VERSION ""

NS_ :

BS_:

BU_: BSM BSM2 CADM CVADAS ECM EPS EVCU2 ORC
BO_ 205 BRAKE_FD_6: 64 BSM
 SG_ Cmnd_TotBrkFrict_AxleTorq : 126|15@0+ (2,0) [0|65532] "Nm" EVCU2
 SG_ CRC_BRAKE_FD_6 : 447|8@0+ (1,0) [0|255] "-" ECM,EVCU2
 SG_ DriverReq_AxleTrq_Enabled_BSM : 175|4@0+ (1,0) [0|15] "" CVADAS,ECM,EVCU2
 SG_ DriverRequested_AxleTrq_BSM : 159|16@0+ (2,-65534) [-65534|65536] "Nm" ECM,EVCU2
 SG_ DrvrIntd_TotalBrk_AxleTorq : 142|15@0+ (2,0) [0|65532] "Nm" EVCU2
 SG_ FrontAxle_Max_Rq_BSM : 55|1@0+ (1,0) [0|1] "" EVCU2
 SG_ FrontAxle_Min_Rq_BSM : 54|1@0+ (1,0) [0|1] "" EVCU2
 SG_ FrontAxle_Rq_BSM : 63|16@0+ (2,-65534) [-65534|65536] "Nm" EVCU2
 SG_ MessageCounter_BRAKE_FD_6 : 435|4@0+ (1,0) [0|15] "-" ECM,EVCU2
 SG_ RearAxle_Max_Rq_BSM : 53|1@0+ (1,0) [0|1] "" EVCU2
 SG_ RearAxle_Min_Rq_BSM : 52|1@0+ (1,0) [0|1] "" EVCU2
 SG_ RearAxle_Rq_BSM : 79|16@0+ (2,-65534) [-65534|65536] "Nm" EVCU2
 SG_ TotalAxle_Max_Rq_BSM : 51|1@0+ (1,0) [0|1] "" ECM,EVCU2
 SG_ TotalAxle_Min_Rq_BSM : 50|1@0+ (1,0) [0|1] "" ECM,EVCU2
 SG_ TotalAxle_Rq_BSM : 95|16@0+ (2,-65534) [-65534|65536] "Nm" ECM,EVCU2

BO_ 514 BRAKE_FD_7: 32 BSM
 SG_ AEB_Type_Brk : 67|4@0+ (1,0) [0|14] "-" BSM2,CADM,ORC
 SG_ Brake_OpStat_Prim : 82|3@0+ (1,0) [0|5] "" CADM,ORC
 SG_ BrakePdlPosn : 63|8@0+ (0.4,0) [0|100] "%" BSM2,CADM,ECM,EVCU2
 SG_ BrkPdl_Flt : 86|1@0+ (1,0) [0|1] "-" CADM,ECM,EVCU2
 SG_ BrkPdl_Stat : 85|2@0+ (1,0) [0|2] "-" BSM2,CADM,CVADAS,ECM,EVCU2
 SG_ BSM_HEALTH_CHECK : 7|8@0+ (1,0) [0|255] "" BSM2
 SG_ BSM_OpStat : 74|3@0+ (1,0) [0|5] "" BSM2,CADM
 SG_ CRC_BRAKE7 : 191|8@0+ (1,0) [0|255] "-" BSM2,CADM,EVCU2
 SG_ MessageCounter_BRAKE7 : 179|4@0+ (1,0) [0|15] "-" BSM2,CADM,EVCU2
 SG_ PAM_Brk_Rq_RspSts : 28|2@0+ (1,0) [0|3] "-" CVADAS

BO_ 257 BRAKE2_FD_1: 64 BSM2
 SG_ ABSActive_B2 : 37|1@0+ (1,0) [0|1] "" CADM
 SG_ Brk_Stat_B2 : 71|2@0+ (1,0) [0|2] "" CADM
 SG_ CRC_BRAKE2_1 : 447|8@0+ (1,0) [0|255] "-" CADM,CVADAS,EPS,ORC
 SG_ Ft_RrAxleCoupling_TrqRq_B2 : 143|8@0+ (12,0) [0|3060] "Nm" Vector__XXX
 SG_ Ft_RrTrqCoupling_ModeRq_B2 : 158|2@0+ (1,0) [0|3] "-" Vector__XXX
 SG_ Inlet_Pressure_Pos : 98|2@0+ (1,0) [0|2] "" CADM
 SG_ LHF_FastPulseCounter_B2 : 87|8@0+ (1,0) [0|255] "pulse" CADM
 SG_ LHF_Spin_B2 : 39|2@0+ (1,0) [0|3] "" CADM
 SG_ LHF_WheelSensorFailSts_B2 : 53|1@0+ (1,0) [0|1] "" CADM
 SG_ LHFWheelSpeed_B2 : 52|13@0+ (0.0625,0) [0|511.875] "Km/h" CADM
 SG_ MessageCounter_BRAKE2_1 : 435|4@0+ (1,0) [0|15] "-" CADM,CVADAS,EPS,ORC
 SG_ R_DIFF_TRQ_RQ_B2 : 151|9@0+ (10,0) [0|5100] "Nm" Vector__XXX
 SG_ Rear_Diff_BSM_RQ_B2 : 156|2@0+ (1,0) [0|2] "-" Vector__XXX
 SG_ RHF_FastPulseCounter_B2 : 95|8@0+ (1,0) [0|255] "pulse" CADM
 SG_ RHF_Spin_B2 : 55|2@0+ (1,0) [0|3] "" CADM
 SG_ RHF_WheelSensorFailSts_B2 : 69|1@0+ (1,0) [0|1] "" CADM
 SG_ RHFWheelSpeed_B2 : 68|13@0+ (0.0625,0) [0|511.875] "Km/h" CADM
 SG_ VehicleSpeedVSOSig_B2 : 36|13@0+ (0.0625,0) [0|511.875] "Km/h" CADM,CVADAS,EPS

BO_ 524 BRAKE2_FD_2: 32 BSM2
 SG_ AEB_Type_Brk_B2 : 43|4@0+ (1,0) [0|15] "" CADM
 SG_ Brake_OpStat_Sec : 53|3@0+ (1,0) [0|5] "" CADM
 SG_ BrkTrq_B2 : 6|15@0+ (3,0) [0|98301] "Nm" CADM
 SG_ BSM2_HEALTH_CHECK : 63|8@0+ (1,0) [0|255] "" BSM
 SG_ BSM2_OpStat : 50|3@0+ (1,0) [0|5] "" BSM,CADM
 SG_ CRC_BRAKE2_2 : 191|8@0+ (1,0) [0|255] "-" BSM,CADM,ORC
 SG_ MessageCounter_BRAKE2_2 : 179|4@0+ (1,0) [0|15] "-" BSM,CADM,ORC
 SG_ VehicleStandStillSts_B2 : 47|2@0+ (1,0) [0|2] "" BSM,CADM

BO_ 1156 BRAKE2_FD_3: 32 BSM2
 SG_ ABSFailSts_B2 : 7|1@0+ (1,0) [0|1] "" CADM
 SG_ CRC_BRAKE2_3 : 191|8@0+ (1,0) [0|255] "-" CADM,ORC
 SG_ MessageCounter_BRAKE2_3 : 179|4@0+ (1,0) [0|15] "-" CADM,ORC
 SG_ RollsModeAct_B2 : 6|1@0+ (1,0) [0|1] "" CADM

BO_ 275 CVPAM_FD_Control: 32 CVADAS
 SG_ CRC_CVPAM_FD_Control : 191|8@0+ (1,0) [0|255] "-" BSM,EPS
 SG_ ManoeuvrePhase : 149|1@0+ (1,0) [0|1] "-" EPS
 SG_ MessageCounter_CVPAM_FD_Control : 179|4@0+ (1,0) [0|15] "-" BSM,EPS
 SG_ ParkingGearShiftReq : 164|3@0+ (1,0) [0|6] "-" BSM
 SG_ PPPA_AccelMax : 116|5@0+ (0.1,0) [0|3.1] "m/s2" BSM
 SG_ PPPA_AccelMin : 108|5@0+ (0.1,0) [0|3.1] "m/s2" BSM
 SG_ PPPA_DecelMax : 100|5@0+ (0.1,0) [0|3.1] "m/s2" BSM
 SG_ PPPA_DecelMin : 92|5@0+ (0.1,0) [0|3.1] "m/s2" BSM
 SG_ PPPA_Interface_BSM : 182|2@0+ (1,0) [0|2] "-" BSM
 SG_ PPPA_JerkAccelMax : 85|6@0+ (0.05,0) [0|3.15] "m/s3" BSM
 SG_ PPPA_JerkAccelMin : 77|6@0+ (0.05,0) [0|3.15] "m/s3" BSM
 SG_ PPPA_JerkDecelMax : 69|6@0+ (0.05,0) [0|3.15] "m/s3" BSM
 SG_ PPPA_JerkDecelMin : 61|6@0+ (0.05,0) [0|3.15] "m/s3" BSM
 SG_ PPPA_MaxSpeed : 127|8@0+ (0.0625,0) [0|15.875] "kph" BSM
 SG_ PPPA_StandstillRqst : 180|1@0+ (1,0) [0|1] "-" BSM
 SG_ PPPA_TargetDistance : 129|10@0+ (1,0) [0|1022] "cm" BSM
 SG_ RR_PAM_Brk_RqSts : 150|1@0+ (1,0) [0|1] "-" BSM
 SG_ RR_PAM_Dist : 161|10@0+ (1,0) [0|1022] "cm" BSM
 SG_ SPM_Lat_Ctrl_RequestSts : 148|2@0+ (1,0) [0|2] "-" EPS,ORC
 SG_ TorqueOverlaySteeringReq_SPM : 146|11@0+ (0.0078125,-8) [-8|7.9921875] "Nm" EPS,ORC

BO_ 726 CVPAM_FD_Data: 64 CVADAS
 SG_ CRC_CVPAM_FD_Data : 447|8@0+ (1,0) [0|255] "-" CADM
 SG_ MessageCounter_CVPAM_FD_Data : 435|4@0+ (1,0) [0|15] "-" CADM

BO_ 727 CVPAM_FD_Data2: 64 CVADAS
 SG_ CRC_CVPAM_FD_Data2 : 447|8@0+ (1,0) [0|255] "-" CADM
 SG_ MessageCounter_CVPAM_FD_Data2 : 435|4@0+ (1,0) [0|15] "-" CADM

BO_ 950 CVPAM_FD_Info: 32 CVADAS
 SG_ ParkingManeuverActive : 66|3@0+ (1,0) [0|6] "-" BSM

BO_ 1054 ENGINE_FD_1: 32 ECM
 SG_ CRC_ENGINE1 : 191|8@0+ (1,0) [0|255] "-" CADM
 SG_ MessageCounter_ENGINE1 : 179|4@0+ (1,0) [0|15] "-" CADM
 SG_ ThermalManagementActive_W : 1|1@0+ (1,0) [0|1] "-" CADM

BO_ 262 ENGINE_FD_2: 64 ECM
 SG_ CRC_ENGINE2 : 447|8@0+ (1,0) [0|255] "-" BSM,CADM,CVADAS,EPS
 SG_ ECM_LHOM_W : 188|1@0+ (1,0) [0|1] "-" CADM
 SG_ EngineSpeed_W : 21|14@0+ (1,0) [0|16382] "1/min" BSM,CADM,EPS
 SG_ EngineSts_W : 87|2@0+ (1,0) [0|3] "-" BSM,CADM,CVADAS
 SG_ ESS_ENG_ST_W : 175|4@0+ (1,0) [0|15] "-" BSM,CADM,CVADAS,EPS
 SG_ GasPedalPosition_W : 143|8@0+ (0.392,0) [0|99.568] "%" BSM
 SG_ GasPedalPositionFailSts_W : 169|1@0+ (1,0) [0|1] "-" BSM,CADM
 SG_ LV12PwrFreeRq_W : 176|1@0+ (1,0) [0|1] "-" Vector__XXX
 SG_ MessageCounter_ENGINE2 : 435|4@0+ (1,0) [0|15] "-" BSM,CADM,CVADAS,EPS
 SG_ PowertrainPrplsnActv : 181|1@0+ (1,0) [0|1] "" BSM,CADM

BO_ 1036 ENGINE_FD_3: 32 ECM
 SG_ CRC_ENGINE3 : 191|8@0+ (1,0) [0|255] "-" BSM
 SG_ MessageCounter_ENGINE3 : 179|4@0+ (1,0) [0|15] "-" BSM

BO_ 518 ENGINE_FD_5: 32 ECM
 SG_ CRC_ENGINE5 : 191|8@0+ (1,0) [0|255] "-" BSM,BSM2,CADM
 SG_ MessageCounter_ENGINE5 : 179|4@0+ (1,0) [0|15] "-" BSM,BSM2,CADM
 SG_ PdlPosActual : 87|8@0+ (0.4,0) [0|100] "%" BSM,BSM2,CADM,CVADAS
 SG_ RPMOverRev_W : 115|1@0+ (1,0) [0|1] "-" CADM

BO_ 1448 ENGINE_FD_7: 32 ECM
 SG_ ECM_THA_Resp : 73|2@0+ (1,0) [0|2] "-" CVADAS
 SG_ ECM_TRSC_Resp : 7|2@0+ (1,0) [0|2] "-" CVADAS

BO_ 264 EPS_FD_1: 32 EPS
 SG_ CRC_EPS1 : 191|8@0+ (1,0) [0|255] "-" BSM,CADM,CVADAS,ORC
 SG_ ElectricSteeringFailSts : 37|1@0+ (1,0) [0|1] "-" Vector__XXX
 SG_ EngineFanRequestActivation : 38|1@0+ (1,0) [0|1] "-" Vector__XXX
 SG_ EPS_ADAS_IMC_Fault : 69|1@0+ (1,0) [0|1] "" CADM
 SG_ EPS_AsstStat : 55|3@0+ (1,0) [0|6] "-" CADM
 SG_ EPS_Curr : 87|8@0+ (1,-50) [-50|204] "Amp" Vector__XXX
 SG_ EPS_Hands_On_Sts : 67|1@0+ (1,0) [0|1] "-" CADM,ORC
 SG_ EPS_HandsOnRecognition : 22|1@0+ (1,0) [0|1] "-" CVADAS,ORC
 SG_ EPSMotorTorque : 66|11@0+ (0.004882815,-5) [-5|4.99023949] "Nm" CADM,ORC
 SG_ ESA_LAT_CTRL_ResponseSts : 135|3@0+ (1,0) [0|6] "-" BSM,CADM
 SG_ HAS_LAT_CTRL_ResponseSts : 101|3@0+ (1,0) [0|7] "-" CADM,ORC
 SG_ LKA_LAT_CTRL_ResponseSts : 71|2@0+ (1,0) [0|3] "-" CADM,ORC
 SG_ LwsAngle : 7|16@0+ (0.1,-720) [-720|720] "°" BSM,CADM,CVADAS,EVCU2
 SG_ LwsAngleType : 52|2@0+ (1,0) [0|2] "-" BSM,CADM,CVADAS
 SG_ LwsCalibration : 36|1@0+ (1,0) [0|1] "-" BSM,CADM
 SG_ LwsSpeed : 19|12@0+ (1,-2000) [-2000|2094] "°/s" CADM,CVADAS,EVCU2
 SG_ MessageCounter_EPS1 : 179|4@0+ (1,0) [0|15] "-" BSM,CADM,CVADAS,ORC
 SG_ SPM_Lat_Ctrl_ResponseSts : 103|2@0+ (1,0) [0|3] "-" CVADAS,ORC
 SG_ Steering_Column_Torque : 50|11@0+ (0.0078125,-8) [-8|7.984375] "NM" CADM,CVADAS
 SG_ Steering_OpStat_Prim : 111|3@0+ (1,0) [0|5] "" CADM,ORC
 SG_ SteeringVibration_Fault : 39|1@0+ (1,0) [0|1] "-" CADM
 SG_ SteeringVibration_Status : 23|1@0+ (1,0) [0|1] "-" CADM,ORC

BO_ 1056 EPS_FD_2: 32 EPS
 SG_ EPS_MODE_STAT : 7|3@0+ (1,0) [0|3] "" Vector__XXX
 SG_ EPS_SteeringTouchStat : 4|1@0+ (1,0) [0|1] "" CVADAS
 SG_ EPS_SteeringTouq_Resp : 3|2@0+ (1,0) [0|1] "" CVADAS
 SG_ EPS_THA_DriverTorqueOverride : 1|2@0+ (1,0) [0|1] "" CVADAS
 SG_ EPS_THA_SteeringTorqueResp : 13|3@0+ (1,0) [0|6] "" CVADAS
 SG_ EPS_Warn_Disp_Rq : 87|3@0+ (1,0) [0|3] "" Vector__XXX
 SG_ THA_SteeringTouchStat : 15|2@0+ (1,0) [0|1] "" CVADAS

BO_ 276 HYBRID_POWERTRAIN1: 64 EVCU2
 SG_ DriveModeSts_EPT : 427|4@0+ (1,0) [0|14] "-" Vector__XXX

BO_ 1580 HYBRID_POWERTRAIN6: 32 EVCU2
 SG_ Motor1_RPM : 7|16@0+ (1,-32768) [-32768|32767] "RPM" Vector__XXX
 SG_ Motor2_RPM : 23|16@0+ (1,-32768) [-32768|32767] "RPM" Vector__XXX

BO_ 1626 IMPACT_INFO: 32 ORC
 SG_ IMPACT_B : 84|1@0+ (1,0) [0|1] "-" Vector__XXX
 SG_ IMPACT_C : 85|1@0+ (1,0) [0|1] "-" Vector__XXX
 SG_ IMPACT_F : 88|1@0+ (1,0) [0|1] "-" Vector__XXX
 SG_ IMPACT_I : 91|1@0+ (1,0) [0|1] "-" Vector__XXX
 SG_ IMPACT_K : 92|1@0+ (1,0) [0|1] "-" Vector__XXX
 SG_ IMPACT_M : 94|1@0+ (1,0) [0|1] "-" Vector__XXX
 SG_ IMPACTCommand : 80|1@0+ (1,0) [0|1] "-" CADM,EVCU2
 SG_ IMPACTConfirm : 81|1@0+ (1,0) [0|1] "-" CADM,EVCU2
 SG_ IMPACTFailSts : 82|1@0+ (1,0) [0|1] "-" Vector__XXX
 SG_ IMPACTThreshold : 103|1@0+ (1,0) [0|1] "-" Vector__XXX

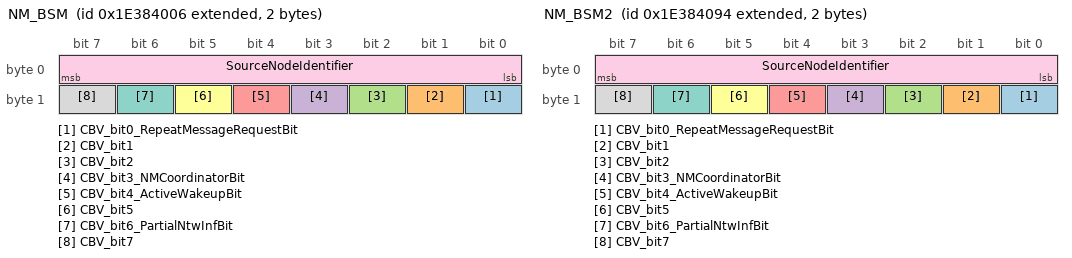
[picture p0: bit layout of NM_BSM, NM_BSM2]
BO_ 2654486534 NM_BSM: 2 BSM
 SG_ CBV_bit0_RepeatMessageRequestBit : 8|1@0+ (1,0) [0|1] "" BSM2,CADM,CVADAS,ECM,EPS,ORC
 SG_ CBV_bit1 : 9|1@0+ (1,0) [0|1] "" BSM2,CADM,CVADAS,ECM,EPS,ORC
 SG_ CBV_bit2 : 10|1@0+ (1,0) [0|1] "" BSM2,CADM,CVADAS,ECM,EPS,ORC
 SG_ CBV_bit3_NMCoordinatorBit : 11|1@0+ (1,0) [0|1] "" BSM2,CADM,CVADAS,ECM,EPS,ORC
 SG_ CBV_bit4_ActiveWakeupBit : 12|1@0+ (1,0) [0|1] "" BSM2,CADM,CVADAS,ECM,EPS,ORC
 SG_ CBV_bit5 : 13|1@0+ (1,0) [0|1] "" BSM2,CADM,CVADAS,ECM,EPS,ORC
 SG_ CBV_bit6_PartialNtwInfBit : 14|1@0+ (1,0) [0|1] "" BSM2,CADM,CVADAS,ECM,EPS,ORC
 SG_ CBV_bit7 : 15|1@0+ (1,0) [0|1] "" BSM2,CADM,CVADAS,ECM,EPS,ORC
 SG_ SourceNodeIdentifier : 7|8@0+ (1,0) [0|255] "-" BSM2,CADM,CVADAS,ECM,EPS,ORC

BO_ 2654486676 NM_BSM2: 2 BSM2
 SG_ CBV_bit0_RepeatMessageRequestBit : 8|1@0+ (1,0) [0|1] "" BSM,CADM,CVADAS,ECM,EPS,ORC
 SG_ CBV_bit1 : 9|1@0+ (1,0) [0|1] "" BSM,CADM,CVADAS,ECM,EPS,ORC
 SG_ CBV_bit2 : 10|1@0+ (1,0) [0|1] "" BSM,CADM,CVADAS,ECM,EPS,ORC
 SG_ CBV_bit3_NMCoordinatorBit : 11|1@0+ (1,0) [0|1] "" BSM,CADM,CVADAS,ECM,EPS,ORC
 SG_ CBV_bit4_ActiveWakeupBit : 12|1@0+ (1,0) [0|1] "" BSM,CADM,CVADAS,ECM,EPS,ORC
 SG_ CBV_bit5 : 13|1@0+ (1,0) [0|1] "" BSM,CADM,CVADAS,ECM,EPS,ORC
 SG_ CBV_bit6_PartialNtwInfBit : 14|1@0+ (1,0) [0|1] "" BSM,CADM,CVADAS,ECM,EPS,ORC
 SG_ CBV_bit7 : 15|1@0+ (1,0) [0|1] "" BSM,CADM,CVADAS,ECM,EPS,ORC
 SG_ SourceNodeIdentifier : 7|8@0+ (1,0) [0|255] "-" BSM,CADM,CVADAS,ECM,EPS,ORC

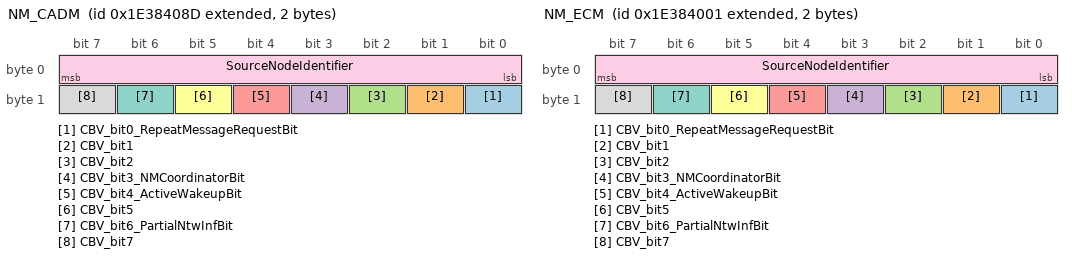
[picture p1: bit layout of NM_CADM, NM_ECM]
BO_ 2654486669 NM_CADM: 2 CADM
 SG_ CBV_bit0_RepeatMessageRequestBit : 8|1@0+ (1,0) [0|1] "" BSM,BSM2,CVADAS,ECM,EPS,ORC
 SG_ CBV_bit1 : 9|1@0+ (1,0) [0|1] "" BSM,BSM2,CVADAS,ECM,EPS,ORC
 SG_ CBV_bit2 : 10|1@0+ (1,0) [0|1] "" BSM,BSM2,CVADAS,ECM,EPS,ORC
 SG_ CBV_bit3_NMCoordinatorBit : 11|1@0+ (1,0) [0|1] "" BSM,BSM2,CVADAS,ECM,EPS,ORC
 SG_ CBV_bit4_ActiveWakeupBit : 12|1@0+ (1,0) [0|1] "" BSM,BSM2,CVADAS,ECM,EPS,ORC
 SG_ CBV_bit5 : 13|1@0+ (1,0) [0|1] "" BSM,BSM2,CVADAS,ECM,EPS,ORC
 SG_ CBV_bit6_PartialNtwInfBit : 14|1@0+ (1,0) [0|1] "" BSM,BSM2,CVADAS,ECM,EPS,ORC
 SG_ CBV_bit7 : 15|1@0+ (1,0) [0|1] "" BSM,BSM2,CVADAS,ECM,EPS,ORC
 SG_ SourceNodeIdentifier : 7|8@0+ (1,0) [0|255] "-" BSM,BSM2,CVADAS,ECM,EPS,ORC

BO_ 2654486529 NM_ECM: 2 ECM
 SG_ CBV_bit0_RepeatMessageRequestBit : 8|1@0+ (1,0) [0|1] "" BSM,BSM2,CADM,CVADAS,EPS,ORC
 SG_ CBV_bit1 : 9|1@0+ (1,0) [0|1] "" BSM,BSM2,CADM,CVADAS,EPS,ORC
 SG_ CBV_bit2 : 10|1@0+ (1,0) [0|1] "" BSM,BSM2,CADM,CVADAS,EPS,ORC
 SG_ CBV_bit3_NMCoordinatorBit : 11|1@0+ (1,0) [0|1] "" BSM,BSM2,CADM,CVADAS,EPS,ORC
 SG_ CBV_bit4_ActiveWakeupBit : 12|1@0+ (1,0) [0|1] "" BSM,BSM2,CADM,CVADAS,EPS,ORC
 SG_ CBV_bit5 : 13|1@0+ (1,0) [0|1] "" BSM,BSM2,CADM,CVADAS,EPS,ORC
 SG_ CBV_bit6_PartialNtwInfBit : 14|1@0+ (1,0) [0|1] "" BSM,BSM2,CADM,CVADAS,EPS,ORC
 SG_ CBV_bit7 : 15|1@0+ (1,0) [0|1] "" BSM,BSM2,CADM,CVADAS,EPS,ORC
 SG_ SourceNodeIdentifier : 7|8@0+ (1,0) [0|255] "-" BSM,BSM2,CADM,CVADAS,EPS,ORC

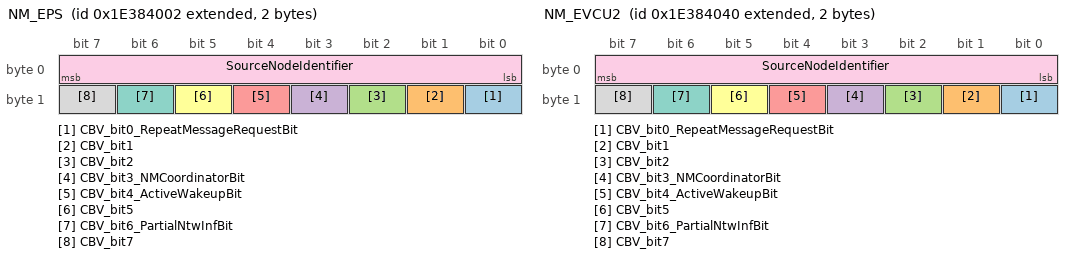
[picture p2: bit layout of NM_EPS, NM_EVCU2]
BO_ 2654486530 NM_EPS: 2 EPS
 SG_ CBV_bit0_RepeatMessageRequestBit : 8|1@0+ (1,0) [0|1] "" BSM,BSM2,CADM,CVADAS,ECM,ORC
 SG_ CBV_bit1 : 9|1@0+ (1,0) [0|1] "" BSM,BSM2,CADM,CVADAS,ECM,ORC
 SG_ CBV_bit2 : 10|1@0+ (1,0) [0|1] "" BSM,BSM2,CADM,CVADAS,ECM,ORC
 SG_ CBV_bit3_NMCoordinatorBit : 11|1@0+ (1,0) [0|1] "" BSM,BSM2,CADM,CVADAS,ECM,ORC
 SG_ CBV_bit4_ActiveWakeupBit : 12|1@0+ (1,0) [0|1] "" BSM,BSM2,CADM,CVADAS,ECM,ORC
 SG_ CBV_bit5 : 13|1@0+ (1,0) [0|1] "" BSM,BSM2,CADM,CVADAS,ECM,ORC
 SG_ CBV_bit6_PartialNtwInfBit : 14|1@0+ (1,0) [0|1] "" BSM,BSM2,CADM,CVADAS,ECM,ORC
 SG_ CBV_bit7 : 15|1@0+ (1,0) [0|1] "" BSM,BSM2,CADM,CVADAS,ECM,ORC
 SG_ SourceNodeIdentifier : 7|8@0+ (1,0) [0|255] "-" BSM,BSM2,CADM,CVADAS,ECM,ORC

BO_ 2654486592 NM_EVCU2: 2 EVCU2
 SG_ CBV_bit0_RepeatMessageRequestBit : 8|1@0+ (1,0) [0|1] "" BSM,BSM2,CADM,CVADAS,ECM,EPS,ORC
 SG_ CBV_bit1 : 9|1@0+ (1,0) [0|1] "" BSM,BSM2,CADM,CVADAS,ECM,EPS,ORC
 SG_ CBV_bit2 : 10|1@0+ (1,0) [0|1] "" BSM,BSM2,CADM,CVADAS,ECM,EPS,ORC
 SG_ CBV_bit3_NMCoordinatorBit : 11|1@0+ (1,0) [0|1] "" BSM,BSM2,CADM,CVADAS,ECM,EPS,ORC
 SG_ CBV_bit4_ActiveWakeupBit : 12|1@0+ (1,0) [0|1] "" BSM,BSM2,CADM,CVADAS,ECM,EPS,ORC
 SG_ CBV_bit5 : 13|1@0+ (1,0) [0|1] "" BSM,BSM2,CADM,CVADAS,ECM,EPS,ORC
 SG_ CBV_bit6_PartialNtwInfBit : 14|1@0+ (1,0) [0|1] "" BSM,BSM2,CADM,CVADAS,ECM,EPS,ORC
 SG_ CBV_bit7 : 15|1@0+ (1,0) [0|1] "" BSM,BSM2,CADM,CVADAS,ECM,EPS,ORC
 SG_ SourceNodeIdentifier : 7|8@0+ (1,0) [0|255] "-" BSM,BSM2,CADM,CVADAS,ECM,EPS,ORC

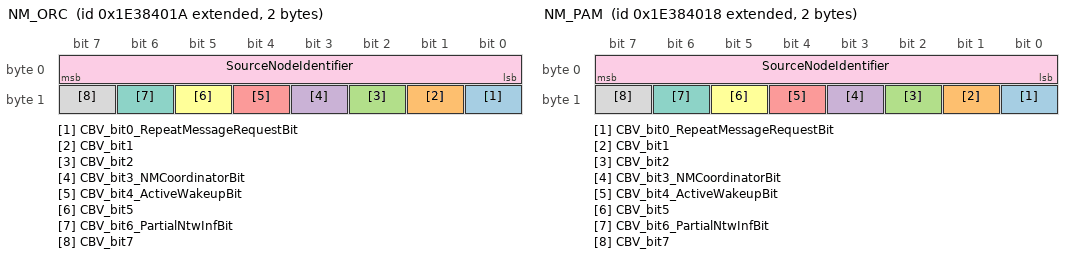
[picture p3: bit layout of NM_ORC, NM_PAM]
BO_ 2654486554 NM_ORC: 2 ORC
 SG_ CBV_bit0_RepeatMessageRequestBit : 8|1@0+ (1,0) [0|1] "" BSM,BSM2,CADM,CVADAS,ECM,EPS
 SG_ CBV_bit1 : 9|1@0+ (1,0) [0|1] "" BSM,BSM2,CADM,CVADAS,ECM,EPS
 SG_ CBV_bit2 : 10|1@0+ (1,0) [0|1] "" BSM,BSM2,CADM,CVADAS,ECM,EPS
 SG_ CBV_bit3_NMCoordinatorBit : 11|1@0+ (1,0) [0|1] "" BSM,BSM2,CADM,CVADAS,ECM,EPS
 SG_ CBV_bit4_ActiveWakeupBit : 12|1@0+ (1,0) [0|1] "" BSM,BSM2,CADM,CVADAS,ECM,EPS
 SG_ CBV_bit5 : 13|1@0+ (1,0) [0|1] "" BSM,BSM2,CADM,CVADAS,ECM,EPS
 SG_ CBV_bit6_PartialNtwInfBit : 14|1@0+ (1,0) [0|1] "" BSM,BSM2,CADM,CVADAS,ECM,EPS
 SG_ CBV_bit7 : 15|1@0+ (1,0) [0|1] "" BSM,BSM2,CADM,CVADAS,ECM,EPS
 SG_ SourceNodeIdentifier : 7|8@0+ (1,0) [0|255] "-" BSM,BSM2,CADM,CVADAS,ECM,EPS

BO_ 2654486552 NM_PAM: 2 CVADAS
 SG_ CBV_bit0_RepeatMessageRequestBit : 8|1@0+ (1,0) [0|1] "" BSM,BSM2,CADM,ECM,EPS,ORC
 SG_ CBV_bit1 : 9|1@0+ (1,0) [0|1] "" BSM,BSM2,CADM,ECM,EPS,ORC
 SG_ CBV_bit2 : 10|1@0+ (1,0) [0|1] "" BSM,BSM2,CADM,ECM,EPS,ORC
 SG_ CBV_bit3_NMCoordinatorBit : 11|1@0+ (1,0) [0|1] "" BSM,BSM2,CADM,ECM,EPS,ORC
 SG_ CBV_bit4_ActiveWakeupBit : 12|1@0+ (1,0) [0|1] "" BSM,BSM2,CADM,ECM,EPS,ORC
 SG_ CBV_bit5 : 13|1@0+ (1,0) [0|1] "" BSM,BSM2,CADM,ECM,EPS,ORC
 SG_ CBV_bit6_PartialNtwInfBit : 14|1@0+ (1,0) [0|1] "" BSM,BSM2,CADM,ECM,EPS,ORC
 SG_ CBV_bit7 : 15|1@0+ (1,0) [0|1] "" BSM,BSM2,CADM,ECM,EPS,ORC
 SG_ SourceNodeIdentifier : 7|8@0+ (1,0) [0|255] "-" BSM,BSM2,CADM,ECM,EPS,ORC

BO_ 611 ORC_FD_1: 32 ORC
 SG_ CRC_ORC1 : 191|8@0+ (1,0) [0|255] "-" BSM,CADM
 SG_ MessageCounter_ORC1 : 179|4@0+ (1,0) [0|15] "-" BSM,CADM
 SG_ SBR1RowDriverSeatSts : 94|2@0+ (1,0) [0|2] "-" BSM,CADM,EVCU2

BO_ 1954 ORC_FD_2: 32 ORC
 SG_ CRC_ORC2 : 191|8@0+ (1,0) [0|255] "-" BSM
 SG_ MessageCounter_ORC2 : 179|4@0+ (1,0) [0|15] "-" BSM
 SG_ ORCIdentification : 87|32@0+ (1,0) [0|4294967295] "-" BSM

BO_ 274 ORC_FD_3: 32 ORC
 SG_ CRC_ORC3 : 191|8@0+ (1,0) [0|255] "-" BSM,CADM
 SG_ InternalError : 165|1@0+ (1,0) [0|1] "-" BSM,CADM
 SG_ LatAcceleration : 147|12@0+ (0.02,-40.96) [-40.96|40.92] "m/s^2" BSM,CADM,EVCU2
 SG_ LatAccelerationFailSts : 182|1@0+ (1,0) [0|1] "-" BSM,CADM,EVCU2
 SG_ LongAcceleration : 131|12@0+ (0.02,-40.96) [-40.96|40.92] "m/s^2" BSM,CADM,EVCU2
 SG_ LongAccelerationFailSts : 183|1@0+ (1,0) [0|1] "-" BSM,CADM,EVCU2
 SG_ MessageCounter_ORC3 : 179|4@0+ (1,0) [0|15] "-" BSM,CADM
 SG_ YawRate : 163|12@0+ (0.08,-163.84) [-163.84|163.68] "deg/s" BSM,CADM,EVCU2
 SG_ YawRate_HR : 10|3@0+ (0.02,0) [0|0.06] "deg/s" CADM
 SG_ YawRate_HR_Sign : 7|1@0+ (1,0) [0|1] "deg/s" CADM
 SG_ YawRateFailSts : 181|1@0+ (1,0) [0|1] "-" BSM,CADM,EVCU2

BO_ 263 PT_SYSTEM_FD_1: 64 ECM
 SG_ CRC_PT_SYSTEM_FD_1 : 447|8@0+ (1,0) [0|255] "-" BSM,CADM,ECM
 SG_ DriveReady_PT : 166|1@0+ (1,0) [0|1] "" Vector__XXX
 SG_ EVCU2_THA_Resp : 220|2@0+ (1,0) [0|3] "" CVADAS
 SG_ GasPedalPosition_PT : 31|8@0+ (0.392,0) [0|99.96] "%" BSM
 SG_ GasPedalPositionFailSts_PT : 145|1@0+ (1,0) [0|1] "" CADM
 SG_ GearEngaged_PT : 132|4@0+ (1,0) [0|15] "" BSM2,EPS
 SG_ GearEngagedForDisplay_PT : 12|5@0+ (1,0) [0|31] "" CVADAS,EPS
 SG_ MessageCounter_PT_SYSTEM_FD_1 : 435|4@0+ (1,0) [0|15] "-" BSM,CADM,ECM
 SG_ PdlPosActual_PT : 39|8@0+ (0.4,0) [0|102] "%" BSM,BSM2,CADM,CVADAS
 SG_ PowertrainPrplsnActv_PT : 146|1@0+ (1,0) [0|1] "" BSM,CADM,CVADAS
 SG_ ShiftLeverPosition_PT : 51|4@0+ (1,0) [0|15] "" Vector__XXX
 SG_ TargetGear_PT : 55|4@0+ (1,0) [0|15] "" Vector__XXX

BO_ 255 PT_TORQUE_FD_1: 48 ECM
 SG_ ACC_NCC_TrqEnblRq_Allowed : 23|1@0+ (1,0) [0|1] "-" CADM
 SG_ Accel_Pedal_Override : 37|1@0+ (1,0) [0|1] "-" BSM,CADM,CVADAS
 SG_ CRC_PT_TORQUE_FD_1 : 319|8@0+ (1,0) [0|255] "-" BSM,CADM
 SG_ ESC_TrqEnblRq_Allowed : 38|1@0+ (1,0) [0|1] "-" Vector__XXX
 SG_ Front_AxleTorque_Static : 167|16@0+ (2,-65534) [-65534|65536] "Nm" Vector__XXX
 SG_ MessageCounter_PT_TORQUE_FD_1 : 307|4@0+ (1,0) [0|15] "-" BSM,CADM
 SG_ PPPA_TrqEnblRq_Allowed : 21|1@0+ (1,0) [0|1] "-" BSM,CVADAS
 SG_ Rear_AxleTorque_Static : 183|16@0+ (2,-65534) [-65534|65536] "Nm" Vector__XXX
 SG_ RRCC_TrqEnblRq_Allowed : 39|1@0+ (1,0) [0|1] "-" CADM
 SG_ SSC_TrqEnblRq_Allowed : 22|1@0+ (1,0) [0|1] "-" Vector__XXX
 SG_ SumTorque_DrvReqMod : 20|13@0+ (0.25,-500) [-500|1547.5] "Nm" Vector__XXX
 SG_ SumTorqueExp : 34|11@0+ (1,-500) [-500|1546] "Nm" Vector__XXX
 SG_ SumTorqueMax : 50|11@0+ (1,-500) [-500|1546] "Nm" Vector__XXX
 SG_ SumTorqueMin : 66|11@0+ (1,-500) [-500|1546] "Nm" Vector__XXX
 SG_ SumTorqueSel_D_TTC : 82|11@0+ (1,-500) [-500|1546] "Nm" Vector__XXX
 SG_ SumTorqueStatic : 98|11@0+ (1,-500) [-500|1546] "Nm" Vector__XXX
 SG_ Total_AxleTorque_Static : 151|16@0+ (2,-65534) [-65534|65536] "Nm" CADM

BO_ 1472 TRSCM_FD_1: 32 CVADAS
 SG_ CRC_TRSCM1 : 191|8@0+ (1,0) [0|255] "-" BSM,ECM,EPS
 SG_ MessageCounter_TRSCM1 : 179|4@0+ (1,0) [0|15] "-" BSM,ECM,EPS
 SG_ THA_EPB_Req : 95|2@0+ (1,0) [0|3] "" BSM
 SG_ THA_Speed_Limit : 85|5@0+ (1,0) [0|31] "" BSM,ECM,EPS,EVCU2
 SG_ THA_SpeedLimit_Req : 52|2@0+ (1,0) [0|3] "" BSM,ECM,EVCU2
 SG_ THA_STAT : 55|3@0+ (1,0) [0|6] "" BSM,ECM,EPS,EVCU2
 SG_ THA_SteeringDamping : 79|8@0+ (0.78125,0) [0|199.21875] "%" EPS
 SG_ THA_SteeringTorqueInfo : 63|11@0+ (0.0078125,-8) [-8|7.9921875] "" EPS
 SG_ THA_SteeringTorqueReq : 87|2@0+ (1,0) [0|3] "" EPS
 SG_ TRSC_SpeedLimit_Req : 15|4@0+ (1,0) [0|14] "" BSM,ECM
 SG_ TRSC_STAT : 7|3@0+ (1,0) [0|6] "" BSM,ECM,EPS
 SG_ TRSC_SteeringDamping : 23|8@0+ (0.78125,0) [0|199.21875] "%" EPS
 SG_ TRSC_SteeringTorqueInfo : 31|11@0+ (0.0078125,-8) [-8|7.9921875] "" EPS
 SG_ TRSC_SteeringTorqueReq : 11|2@0+ (1,0) [0|2] "" EPS
 SG_ TRSC_VehicleStop_Req : 36|2@0+ (1,0) [0|2] "" BSM

BO_TX_BU_ 1448 : ECM,EVCU2;
BO_TX_BU_ 263 : ECM,EVCU2;
BO_TX_BU_ 255 : ECM,EVCU2;
CM_ SG_ 205 Cmnd_TotBrkFrict_AxleTorq "Commanded Total Brake Friction torque in Axle domain";
CM_ SG_ 205 CRC_BRAKE_FD_6 "CRC according to SAE J1850 standard at each frame transmission.";
CM_ SG_ 205 DriverReq_AxleTrq_Enabled_BSM "It indicates the request to enable virtual driver torque interface for BSM driver functions";
CM_ SG_ 205 DriverRequested_AxleTrq_BSM "Virtual driver torque request from BSM";
CM_ SG_ 205 DrvrIntd_TotalBrk_AxleTorq "Total Brake Torque in Axle domain";
CM_ SG_ 205 FrontAxle_Max_Rq_BSM "Front axle traction torque max limit flag. Active = [1]";
CM_ SG_ 205 FrontAxle_Min_Rq_BSM "Front axle traction torque min limit flag. Active = [1]";
CM_ SG_ 205 FrontAxle_Rq_BSM "Front axle traction control torque request";
CM_ SG_ 205 MessageCounter_BRAKE_FD_6 "This signal is a counter used for safety checks strategies. This counter is incremented of 1 (one) unit at each frame transmission.";
CM_ SG_ 205 RearAxle_Max_Rq_BSM "Rear axle traction torque max limit  flag. Active = [1]";
CM_ SG_ 205 RearAxle_Min_Rq_BSM "Rear axle traction torque min limit  flag. Active = [1]";
CM_ SG_ 205 RearAxle_Rq_BSM "Rear axle traction control torque request";
CM_ SG_ 205 TotalAxle_Max_Rq_BSM "Combined axle traction torque max limit flag. Active = [1]";
CM_ SG_ 205 TotalAxle_Min_Rq_BSM "Combined axle traction torque min limit flag. Active = [1]";
CM_ SG_ 205 TotalAxle_Rq_BSM "Combined axle traction torque request";
CM_ SG_ 514 AEB_Type_Brk "AEB type brake signal";
CM_ SG_ 514 Brake_OpStat_Prim "Capability of the Braking system to perform deceleration and/or stability control as reported by primary actuator";
CM_ SG_ 514 BrakePdlPosn "Brake pedal travel sensor 0-100% (0 = upstop)";
CM_ SG_ 514 BrkPdl_Flt "Brake Pedal Fault is active, 1=Faulted";
CM_ SG_ 514 BrkPdl_Stat "Brake pedal state";
CM_ SG_ 514 BSM_HEALTH_CHECK "BSM_HEALTH_CHECK";
CM_ SG_ 514 BSM_OpStat "Capability of the primary brake control module to provide deceleration and/or stability control";
CM_ SG_ 514 CRC_BRAKE7 "CRC according to SAE J1850 standard at each frame transmission.";
CM_ SG_ 514 MessageCounter_BRAKE7 "This signal is a counter used for safety checks strategies. This counter is incremented of 1 (one) unit at each frame transmission.";
CM_ SG_ 514 PAM_Brk_Rq_RspSts "PAM Brake Request Response Status made by the BSM for Park Assist with Stop.";
CM_ SG_ 257 ABSActive_B2 "ABSActive_B2";
CM_ SG_ 257 Brk_Stat_B2 "Signifies a general braking event (both autonomous and driver requested) with the secondary brake control module";
CM_ SG_ 257 CRC_BRAKE2_1 "CRC according to SAE J1850 standard at each frame transmission.";
CM_ SG_ 257 Ft_RrAxleCoupling_TrqRq_B2 "Desired Torque for Center Diff";
CM_ SG_ 257 Ft_RrTrqCoupling_ModeRq_B2 "ESP Requested Center Differential State";
CM_ SG_ 257 Inlet_Pressure_Pos "Inlet Pressure Pos Indicates if the secondary brake control module detects upstream brake pressure";
CM_ SG_ 257 LHF_FastPulseCounter_B2 "LHF_FastPulseCounter_B2";
CM_ SG_ 257 LHF_Spin_B2 "LHF_Spin_B2";
CM_ SG_ 257 LHF_WheelSensorFailSts_B2 "LHF_WheelSensorFailSts_B2";
CM_ SG_ 257 LHFWheelSpeed_B2 "LHFWheelSpeed_B2";
CM_ SG_ 257 MessageCounter_BRAKE2_1 "This signal is a counter used for safety checks strategies. This counter is incremented of 1 (one) unit at each frame transmission.";
CM_ SG_ 257 R_DIFF_TRQ_RQ_B2 "Desired Torque for Rear Diff.";
CM_ SG_ 257 Rear_Diff_BSM_RQ_B2 "ESP Requested Rear Differential State";
CM_ SG_ 257 RHF_FastPulseCounter_B2 "RHF_FastPulseCounter_B2";
CM_ SG_ 257 RHF_Spin_B2 "RHF_Spin_B2";
CM_ SG_ 257 RHF_WheelSensorFailSts_B2 "RHF_WheelSensorFailSts_B2";
CM_ SG_ 257 RHFWheelSpeed_B2 "RHFWheelSpeed_B2";
CM_ SG_ 257 VehicleSpeedVSOSig_B2 "VehicleSpeedVSOSig_B2";
CM_ SG_ 524 AEB_Type_Brk_B2 "AEB_Type_Brk_B2";
CM_ SG_ 524 Brake_OpStat_Sec "Capability of the Braking system to perform deceleration and/or stability control as reported by the secondary actuator.";
CM_ SG_ 524 BrkTrq_B2 "BrkTrq_B2";
CM_ SG_ 524 BSM2_HEALTH_CHECK "BSM2_HEALTH_CHECK";
CM_ SG_ 524 BSM2_OpStat "Capability of the secondary brake control module to provide deceleration and/or stability control";
CM_ SG_ 524 CRC_BRAKE2_2 "CRC according to SAE J1850 standard at each frame transmission.";
CM_ SG_ 524 MessageCounter_BRAKE2_2 "This signal is a counter used for safety checks strategies. This counter is incremented of 1 (one) unit at each frame transmission.";
CM_ SG_ 524 VehicleStandStillSts_B2 "VehicleStandStillSts_B2";
CM_ SG_ 1156 ABSFailSts_B2 "ABSFailSts_B2";
CM_ SG_ 1156 CRC_BRAKE2_3 "CRC according to SAE J1850 standard at each frame transmission.";
CM_ SG_ 1156 MessageCounter_BRAKE2_3 "This signal is a counter used for safety checks strategies. This counter is incremented of 1 (one) unit at each frame transmission.";
CM_ SG_ 1156 RollsModeAct_B2 "RollsModeAct_B2";
CM_ SG_ 275 CRC_CVPAM_FD_Control "CRC according to SAE J1850 standard at each frame transmission.";
CM_ SG_ 275 ManoeuvrePhase "It indicates the vehicle movement estimated by SPM during semiautomatic parking manoeuvre.";
CM_ SG_ 275 MessageCounter_CVPAM_FD_Control "This signal is a counter used for safety checks strategies. This counter is incremented of 1 (one) unit at each frame transmission.";
CM_ SG_ 275 ParkingGearShiftReq "CVPAM Request to autonomously shift gears";
CM_ SG_ 275 PPPA_AccelMax "Maximum acceleration during a fully autonomous parking maneuver";
CM_ SG_ 275 PPPA_AccelMin "Minimum acceleration during a fully autonomous parking maneuver";
CM_ SG_ 275 PPPA_DecelMax "Maximum deceleration (absolute value) during a fully autonomous parking maneuver";
CM_ SG_ 275 PPPA_DecelMin "Minimum deceleration (absolute value) during a fully autonomous parking maneuver";
CM_ SG_ 275 PPPA_Interface_BSM "Fully Autonomous Parking Interface status with CVPAM and BSM";
CM_ SG_ 275 PPPA_JerkAccelMax "Maximum accelerating jerk rate during a fully autonomous parking maneuver";
CM_ SG_ 275 PPPA_JerkAccelMin "Minimum accelerating jerk rate during a fully autonomous parking maneuver";
CM_ SG_ 275 PPPA_JerkDecelMax "Maximum decelerating jerk rate (absolute value) during a fully autonomous parking maneuver";
CM_ SG_ 275 PPPA_JerkDecelMin "Minimum decelerating jerk rate (absolute value) during a fully autonomous parking maneuver";
CM_ SG_ 275 PPPA_StandstillRqst "Request for vehicle standstill";
CM_ SG_ 275 RR_PAM_Brk_RqSts "PAM rear brake request";
CM_ SG_ 275 RR_PAM_Dist "Rear Distance to Nearest Obstacle";
CM_ SG_ 275 SPM_Lat_Ctrl_RequestSts "SPM Lat Ctrl Request Sts";
CM_ SG_ 275 TorqueOverlaySteeringReq_SPM "This signal indicates the value of the torque requested by the SPM torque overlay.";
CM_ SG_ 726 CRC_CVPAM_FD_Data "CRC according to SAE J1850 standard at each frame transmission.";
CM_ SG_ 726 MessageCounter_CVPAM_FD_Data "This signal is a counter used for safety checks strategies. This counter is incremented of 1 (one) unit at each frame transmission.";
CM_ SG_ 727 CRC_CVPAM_FD_Data2 "CRC according to SAE J1850 standard at each frame transmission.";
CM_ SG_ 727 MessageCounter_CVPAM_FD_Data2 "This signal is a counter used for safety checks strategies. This counter is incremented of 1 (one) unit at each frame transmission.";
CM_ SG_ 950 ParkingManeuverActive "Parking information active";
CM_ SG_ 1054 CRC_ENGINE1 "CRC according to SAE J1850 standard at each frame transmission.";
CM_ SG_ 1054 MessageCounter_ENGINE1 "This signal is a counter used for safety checks strategies. This counter is incremented of 1 (one) unit at each frame transmission.";
CM_ SG_ 1054 ThermalManagementActive_W "-";
CM_ SG_ 262 CRC_ENGINE2 "CRC according to SAE J1850 standard at each frame transmission.";
CM_ SG_ 262 ECM_LHOM_W "-";
CM_ SG_ 262 EngineSpeed_W "It gives information on C-CAN network about  engine speed";
CM_ SG_ 262 EngineSts_W "-";
CM_ SG_ 262 ESS_ENG_ST_W "ESS Engine State";
CM_ SG_ 262 GasPedalPosition_W "-";
CM_ SG_ 262 GasPedalPositionFailSts_W "-";
CM_ SG_ 262 LV12PwrFreeRq_W "-";
CM_ SG_ 262 MessageCounter_ENGINE2 "This signal is a counter used for safety checks strategies. This counter is incremented of 1 (one) unit at each frame transmission.";
CM_ SG_ 262 PowertrainPrplsnActv "Powertrain Propulsion Status.";
CM_ SG_ 1036 CRC_ENGINE3 "CRC according to SAE J1850 standard at each frame transmission.";
CM_ SG_ 1036 MessageCounter_ENGINE3 "This signal is a counter used for safety checks strategies. This counter is incremented of 1 (one) unit at each frame transmission.";
CM_ SG_ 518 CRC_ENGINE5 "CRC according to SAE J1850 standard at each frame transmission.";
CM_ SG_ 518 MessageCounter_ENGINE5 "This signal is a counter used for safety checks strategies. This counter is incremented of 1 (one) unit at each frame transmission.";
CM_ SG_ 518 PdlPosActual "Actual pedal position.";
CM_ SG_ 518 RPMOverRev_W "-";
CM_ SG_ 1448 ECM_THA_Resp "ECM speed limiting availability response for trailer hitch assist";
CM_ SG_ 1448 ECM_TRSC_Resp "Engine break activation response";
CM_ SG_ 264 CRC_EPS1 "CRC according to SAE J1850 standard at each frame transmission.";
CM_ SG_ 264 ElectricSteeringFailSts "It indicates if system EPS has an internal fault.";
CM_ SG_ 264 EngineFanRequestActivation "This signal is used to activate the cooling fun by the electric power steering.";
CM_ SG_ 264 EPS_ADAS_IMC_Fault "Status of the EPS Intra-Module Communciation channel as reported by the primary EPS unit";
CM_ SG_ 264 EPS_AsstStat "Electric Power Steering Assistance Status";
CM_ SG_ 264 EPS_Curr "Electric power steering current";
CM_ SG_ 264 EPS_Hands_On_Sts "EPS Hands on steering wheel status; Hands on steering wheel detected = [1]";
CM_ SG_ 264 EPS_HandsOnRecognition "EPS Hands On Recognition";
CM_ SG_ 264 EPSMotorTorque "It represents the torque on the EPS motor output shaft at all times";
CM_ SG_ 264 ESA_LAT_CTRL_ResponseSts "ESA Lateral Response Status";
CM_ SG_ 264 HAS_LAT_CTRL_ResponseSts "HAS LAT CTRL Response Sts";
CM_ SG_ 264 LKA_LAT_CTRL_ResponseSts "LKA LAT CTRL Response Sts";
CM_ SG_ 264 LwsAngle "This signal indicates the steering angle value, counterclockwise positive.";
CM_ SG_ 264 LwsAngleType "This signal indicates whether the angle sensor is absolute (all the possible turns/degrees) or not absolute (relative, torque only, etc.).";
CM_ SG_ 264 LwsCalibration "This signal indicates if the sensor has been calibrated and therefore the steering angle value is exported over Can.";
CM_ SG_ 264 LwsSpeed "This signal indicates the steering speed value, counterclockwise positive.";
CM_ SG_ 264 MessageCounter_EPS1 "This signal is a counter used for safety checks strategies. This counter is incremented of 1 (one) unit at each frame transmission.";
CM_ SG_ 264 SPM_Lat_Ctrl_ResponseSts "SPM Lat Ctrl Response Sts";
CM_ SG_ 264 Steering_Column_Torque "Steering Column Torque";
CM_ SG_ 264 Steering_OpStat_Prim "Capability of the Steering system to steer the vehicle as reported by primary actuator";
CM_ SG_ 264 SteeringVibration_Fault "EPS Steering Wheel vibration fault status";
CM_ SG_ 264 SteeringVibration_Status "EPS Steering Wheel vibration status";
CM_ SG_ 1056 EPS_MODE_STAT "EPS mode personalization status";
CM_ SG_ 1056 EPS_SteeringTouchStat "EPS Driver interference during the TRSC event; True = [1] , False= [0]";
CM_ SG_ 1056 EPS_SteeringTouq_Resp "EPS steering torque overlay activation response";
CM_ SG_ 1056 EPS_THA_DriverTorqueOverride "Determines if EPS driver torque on hand wheel is large enough to  override THA";
CM_ SG_ 1056 EPS_THA_SteeringTorqueResp "EPS steering torque overlay availability response for trailer hitch assist";
CM_ SG_ 1056 EPS_Warn_Disp_Rq "Electric Power Steering Warning Display Request";
CM_ SG_ 1056 THA_SteeringTouchStat "EPS hands on status for trailer hitch assist";
CM_ SG_ 276 DriveModeSts_EPT "Final eDrive mode status";
CM_ SG_ 1580 Motor1_RPM "Motor 1 speed";
CM_ SG_ 1580 Motor2_RPM "Motor 2 speed";
CM_ SG_ 1626 IMPACT_B "EARS Rear Event";
CM_ SG_ 1626 IMPACT_C "EARS Higher Severity Front Event";
CM_ SG_ 1626 IMPACT_F "EARS Lower Severity Front Event";
CM_ SG_ 1626 IMPACT_I "EARS RolloverEvent";
CM_ SG_ 1626 IMPACT_K "EARS Driver/Left Side Event";
CM_ SG_ 1626 IMPACT_M "EARS Passenger/Right Side Event";
CM_ SG_ 1626 IMPACTCommand "This signal is used to indicate that a crash happened";
CM_ SG_ 1626 IMPACTConfirm "This signal is used to confirm that a crash happened";
CM_ SG_ 1626 IMPACTFailSts "This signal is used to inform that an internal fault is present in the ORC";
CM_ SG_ 1626 IMPACTThreshold "Upon a crash, the ORC Calibration Threshold was either \"Met\" or \"Not_Met\".";
CM_ SG_ 2654486534 CBV_bit0_RepeatMessageRequestBit "Repeat Message Request Bit";
CM_ SG_ 2654486534 CBV_bit3_NMCoordinatorBit "NM Coordinator Sleep Bit";
CM_ SG_ 2654486534 CBV_bit4_ActiveWakeupBit "Active Wakeup Bit";
CM_ SG_ 2654486534 CBV_bit6_PartialNtwInfBit "Partial Network Information Bit (PNI)";
CM_ SG_ 2654486534 SourceNodeIdentifier "Source Node Identifier";
CM_ SG_ 2654486676 CBV_bit0_RepeatMessageRequestBit "Repeat Message Request Bit";
CM_ SG_ 2654486676 CBV_bit3_NMCoordinatorBit "NM Coordinator Sleep Bit";
CM_ SG_ 2654486676 CBV_bit4_ActiveWakeupBit "Active Wakeup Bit";
CM_ SG_ 2654486676 CBV_bit6_PartialNtwInfBit "Partial Network Information Bit (PNI)";
CM_ SG_ 2654486676 SourceNodeIdentifier "Source Node Identifier";
CM_ SG_ 2654486669 CBV_bit0_RepeatMessageRequestBit "Repeat Message Request Bit";
CM_ SG_ 2654486669 CBV_bit3_NMCoordinatorBit "NM Coordinator Sleep Bit";
CM_ SG_ 2654486669 CBV_bit4_ActiveWakeupBit "Active Wakeup Bit";
CM_ SG_ 2654486669 CBV_bit6_PartialNtwInfBit "Partial Network Information Bit (PNI)";
CM_ SG_ 2654486669 SourceNodeIdentifier "Source Node Identifier";
CM_ SG_ 2654486529 CBV_bit0_RepeatMessageRequestBit "Repeat Message Request Bit";
CM_ SG_ 2654486529 CBV_bit3_NMCoordinatorBit "NM Coordinator Sleep Bit";
CM_ SG_ 2654486529 CBV_bit4_ActiveWakeupBit "Active Wakeup Bit";
CM_ SG_ 2654486529 CBV_bit6_PartialNtwInfBit "Partial Network Information Bit (PNI)";
CM_ SG_ 2654486529 SourceNodeIdentifier "Source Node Identifier";
CM_ SG_ 2654486530 CBV_bit0_RepeatMessageRequestBit "Repeat Message Request Bit";
CM_ SG_ 2654486530 CBV_bit3_NMCoordinatorBit "NM Coordinator Sleep Bit";
CM_ SG_ 2654486530 CBV_bit4_ActiveWakeupBit "Active Wakeup Bit";
CM_ SG_ 2654486530 CBV_bit6_PartialNtwInfBit "Partial Network Information Bit (PNI)";
CM_ SG_ 2654486530 SourceNodeIdentifier "Source Node Identifier";
CM_ SG_ 2654486554 CBV_bit0_RepeatMessageRequestBit "Repeat Message Request Bit";
CM_ SG_ 2654486554 CBV_bit3_NMCoordinatorBit "NM Coordinator Sleep Bit";
CM_ SG_ 2654486554 CBV_bit4_ActiveWakeupBit "Active Wakeup Bit";
CM_ SG_ 2654486554 CBV_bit6_PartialNtwInfBit "Partial Network Information Bit (PNI)";
CM_ SG_ 2654486554 SourceNodeIdentifier "Source Node Identifier";
CM_ SG_ 2654486552 CBV_bit0_RepeatMessageRequestBit "Repeat Message Request Bit";
CM_ SG_ 2654486552 CBV_bit3_NMCoordinatorBit "NM Coordinator Sleep Bit";
CM_ SG_ 2654486552 CBV_bit4_ActiveWakeupBit "Active Wakeup Bit";
CM_ SG_ 2654486552 CBV_bit6_PartialNtwInfBit "Partial Network Information Bit (PNI)";
CM_ SG_ 2654486552 SourceNodeIdentifier "Source Node Identifier";
CM_ SG_ 611 CRC_ORC1 "CRC according to SAE J1850 standard at each frame transmission.";
CM_ SG_ 611 MessageCounter_ORC1 "This signal is a counter used for safety checks strategies. This counter is incremented of 1 (one) unit at each frame transmission.";
CM_ SG_ 611 SBR1RowDriverSeatSts "First row driver seatbelt switch status";
CM_ SG_ 1954 CRC_ORC2 "CRC according to SAE J1850 standard at each frame transmission.";
CM_ SG_ 1954 MessageCounter_ORC2 "This signal is a counter used for safety checks strategies. This counter is incremented of 1 (one) unit at each frame transmission.";
CM_ SG_ 1954 ORCIdentification "ORC identification number.";
CM_ SG_ 274 CRC_ORC3 "CRC according to SAE J1850 standard at each frame transmission.";
CM_ SG_ 274 InternalError "This signal indicates if an internal error has been processed";
CM_ SG_ 274 LatAcceleration "This signal indicates the Lateral Acceleration Value";
CM_ SG_ 274 LatAccelerationFailSts "This signal indicates the status of Lateral Acceleration Signal";
CM_ SG_ 274 LongAcceleration "This signal indicates the Longitudinal Acceleration Value";
CM_ SG_ 274 LongAccelerationFailSts "This signal indicates the status of Longitudinal acceleration signal";
CM_ SG_ 274 MessageCounter_ORC3 "This signal is a counter used for safety checks strategies. This counter is incremented of 1 (one) unit at each frame transmission.";
CM_ SG_ 274 YawRate "This signal indicates the Yaw Rate Value";
CM_ SG_ 274 YawRate_HR "Yaw Rate Additional signal for high resolution.";
CM_ SG_ 274 YawRate_HR_Sign "Sign of High resolution Yaw Rate signal. 0 = Negative [-]. 1 = Positive [+].";
CM_ SG_ 274 YawRateFailSts "This signal indicates the Status of Yaw Rate Signal";
CM_ SG_ 263 CRC_PT_SYSTEM_FD_1 "CRC according to SAE J1850 standard at each frame transmission.";
CM_ SG_ 263 DriveReady_PT "Drive Ready allowed status";
CM_ SG_ 263 EVCU2_THA_Resp "EVCU2 speed limiting availability response for trailer hitch assist";
CM_ SG_ 263 GasPedalPosition_PT "Gas Pedal Position in percentage";
CM_ SG_ 263 GasPedalPositionFailSts_PT "Gas Pedal Position Failure Status";
CM_ SG_ 263 GearEngaged_PT "Current engaged gear";
CM_ SG_ 263 GearEngagedForDisplay_PT "Transmission Gear Engaged signal for the instrument cluster display";
CM_ SG_ 263 MessageCounter_PT_SYSTEM_FD_1 "This signal is a counter used for safety checks strategies. This counter is incremented of 1 (one) unit at each frame transmission.";
CM_ SG_ 263 PdlPosActual_PT "Actual Pedal Position";
CM_ SG_ 263 PowertrainPrplsnActv_PT "Powertrain Propulsion System Status";
CM_ SG_ 263 ShiftLeverPosition_PT "Shift Lever Position";
CM_ SG_ 263 TargetGear_PT "Intended Gear that the transmission will shift to.";
CM_ SG_ 255 ACC_NCC_TrqEnblRq_Allowed "ACC/NCC Torque request allowed. True =[1]";
CM_ SG_ 255 Accel_Pedal_Override "Driver Accelerator Pedal Override. True =[1]";
CM_ SG_ 255 CRC_PT_TORQUE_FD_1 "CRC according to SAE J1850 standard at each frame transmission.";
CM_ SG_ 255 ESC_TrqEnblRq_Allowed "ESC Torque request allowed. True =[1]";
CM_ SG_ 255 Front_AxleTorque_Static "Static Front Axle Torqu";
CM_ SG_ 255 MessageCounter_PT_TORQUE_FD_1 "This signal is a counter used for safety checks strategies. This counter is incremented of 1 (one) unit at each frame transmission.";
CM_ SG_ 255 PPPA_TrqEnblRq_Allowed "PPPA Torque request allowed. True =[1]";
CM_ SG_ 255 Rear_AxleTorque_Static "Static Rear Axle Torque";
CM_ SG_ 255 RRCC_TrqEnblRq_Allowed "RRCC Torque request allowed. True =[1]";
CM_ SG_ 255 SSC_TrqEnblRq_Allowed "SCC Torque request allowed. True =[1]";
CM_ SG_ 255 SumTorque_DrvReqMod "Driver requested sum torque modified";
CM_ SG_ 255 SumTorqueExp "Expected sum torque based on target transmission input speed";
CM_ SG_ 255 SumTorqueMax "Maximum sum torque";
CM_ SG_ 255 SumTorqueMin "Minimum sum torque";
CM_ SG_ 255 SumTorqueSel_D_TTC "Corrected (substitute) driver torque demand";
CM_ SG_ 255 SumTorqueStatic "Static sum torque (effective sum torque)";
CM_ SG_ 255 Total_AxleTorque_Static "Static Axle Torque (effective total Axle torque)";
CM_ SG_ 1472 CRC_TRSCM1 "CRC according to SAE J1850 standard at each frame transmission.";
CM_ SG_ 1472 MessageCounter_TRSCM1 "This signal is a counter used for safety checks strategies. This counter is incremented of 1 (one) unit at each frame transmission.";
CM_ SG_ 1472 THA_EPB_Req "THA EPB securement request";
CM_ SG_ 1472 THA_Speed_Limit "THA Speed Limiter Threshold";
CM_ SG_ 1472 THA_SpeedLimit_Req "THA requested speed limit";
CM_ SG_ 1472 THA_STAT "Current trailer hitch assist maneuver state";
CM_ SG_ 1472 THA_SteeringDamping "THA Steering Damping";
CM_ SG_ 1472 THA_SteeringTorqueInfo "THA Steering Torque";
CM_ SG_ 1472 THA_SteeringTorqueReq "Trailer Hitch Assist steering torque request";
CM_ SG_ 1472 TRSC_SpeedLimit_Req "TRSC ECM Speed limit request";
CM_ SG_ 1472 TRSC_STAT "Trailer Reverse steering status signal";
CM_ SG_ 1472 TRSC_SteeringDamping "TRSC Steering damping percentage";
CM_ SG_ 1472 TRSC_SteeringTorqueInfo "TRSC Steering Torque";
CM_ SG_ 1472 TRSC_SteeringTorqueReq "TRSC steering torque overlay activation request";
CM_ SG_ 1472 TRSC_VehicleStop_Req "TRSC break activation request";

BA_DEF_ SG_ "GenSigStartValue" INT 0 2147483647;
BA_DEF_ SG_ "GenSigInactiveValue" INT 0 2147483647;
BA_DEF_ SG_ "GenSigSendType" ENUM "NotUsed","OnWrite","OnWriteWithRepetition","OnChange","OnChangeWithRepetition","IfActive","IfActiveWithRepetition","NoSigSendType";
BA_DEF_ SG_ "GenSigTimeoutTime_BSM" INT 0 65535;
BA_DEF_ SG_ "GenSigTimeoutTime_BSM2" INT 0 65535;
BA_DEF_ SG_ "GenSigTimeoutTime_CADM" INT 0 65535;
BA_DEF_ SG_ "GenSigTimeoutTime_CVADAS" INT 0 65535;
BA_DEF_ SG_ "GenSigTimeoutTime_ECM" INT 0 65535;
BA_DEF_ SG_ "GenSigTimeoutTime_EPS" INT 0 65535;
BA_DEF_ SG_ "GenSigTimeoutTime_EVCU2" INT 0 65535;
BA_DEF_ SG_ "GenSigTimeoutTime_ORC" INT 0 65535;
BA_DEF_ BO_ "DiagRequest" ENUM "No","Yes";
BA_DEF_ BO_ "Type" ENUM "P","C","PE","COC","PE_Cntrl","E","E_Cntrl","OC","S","BAF","DC","EM","MM","ISO-TP","-";
BA_DEF_ BO_ "DiagResponse" ENUM "No","Yes";
BA_DEF_ BO_ "NmMessage" ENUM "No","Yes";
BA_DEF_ BO_ "GenMsgSendType" ENUM "Cyclic","NotUsed","NotUsed","NotUsed","NotUsed","NotUsed","NotUsed","NotUsed","NoMsgSendType";
BA_DEF_ BO_ "GenMsgNrOfRepetition" INT 0 255;
BA_DEF_ BO_ "GenMsgILSupport" ENUM "No","Yes";
BA_DEF_ BO_ "GenMsgStartDelayTime" INT 0 65535;
BA_DEF_ BO_ "GenMsgCycleTimeFast" INT 0 65535;
BA_DEF_ BO_ "GenMsgCycleTime" INT 0 65535;
BA_DEF_ BO_ "GenMsgDelayTime" INT 0 65535;
BA_DEF_ BO_ "NmAsrMessage" ENUM "No","Yes";
BA_DEF_ BO_ "DiagState" ENUM "No","Yes";
BA_DEF_ BO_ "DiagConnection" HEX 0 65535;
BA_DEF_ BO_ "VFrameFormat" ENUM "StandardCAN","ExtendedCAN","reserved","reserved","reserved","reserved","reserved","reserved","reserved","reserved","reserved","reserved","reserved","reserved","StandardCAN_FD","ExtendedCAN_FD";
BA_DEF_ BO_ "CANFD_BRS" INT 0 1;
BA_DEF_DEF_ "DiagRequest" "No";
BA_DEF_DEF_ "Type" "-";
BA_DEF_DEF_ "DiagResponse" "No";
BA_DEF_DEF_ "NmMessage" "No";
BA_DEF_DEF_ "GenMsgSendType" "NoMsgSendType";
BA_DEF_DEF_ "GenMsgNrOfRepetition" 0;
BA_DEF_DEF_ "GenMsgILSupport" "No";
BA_DEF_DEF_ "GenMsgStartDelayTime" 0;
BA_DEF_DEF_ "GenMsgCycleTimeFast" 0;
BA_DEF_DEF_ "GenMsgCycleTime" 0;
BA_DEF_DEF_ "GenMsgDelayTime" 0;
BA_DEF_DEF_ "NmAsrMessage" "No";
BA_DEF_DEF_ "DiagState" "No";
BA_DEF_DEF_ "DiagConnection" 0;
BA_DEF_DEF_ "VFrameFormat" "StandardCAN_FD";
BA_DEF_DEF_ "CANFD_BRS" 0;
BA_DEF_DEF_ "GenSigStartValue" 0;
BA_DEF_DEF_ "GenSigInactiveValue" 0;
BA_DEF_DEF_ "GenSigSendType" "NoSigSendType";
BA_DEF_DEF_ "GenSigTimeoutTime_BSM" 2500;
BA_DEF_DEF_ "GenSigTimeoutTime_BSM2" 2500;
BA_DEF_DEF_ "GenSigTimeoutTime_CADM" 2500;
BA_DEF_DEF_ "GenSigTimeoutTime_CVADAS" 2500;
BA_DEF_DEF_ "GenSigTimeoutTime_ECM" 2500;
BA_DEF_DEF_ "GenSigTimeoutTime_EPS" 2500;
BA_DEF_DEF_ "GenSigTimeoutTime_EVCU2" 2500;
BA_DEF_DEF_ "GenSigTimeoutTime_ORC" 2500;
BA_ "Type" BO_ 205 1;
BA_ "GenMsgSendType" BO_ 205 0;
BA_ "GenMsgILSupport" BO_ 205 1;
BA_ "GenMsgCycleTime" BO_ 205 10;
BA_ "CANFD_BRS" BO_ 205 1;
BA_ "Type" BO_ 514 1;
BA_ "GenMsgSendType" BO_ 514 0;
BA_ "GenMsgILSupport" BO_ 514 1;
BA_ "GenMsgCycleTime" BO_ 514 20;
BA_ "CANFD_BRS" BO_ 514 1;
BA_ "Type" BO_ 257 1;
BA_ "GenMsgSendType" BO_ 257 0;
BA_ "GenMsgILSupport" BO_ 257 1;
BA_ "GenMsgCycleTime" BO_ 257 10;
BA_ "CANFD_BRS" BO_ 257 1;
BA_ "Type" BO_ 524 1;
BA_ "GenMsgSendType" BO_ 524 0;
BA_ "GenMsgILSupport" BO_ 524 1;
BA_ "GenMsgCycleTime" BO_ 524 20;
BA_ "CANFD_BRS" BO_ 524 1;
BA_ "Type" BO_ 1156 3;
BA_ "GenMsgSendType" BO_ 1156 0;
BA_ "GenMsgNrOfRepetition" BO_ 1156 2;
BA_ "GenMsgILSupport" BO_ 1156 1;
BA_ "GenMsgCycleTimeFast" BO_ 1156 20;
BA_ "GenMsgCycleTime" BO_ 1156 500;
BA_ "GenMsgDelayTime" BO_ 1156 20;
BA_ "CANFD_BRS" BO_ 1156 1;
BA_ "Type" BO_ 275 1;
BA_ "GenMsgSendType" BO_ 275 0;
BA_ "GenMsgILSupport" BO_ 275 1;
BA_ "GenMsgCycleTime" BO_ 275 10;
BA_ "CANFD_BRS" BO_ 275 1;
BA_ "Type" BO_ 726 1;
BA_ "GenMsgSendType" BO_ 726 0;
BA_ "GenMsgILSupport" BO_ 726 1;
BA_ "GenMsgCycleTime" BO_ 726 40;
BA_ "CANFD_BRS" BO_ 726 1;
BA_ "Type" BO_ 727 1;
BA_ "GenMsgSendType" BO_ 727 0;
BA_ "GenMsgILSupport" BO_ 727 1;
BA_ "GenMsgCycleTime" BO_ 727 40;
BA_ "CANFD_BRS" BO_ 727 1;
BA_ "Type" BO_ 950 3;
BA_ "GenMsgSendType" BO_ 950 0;
BA_ "GenMsgILSupport" BO_ 950 1;
BA_ "GenMsgCycleTime" BO_ 950 250;
BA_ "CANFD_BRS" BO_ 950 1;
BA_ "Type" BO_ 1054 1;
BA_ "GenMsgSendType" BO_ 1054 0;
BA_ "GenMsgILSupport" BO_ 1054 1;
BA_ "GenMsgCycleTime" BO_ 1054 100;
BA_ "CANFD_BRS" BO_ 1054 1;
BA_ "Type" BO_ 262 1;
BA_ "GenMsgSendType" BO_ 262 0;
BA_ "GenMsgILSupport" BO_ 262 1;
BA_ "GenMsgCycleTime" BO_ 262 10;
BA_ "CANFD_BRS" BO_ 262 1;
BA_ "Type" BO_ 1036 3;
BA_ "GenMsgSendType" BO_ 1036 0;
BA_ "GenMsgNrOfRepetition" BO_ 1036 2;
BA_ "GenMsgILSupport" BO_ 1036 1;
BA_ "GenMsgCycleTimeFast" BO_ 1036 20;
BA_ "GenMsgCycleTime" BO_ 1036 100;
BA_ "GenMsgDelayTime" BO_ 1036 20;
BA_ "CANFD_BRS" BO_ 1036 1;
BA_ "Type" BO_ 518 1;
BA_ "GenMsgSendType" BO_ 518 0;
BA_ "GenMsgILSupport" BO_ 518 1;
BA_ "GenMsgCycleTime" BO_ 518 20;
BA_ "CANFD_BRS" BO_ 518 1;
BA_ "Type" BO_ 1448 3;
BA_ "GenMsgSendType" BO_ 1448 0;
BA_ "GenMsgNrOfRepetition" BO_ 1448 2;
BA_ "GenMsgILSupport" BO_ 1448 1;
BA_ "GenMsgCycleTimeFast" BO_ 1448 20;
BA_ "GenMsgCycleTime" BO_ 1448 1000;
BA_ "GenMsgDelayTime" BO_ 1448 20;
BA_ "CANFD_BRS" BO_ 1448 1;
BA_ "Type" BO_ 264 1;
BA_ "GenMsgSendType" BO_ 264 0;
BA_ "GenMsgILSupport" BO_ 264 1;
BA_ "GenMsgCycleTime" BO_ 264 10;
BA_ "CANFD_BRS" BO_ 264 1;
BA_ "Type" BO_ 1056 1;
BA_ "GenMsgSendType" BO_ 1056 0;
BA_ "GenMsgILSupport" BO_ 1056 1;
BA_ "GenMsgCycleTime" BO_ 1056 100;
BA_ "CANFD_BRS" BO_ 1056 1;
BA_ "Type" BO_ 276 1;
BA_ "GenMsgSendType" BO_ 276 0;
BA_ "GenMsgILSupport" BO_ 276 1;
BA_ "GenMsgCycleTime" BO_ 276 10;
BA_ "CANFD_BRS" BO_ 276 1;
BA_ "Type" BO_ 1580 1;
BA_ "GenMsgSendType" BO_ 1580 0;
BA_ "GenMsgILSupport" BO_ 1580 1;
BA_ "GenMsgCycleTime" BO_ 1580 500;
BA_ "CANFD_BRS" BO_ 1580 1;
BA_ "Type" BO_ 1626 10;
BA_ "GenMsgSendType" BO_ 1626 0;
BA_ "GenMsgILSupport" BO_ 1626 1;
BA_ "GenMsgCycleTimeFast" BO_ 1626 10;
BA_ "GenMsgCycleTime" BO_ 1626 500;
BA_ "CANFD_BRS" BO_ 1626 1;
BA_ "Type" BO_ 2654486534 8;
BA_ "NmMessage" BO_ 2654486534 1;
BA_ "NmAsrMessage" BO_ 2654486534 1;
BA_ "VFrameFormat" BO_ 2654486534 15;
BA_ "CANFD_BRS" BO_ 2654486534 1;
BA_ "Type" BO_ 2654486676 8;
BA_ "NmMessage" BO_ 2654486676 1;
BA_ "NmAsrMessage" BO_ 2654486676 1;
BA_ "VFrameFormat" BO_ 2654486676 15;
BA_ "CANFD_BRS" BO_ 2654486676 1;
BA_ "Type" BO_ 2654486669 8;
BA_ "NmMessage" BO_ 2654486669 1;
BA_ "NmAsrMessage" BO_ 2654486669 1;
BA_ "VFrameFormat" BO_ 2654486669 15;
BA_ "CANFD_BRS" BO_ 2654486669 1;
BA_ "Type" BO_ 2654486529 8;
BA_ "NmMessage" BO_ 2654486529 1;
BA_ "NmAsrMessage" BO_ 2654486529 1;
BA_ "VFrameFormat" BO_ 2654486529 15;
BA_ "CANFD_BRS" BO_ 2654486529 1;
BA_ "Type" BO_ 2654486530 8;
BA_ "NmMessage" BO_ 2654486530 1;
BA_ "NmAsrMessage" BO_ 2654486530 1;
BA_ "VFrameFormat" BO_ 2654486530 15;
BA_ "CANFD_BRS" BO_ 2654486530 1;
BA_ "Type" BO_ 2654486592 8;
BA_ "NmMessage" BO_ 2654486592 1;
BA_ "NmAsrMessage" BO_ 2654486592 1;
BA_ "VFrameFormat" BO_ 2654486592 15;
BA_ "CANFD_BRS" BO_ 2654486592 1;
BA_ "Type" BO_ 2654486554 8;
BA_ "NmMessage" BO_ 2654486554 1;
BA_ "NmAsrMessage" BO_ 2654486554 1;
BA_ "VFrameFormat" BO_ 2654486554 15;
BA_ "CANFD_BRS" BO_ 2654486554 1;
BA_ "Type" BO_ 2654486552 8;
BA_ "NmMessage" BO_ 2654486552 1;
BA_ "NmAsrMessage" BO_ 2654486552 1;
BA_ "VFrameFormat" BO_ 2654486552 15;
BA_ "CANFD_BRS" BO_ 2654486552 1;
BA_ "Type" BO_ 611 3;
BA_ "GenMsgSendType" BO_ 611 0;
BA_ "GenMsgILSupport" BO_ 611 1;
BA_ "GenMsgCycleTime" BO_ 611 100;
BA_ "GenMsgDelayTime" BO_ 611 20;
BA_ "CANFD_BRS" BO_ 611 1;
BA_ "Type" BO_ 1954 3;
BA_ "GenMsgSendType" BO_ 1954 0;
BA_ "GenMsgILSupport" BO_ 1954 1;
BA_ "GenMsgCycleTime" BO_ 1954 1000;
BA_ "CANFD_BRS" BO_ 1954 1;
BA_ "Type" BO_ 274 1;
BA_ "GenMsgSendType" BO_ 274 0;
BA_ "GenMsgILSupport" BO_ 274 1;
BA_ "GenMsgCycleTime" BO_ 274 10;
BA_ "CANFD_BRS" BO_ 274 1;
BA_ "Type" BO_ 263 1;
BA_ "GenMsgSendType" BO_ 263 0;
BA_ "GenMsgILSupport" BO_ 263 1;
BA_ "GenMsgCycleTime" BO_ 263 10;
BA_ "CANFD_BRS" BO_ 263 1;
BA_ "Type" BO_ 255 1;
BA_ "GenMsgSendType" BO_ 255 0;
BA_ "GenMsgILSupport" BO_ 255 1;
BA_ "GenMsgCycleTime" BO_ 255 10;
BA_ "CANFD_BRS" BO_ 255 1;
BA_ "Type" BO_ 1472 3;
BA_ "GenMsgSendType" BO_ 1472 0;
BA_ "GenMsgILSupport" BO_ 1472 1;
BA_ "GenMsgCycleTime" BO_ 1472 1000;
BA_ "GenMsgDelayTime" BO_ 1472 20;
BA_ "CANFD_BRS" BO_ 1472 1;
BA_ "GenSigTimeoutTime_BSM" SG_ 205 Cmnd_TotBrkFrict_AxleTorq 0;
BA_ "GenSigTimeoutTime_BSM2" SG_ 205 Cmnd_TotBrkFrict_AxleTorq 0;
BA_ "GenSigTimeoutTime_CADM" SG_ 205 Cmnd_TotBrkFrict_AxleTorq 0;
BA_ "GenSigTimeoutTime_CVADAS" SG_ 205 Cmnd_TotBrkFrict_AxleTorq 0;
BA_ "GenSigTimeoutTime_ECM" SG_ 205 Cmnd_TotBrkFrict_AxleTorq 0;
BA_ "GenSigTimeoutTime_EPS" SG_ 205 Cmnd_TotBrkFrict_AxleTorq 0;
BA_ "GenSigTimeoutTime_ORC" SG_ 205 Cmnd_TotBrkFrict_AxleTorq 0;
BA_ "GenSigTimeoutTime_BSM" SG_ 205 CRC_BRAKE_FD_6 0;
BA_ "GenSigTimeoutTime_BSM2" SG_ 205 CRC_BRAKE_FD_6 0;
BA_ "GenSigTimeoutTime_CADM" SG_ 205 CRC_BRAKE_FD_6 0;
BA_ "GenSigTimeoutTime_CVADAS" SG_ 205 CRC_BRAKE_FD_6 0;
BA_ "GenSigTimeoutTime_EPS" SG_ 205 CRC_BRAKE_FD_6 0;
BA_ "GenSigTimeoutTime_ORC" SG_ 205 CRC_BRAKE_FD_6 0;
BA_ "GenSigTimeoutTime_BSM" SG_ 205 DriverReq_AxleTrq_Enabled_BSM 0;
BA_ "GenSigTimeoutTime_BSM2" SG_ 205 DriverReq_AxleTrq_Enabled_BSM 0;
BA_ "GenSigTimeoutTime_CADM" SG_ 205 DriverReq_AxleTrq_Enabled_BSM 0;
BA_ "GenSigTimeoutTime_EPS" SG_ 205 DriverReq_AxleTrq_Enabled_BSM 0;
BA_ "GenSigTimeoutTime_ORC" SG_ 205 DriverReq_AxleTrq_Enabled_BSM 0;
BA_ "GenSigStartValue" SG_ 205 DriverRequested_AxleTrq_BSM 32767;
BA_ "GenSigTimeoutTime_BSM" SG_ 205 DriverRequested_AxleTrq_BSM 0;
BA_ "GenSigTimeoutTime_BSM2" SG_ 205 DriverRequested_AxleTrq_BSM 0;
BA_ "GenSigTimeoutTime_CADM" SG_ 205 DriverRequested_AxleTrq_BSM 0;
BA_ "GenSigTimeoutTime_CVADAS" SG_ 205 DriverRequested_AxleTrq_BSM 0;
BA_ "GenSigTimeoutTime_EPS" SG_ 205 DriverRequested_AxleTrq_BSM 0;
BA_ "GenSigTimeoutTime_ORC" SG_ 205 DriverRequested_AxleTrq_BSM 0;
BA_ "GenSigTimeoutTime_BSM" SG_ 205 DrvrIntd_TotalBrk_AxleTorq 0;
BA_ "GenSigTimeoutTime_BSM2" SG_ 205 DrvrIntd_TotalBrk_AxleTorq 0;
BA_ "GenSigTimeoutTime_CADM" SG_ 205 DrvrIntd_TotalBrk_AxleTorq 0;
BA_ "GenSigTimeoutTime_CVADAS" SG_ 205 DrvrIntd_TotalBrk_AxleTorq 0;
BA_ "GenSigTimeoutTime_ECM" SG_ 205 DrvrIntd_TotalBrk_AxleTorq 0;
BA_ "GenSigTimeoutTime_EPS" SG_ 205 DrvrIntd_TotalBrk_AxleTorq 0;
BA_ "GenSigTimeoutTime_ORC" SG_ 205 DrvrIntd_TotalBrk_AxleTorq 0;
BA_ "GenSigTimeoutTime_BSM" SG_ 205 FrontAxle_Max_Rq_BSM 0;
BA_ "GenSigTimeoutTime_BSM2" SG_ 205 FrontAxle_Max_Rq_BSM 0;
BA_ "GenSigTimeoutTime_CADM" SG_ 205 FrontAxle_Max_Rq_BSM 0;
BA_ "GenSigTimeoutTime_CVADAS" SG_ 205 FrontAxle_Max_Rq_BSM 0;
BA_ "GenSigTimeoutTime_ECM" SG_ 205 FrontAxle_Max_Rq_BSM 0;
BA_ "GenSigTimeoutTime_EPS" SG_ 205 FrontAxle_Max_Rq_BSM 0;
BA_ "GenSigTimeoutTime_ORC" SG_ 205 FrontAxle_Max_Rq_BSM 0;
BA_ "GenSigTimeoutTime_BSM" SG_ 205 FrontAxle_Min_Rq_BSM 0;
BA_ "GenSigTimeoutTime_BSM2" SG_ 205 FrontAxle_Min_Rq_BSM 0;
BA_ "GenSigTimeoutTime_CADM" SG_ 205 FrontAxle_Min_Rq_BSM 0;
BA_ "GenSigTimeoutTime_CVADAS" SG_ 205 FrontAxle_Min_Rq_BSM 0;
BA_ "GenSigTimeoutTime_ECM" SG_ 205 FrontAxle_Min_Rq_BSM 0;
BA_ "GenSigTimeoutTime_EPS" SG_ 205 FrontAxle_Min_Rq_BSM 0;
BA_ "GenSigTimeoutTime_ORC" SG_ 205 FrontAxle_Min_Rq_BSM 0;
BA_ "GenSigStartValue" SG_ 205 FrontAxle_Rq_BSM 32767;
BA_ "GenSigTimeoutTime_BSM" SG_ 205 FrontAxle_Rq_BSM 0;
BA_ "GenSigTimeoutTime_BSM2" SG_ 205 FrontAxle_Rq_BSM 0;
BA_ "GenSigTimeoutTime_CADM" SG_ 205 FrontAxle_Rq_BSM 0;
BA_ "GenSigTimeoutTime_CVADAS" SG_ 205 FrontAxle_Rq_BSM 0;
BA_ "GenSigTimeoutTime_ECM" SG_ 205 FrontAxle_Rq_BSM 0;
BA_ "GenSigTimeoutTime_EPS" SG_ 205 FrontAxle_Rq_BSM 0;
BA_ "GenSigTimeoutTime_ORC" SG_ 205 FrontAxle_Rq_BSM 0;
BA_ "GenSigTimeoutTime_BSM" SG_ 205 MessageCounter_BRAKE_FD_6 0;
BA_ "GenSigTimeoutTime_BSM2" SG_ 205 MessageCounter_BRAKE_FD_6 0;
BA_ "GenSigTimeoutTime_CADM" SG_ 205 MessageCounter_BRAKE_FD_6 0;
BA_ "GenSigTimeoutTime_CVADAS" SG_ 205 MessageCounter_BRAKE_FD_6 0;
BA_ "GenSigTimeoutTime_EPS" SG_ 205 MessageCounter_BRAKE_FD_6 0;
BA_ "GenSigTimeoutTime_ORC" SG_ 205 MessageCounter_BRAKE_FD_6 0;
BA_ "GenSigTimeoutTime_BSM" SG_ 205 RearAxle_Max_Rq_BSM 0;
BA_ "GenSigTimeoutTime_BSM2" SG_ 205 RearAxle_Max_Rq_BSM 0;
BA_ "GenSigTimeoutTime_CADM" SG_ 205 RearAxle_Max_Rq_BSM 0;
BA_ "GenSigTimeoutTime_CVADAS" SG_ 205 RearAxle_Max_Rq_BSM 0;
BA_ "GenSigTimeoutTime_ECM" SG_ 205 RearAxle_Max_Rq_BSM 0;
BA_ "GenSigTimeoutTime_EPS" SG_ 205 RearAxle_Max_Rq_BSM 0;
BA_ "GenSigTimeoutTime_ORC" SG_ 205 RearAxle_Max_Rq_BSM 0;
BA_ "GenSigTimeoutTime_BSM" SG_ 205 RearAxle_Min_Rq_BSM 0;
BA_ "GenSigTimeoutTime_BSM2" SG_ 205 RearAxle_Min_Rq_BSM 0;
BA_ "GenSigTimeoutTime_CADM" SG_ 205 RearAxle_Min_Rq_BSM 0;
BA_ "GenSigTimeoutTime_CVADAS" SG_ 205 RearAxle_Min_Rq_BSM 0;
BA_ "GenSigTimeoutTime_ECM" SG_ 205 RearAxle_Min_Rq_BSM 0;
BA_ "GenSigTimeoutTime_EPS" SG_ 205 RearAxle_Min_Rq_BSM 0;
BA_ "GenSigTimeoutTime_ORC" SG_ 205 RearAxle_Min_Rq_BSM 0;
BA_ "GenSigStartValue" SG_ 205 RearAxle_Rq_BSM 32767;
BA_ "GenSigTimeoutTime_BSM" SG_ 205 RearAxle_Rq_BSM 0;
BA_ "GenSigTimeoutTime_BSM2" SG_ 205 RearAxle_Rq_BSM 0;
BA_ "GenSigTimeoutTime_CADM" SG_ 205 RearAxle_Rq_BSM 0;
BA_ "GenSigTimeoutTime_CVADAS" SG_ 205 RearAxle_Rq_BSM 0;
BA_ "GenSigTimeoutTime_ECM" SG_ 205 RearAxle_Rq_BSM 0;
BA_ "GenSigTimeoutTime_EPS" SG_ 205 RearAxle_Rq_BSM 0;
BA_ "GenSigTimeoutTime_ORC" SG_ 205 RearAxle_Rq_BSM 0;
BA_ "GenSigTimeoutTime_BSM" SG_ 205 TotalAxle_Max_Rq_BSM 0;
BA_ "GenSigTimeoutTime_BSM2" SG_ 205 TotalAxle_Max_Rq_BSM 0;
BA_ "GenSigTimeoutTime_CADM" SG_ 205 TotalAxle_Max_Rq_BSM 0;
BA_ "GenSigTimeoutTime_CVADAS" SG_ 205 TotalAxle_Max_Rq_BSM 0;
BA_ "GenSigTimeoutTime_EPS" SG_ 205 TotalAxle_Max_Rq_BSM 0;
BA_ "GenSigTimeoutTime_ORC" SG_ 205 TotalAxle_Max_Rq_BSM 0;
BA_ "GenSigTimeoutTime_BSM" SG_ 205 TotalAxle_Min_Rq_BSM 0;
BA_ "GenSigTimeoutTime_BSM2" SG_ 205 TotalAxle_Min_Rq_BSM 0;
BA_ "GenSigTimeoutTime_CADM" SG_ 205 TotalAxle_Min_Rq_BSM 0;
BA_ "GenSigTimeoutTime_CVADAS" SG_ 205 TotalAxle_Min_Rq_BSM 0;
BA_ "GenSigTimeoutTime_EPS" SG_ 205 TotalAxle_Min_Rq_BSM 0;
BA_ "GenSigTimeoutTime_ORC" SG_ 205 TotalAxle_Min_Rq_BSM 0;
BA_ "GenSigStartValue" SG_ 205 TotalAxle_Rq_BSM 32767;
BA_ "GenSigTimeoutTime_BSM" SG_ 205 TotalAxle_Rq_BSM 0;
BA_ "GenSigTimeoutTime_BSM2" SG_ 205 TotalAxle_Rq_BSM 0;
BA_ "GenSigTimeoutTime_CADM" SG_ 205 TotalAxle_Rq_BSM 0;
BA_ "GenSigTimeoutTime_CVADAS" SG_ 205 TotalAxle_Rq_BSM 0;
BA_ "GenSigTimeoutTime_EPS" SG_ 205 TotalAxle_Rq_BSM 0;
BA_ "GenSigTimeoutTime_ORC" SG_ 205 TotalAxle_Rq_BSM 0;
BA_ "GenSigTimeoutTime_BSM" SG_ 514 AEB_Type_Brk 0;
BA_ "GenSigTimeoutTime_CVADAS" SG_ 514 AEB_Type_Brk 0;
BA_ "GenSigTimeoutTime_ECM" SG_ 514 AEB_Type_Brk 0;
BA_ "GenSigTimeoutTime_EPS" SG_ 514 AEB_Type_Brk 0;
BA_ "GenSigTimeoutTime_EVCU2" SG_ 514 AEB_Type_Brk 0;
BA_ "GenSigTimeoutTime_BSM" SG_ 514 Brake_OpStat_Prim 0;
BA_ "GenSigTimeoutTime_BSM2" SG_ 514 Brake_OpStat_Prim 0;
BA_ "GenSigTimeoutTime_CVADAS" SG_ 514 Brake_OpStat_Prim 0;
BA_ "GenSigTimeoutTime_ECM" SG_ 514 Brake_OpStat_Prim 0;
BA_ "GenSigTimeoutTime_EPS" SG_ 514 Brake_OpStat_Prim 0;
BA_ "GenSigTimeoutTime_EVCU2" SG_ 514 Brake_OpStat_Prim 0;
BA_ "GenSigTimeoutTime_BSM" SG_ 514 BrakePdlPosn 0;
BA_ "GenSigTimeoutTime_CVADAS" SG_ 514 BrakePdlPosn 0;
BA_ "GenSigTimeoutTime_EPS" SG_ 514 BrakePdlPosn 0;
BA_ "GenSigTimeoutTime_ORC" SG_ 514 BrakePdlPosn 0;
BA_ "GenSigTimeoutTime_BSM" SG_ 514 BrkPdl_Flt 0;
BA_ "GenSigTimeoutTime_BSM2" SG_ 514 BrkPdl_Flt 0;
BA_ "GenSigTimeoutTime_CVADAS" SG_ 514 BrkPdl_Flt 0;
BA_ "GenSigTimeoutTime_EPS" SG_ 514 BrkPdl_Flt 0;
BA_ "GenSigTimeoutTime_ORC" SG_ 514 BrkPdl_Flt 0;
BA_ "GenSigStartValue" SG_ 514 BrkPdl_Stat 3;
BA_ "GenSigTimeoutTime_BSM" SG_ 514 BrkPdl_Stat 0;
BA_ "GenSigTimeoutTime_EPS" SG_ 514 BrkPdl_Stat 0;
BA_ "GenSigTimeoutTime_ORC" SG_ 514 BrkPdl_Stat 0;
BA_ "GenSigTimeoutTime_BSM" SG_ 514 BSM_HEALTH_CHECK 0;
BA_ "GenSigTimeoutTime_CADM" SG_ 514 BSM_HEALTH_CHECK 0;
BA_ "GenSigTimeoutTime_CVADAS" SG_ 514 BSM_HEALTH_CHECK 0;
BA_ "GenSigTimeoutTime_ECM" SG_ 514 BSM_HEALTH_CHECK 0;
BA_ "GenSigTimeoutTime_EPS" SG_ 514 BSM_HEALTH_CHECK 0;
BA_ "GenSigTimeoutTime_EVCU2" SG_ 514 BSM_HEALTH_CHECK 0;
BA_ "GenSigTimeoutTime_ORC" SG_ 514 BSM_HEALTH_CHECK 0;
BA_ "GenSigTimeoutTime_BSM" SG_ 514 BSM_OpStat 0;
BA_ "GenSigTimeoutTime_CVADAS" SG_ 514 BSM_OpStat 0;
BA_ "GenSigTimeoutTime_ECM" SG_ 514 BSM_OpStat 0;
BA_ "GenSigTimeoutTime_EPS" SG_ 514 BSM_OpStat 0;
BA_ "GenSigTimeoutTime_EVCU2" SG_ 514 BSM_OpStat 0;
BA_ "GenSigTimeoutTime_ORC" SG_ 514 BSM_OpStat 0;
BA_ "GenSigTimeoutTime_BSM" SG_ 514 CRC_BRAKE7 0;
BA_ "GenSigTimeoutTime_CVADAS" SG_ 514 CRC_BRAKE7 0;
BA_ "GenSigTimeoutTime_ECM" SG_ 514 CRC_BRAKE7 0;
BA_ "GenSigTimeoutTime_EPS" SG_ 514 CRC_BRAKE7 0;
BA_ "GenSigTimeoutTime_ORC" SG_ 514 CRC_BRAKE7 0;
BA_ "GenSigTimeoutTime_BSM" SG_ 514 MessageCounter_BRAKE7 0;
BA_ "GenSigTimeoutTime_CVADAS" SG_ 514 MessageCounter_BRAKE7 0;
BA_ "GenSigTimeoutTime_ECM" SG_ 514 MessageCounter_BRAKE7 0;
BA_ "GenSigTimeoutTime_EPS" SG_ 514 MessageCounter_BRAKE7 0;
BA_ "GenSigTimeoutTime_ORC" SG_ 514 MessageCounter_BRAKE7 0;
BA_ "GenSigTimeoutTime_BSM" SG_ 514 PAM_Brk_Rq_RspSts 0;
BA_ "GenSigTimeoutTime_BSM2" SG_ 514 PAM_Brk_Rq_RspSts 0;
BA_ "GenSigTimeoutTime_CADM" SG_ 514 PAM_Brk_Rq_RspSts 0;
BA_ "GenSigTimeoutTime_ECM" SG_ 514 PAM_Brk_Rq_RspSts 0;
BA_ "GenSigTimeoutTime_EPS" SG_ 514 PAM_Brk_Rq_RspSts 0;
BA_ "GenSigTimeoutTime_EVCU2" SG_ 514 PAM_Brk_Rq_RspSts 0;
BA_ "GenSigTimeoutTime_ORC" SG_ 514 PAM_Brk_Rq_RspSts 0;
BA_ "GenSigTimeoutTime_BSM" SG_ 257 ABSActive_B2 0;
BA_ "GenSigTimeoutTime_BSM2" SG_ 257 ABSActive_B2 0;
BA_ "GenSigTimeoutTime_CVADAS" SG_ 257 ABSActive_B2 0;
BA_ "GenSigTimeoutTime_ECM" SG_ 257 ABSActive_B2 0;
BA_ "GenSigTimeoutTime_EPS" SG_ 257 ABSActive_B2 0;
BA_ "GenSigTimeoutTime_EVCU2" SG_ 257 ABSActive_B2 0;
BA_ "GenSigTimeoutTime_ORC" SG_ 257 ABSActive_B2 0;
BA_ "GenSigTimeoutTime_BSM" SG_ 257 Brk_Stat_B2 0;
BA_ "GenSigTimeoutTime_BSM2" SG_ 257 Brk_Stat_B2 0;
BA_ "GenSigTimeoutTime_CVADAS" SG_ 257 Brk_Stat_B2 0;
BA_ "GenSigTimeoutTime_ECM" SG_ 257 Brk_Stat_B2 0;
BA_ "GenSigTimeoutTime_EPS" SG_ 257 Brk_Stat_B2 0;
BA_ "GenSigTimeoutTime_EVCU2" SG_ 257 Brk_Stat_B2 0;
BA_ "GenSigTimeoutTime_ORC" SG_ 257 Brk_Stat_B2 0;
BA_ "GenSigTimeoutTime_BSM" SG_ 257 CRC_BRAKE2_1 0;
BA_ "GenSigTimeoutTime_BSM2" SG_ 257 CRC_BRAKE2_1 0;
BA_ "GenSigTimeoutTime_ECM" SG_ 257 CRC_BRAKE2_1 0;
BA_ "GenSigTimeoutTime_EVCU2" SG_ 257 CRC_BRAKE2_1 0;
BA_ "GenSigStartValue" SG_ 257 Ft_RrAxleCoupling_TrqRq_B2 254;
BA_ "GenSigTimeoutTime_BSM" SG_ 257 Ft_RrAxleCoupling_TrqRq_B2 0;
BA_ "GenSigTimeoutTime_BSM2" SG_ 257 Ft_RrAxleCoupling_TrqRq_B2 0;
BA_ "GenSigTimeoutTime_CADM" SG_ 257 Ft_RrAxleCoupling_TrqRq_B2 0;
BA_ "GenSigTimeoutTime_CVADAS" SG_ 257 Ft_RrAxleCoupling_TrqRq_B2 0;
BA_ "GenSigTimeoutTime_ECM" SG_ 257 Ft_RrAxleCoupling_TrqRq_B2 0;
BA_ "GenSigTimeoutTime_EPS" SG_ 257 Ft_RrAxleCoupling_TrqRq_B2 0;
BA_ "GenSigTimeoutTime_EVCU2" SG_ 257 Ft_RrAxleCoupling_TrqRq_B2 0;
BA_ "GenSigTimeoutTime_ORC" SG_ 257 Ft_RrAxleCoupling_TrqRq_B2 0;
BA_ "GenSigTimeoutTime_BSM" SG_ 257 Ft_RrTrqCoupling_ModeRq_B2 0;
BA_ "GenSigTimeoutTime_BSM2" SG_ 257 Ft_RrTrqCoupling_ModeRq_B2 0;
BA_ "GenSigTimeoutTime_CADM" SG_ 257 Ft_RrTrqCoupling_ModeRq_B2 0;
BA_ "GenSigTimeoutTime_CVADAS" SG_ 257 Ft_RrTrqCoupling_ModeRq_B2 0;
BA_ "GenSigTimeoutTime_ECM" SG_ 257 Ft_RrTrqCoupling_ModeRq_B2 0;
BA_ "GenSigTimeoutTime_EPS" SG_ 257 Ft_RrTrqCoupling_ModeRq_B2 0;
BA_ "GenSigTimeoutTime_EVCU2" SG_ 257 Ft_RrTrqCoupling_ModeRq_B2 0;
BA_ "GenSigTimeoutTime_ORC" SG_ 257 Ft_RrTrqCoupling_ModeRq_B2 0;
BA_ "GenSigTimeoutTime_BSM" SG_ 257 Inlet_Pressure_Pos 0;
BA_ "GenSigTimeoutTime_BSM2" SG_ 257 Inlet_Pressure_Pos 0;
BA_ "GenSigTimeoutTime_CVADAS" SG_ 257 Inlet_Pressure_Pos 0;
BA_ "GenSigTimeoutTime_ECM" SG_ 257 Inlet_Pressure_Pos 0;
BA_ "GenSigTimeoutTime_EPS" SG_ 257 Inlet_Pressure_Pos 0;
BA_ "GenSigTimeoutTime_EVCU2" SG_ 257 Inlet_Pressure_Pos 0;
BA_ "GenSigTimeoutTime_ORC" SG_ 257 Inlet_Pressure_Pos 0;
BA_ "GenSigTimeoutTime_BSM" SG_ 257 LHF_FastPulseCounter_B2 0;
BA_ "GenSigTimeoutTime_BSM2" SG_ 257 LHF_FastPulseCounter_B2 0;
BA_ "GenSigTimeoutTime_CVADAS" SG_ 257 LHF_FastPulseCounter_B2 0;
BA_ "GenSigTimeoutTime_ECM" SG_ 257 LHF_FastPulseCounter_B2 0;
BA_ "GenSigTimeoutTime_EPS" SG_ 257 LHF_FastPulseCounter_B2 0;
BA_ "GenSigTimeoutTime_EVCU2" SG_ 257 LHF_FastPulseCounter_B2 0;
BA_ "GenSigTimeoutTime_ORC" SG_ 257 LHF_FastPulseCounter_B2 0;
BA_ "GenSigTimeoutTime_BSM" SG_ 257 LHF_Spin_B2 0;
BA_ "GenSigTimeoutTime_BSM2" SG_ 257 LHF_Spin_B2 0;
BA_ "GenSigTimeoutTime_CVADAS" SG_ 257 LHF_Spin_B2 0;
BA_ "GenSigTimeoutTime_ECM" SG_ 257 LHF_Spin_B2 0;
BA_ "GenSigTimeoutTime_EPS" SG_ 257 LHF_Spin_B2 0;
BA_ "GenSigTimeoutTime_EVCU2" SG_ 257 LHF_Spin_B2 0;
BA_ "GenSigTimeoutTime_ORC" SG_ 257 LHF_Spin_B2 0;
BA_ "GenSigTimeoutTime_BSM" SG_ 257 LHF_WheelSensorFailSts_B2 0;
BA_ "GenSigTimeoutTime_BSM2" SG_ 257 LHF_WheelSensorFailSts_B2 0;
BA_ "GenSigTimeoutTime_CVADAS" SG_ 257 LHF_WheelSensorFailSts_B2 0;
BA_ "GenSigTimeoutTime_ECM" SG_ 257 LHF_WheelSensorFailSts_B2 0;
BA_ "GenSigTimeoutTime_EPS" SG_ 257 LHF_WheelSensorFailSts_B2 0;
BA_ "GenSigTimeoutTime_EVCU2" SG_ 257 LHF_WheelSensorFailSts_B2 0;
BA_ "GenSigTimeoutTime_ORC" SG_ 257 LHF_WheelSensorFailSts_B2 0;
BA_ "GenSigTimeoutTime_BSM" SG_ 257 LHFWheelSpeed_B2 0;
BA_ "GenSigTimeoutTime_BSM2" SG_ 257 LHFWheelSpeed_B2 0;
BA_ "GenSigTimeoutTime_CVADAS" SG_ 257 LHFWheelSpeed_B2 0;
BA_ "GenSigTimeoutTime_ECM" SG_ 257 LHFWheelSpeed_B2 0;
BA_ "GenSigTimeoutTime_EPS" SG_ 257 LHFWheelSpeed_B2 0;
BA_ "GenSigTimeoutTime_EVCU2" SG_ 257 LHFWheelSpeed_B2 0;
BA_ "GenSigTimeoutTime_ORC" SG_ 257 LHFWheelSpeed_B2 0;
BA_ "GenSigTimeoutTime_BSM" SG_ 257 MessageCounter_BRAKE2_1 0;
BA_ "GenSigTimeoutTime_BSM2" SG_ 257 MessageCounter_BRAKE2_1 0;
BA_ "GenSigTimeoutTime_ECM" SG_ 257 MessageCounter_BRAKE2_1 0;
BA_ "GenSigTimeoutTime_EVCU2" SG_ 257 MessageCounter_BRAKE2_1 0;
BA_ "GenSigStartValue" SG_ 257 R_DIFF_TRQ_RQ_B2 511;
BA_ "GenSigTimeoutTime_BSM" SG_ 257 R_DIFF_TRQ_RQ_B2 0;
BA_ "GenSigTimeoutTime_BSM2" SG_ 257 R_DIFF_TRQ_RQ_B2 0;
BA_ "GenSigTimeoutTime_CADM" SG_ 257 R_DIFF_TRQ_RQ_B2 0;
BA_ "GenSigTimeoutTime_CVADAS" SG_ 257 R_DIFF_TRQ_RQ_B2 0;
BA_ "GenSigTimeoutTime_ECM" SG_ 257 R_DIFF_TRQ_RQ_B2 0;
BA_ "GenSigTimeoutTime_EPS" SG_ 257 R_DIFF_TRQ_RQ_B2 0;
BA_ "GenSigTimeoutTime_EVCU2" SG_ 257 R_DIFF_TRQ_RQ_B2 0;
BA_ "GenSigTimeoutTime_ORC" SG_ 257 R_DIFF_TRQ_RQ_B2 0;
BA_ "GenSigTimeoutTime_BSM" SG_ 257 Rear_Diff_BSM_RQ_B2 0;
BA_ "GenSigTimeoutTime_BSM2" SG_ 257 Rear_Diff_BSM_RQ_B2 0;
BA_ "GenSigTimeoutTime_CADM" SG_ 257 Rear_Diff_BSM_RQ_B2 0;
BA_ "GenSigTimeoutTime_CVADAS" SG_ 257 Rear_Diff_BSM_RQ_B2 0;
BA_ "GenSigTimeoutTime_ECM" SG_ 257 Rear_Diff_BSM_RQ_B2 0;
BA_ "GenSigTimeoutTime_EPS" SG_ 257 Rear_Diff_BSM_RQ_B2 0;
BA_ "GenSigTimeoutTime_EVCU2" SG_ 257 Rear_Diff_BSM_RQ_B2 0;
BA_ "GenSigTimeoutTime_ORC" SG_ 257 Rear_Diff_BSM_RQ_B2 0;
BA_ "GenSigTimeoutTime_BSM" SG_ 257 RHF_FastPulseCounter_B2 0;
BA_ "GenSigTimeoutTime_BSM2" SG_ 257 RHF_FastPulseCounter_B2 0;
BA_ "GenSigTimeoutTime_CVADAS" SG_ 257 RHF_FastPulseCounter_B2 0;
BA_ "GenSigTimeoutTime_ECM" SG_ 257 RHF_FastPulseCounter_B2 0;
BA_ "GenSigTimeoutTime_EPS" SG_ 257 RHF_FastPulseCounter_B2 0;
BA_ "GenSigTimeoutTime_EVCU2" SG_ 257 RHF_FastPulseCounter_B2 0;
BA_ "GenSigTimeoutTime_ORC" SG_ 257 RHF_FastPulseCounter_B2 0;
BA_ "GenSigTimeoutTime_BSM" SG_ 257 RHF_Spin_B2 0;
BA_ "GenSigTimeoutTime_BSM2" SG_ 257 RHF_Spin_B2 0;
BA_ "GenSigTimeoutTime_CVADAS" SG_ 257 RHF_Spin_B2 0;
BA_ "GenSigTimeoutTime_ECM" SG_ 257 RHF_Spin_B2 0;
BA_ "GenSigTimeoutTime_EPS" SG_ 257 RHF_Spin_B2 0;
BA_ "GenSigTimeoutTime_EVCU2" SG_ 257 RHF_Spin_B2 0;
BA_ "GenSigTimeoutTime_ORC" SG_ 257 RHF_Spin_B2 0;
BA_ "GenSigTimeoutTime_BSM" SG_ 257 RHF_WheelSensorFailSts_B2 0;
BA_ "GenSigTimeoutTime_BSM2" SG_ 257 RHF_WheelSensorFailSts_B2 0;
BA_ "GenSigTimeoutTime_CVADAS" SG_ 257 RHF_WheelSensorFailSts_B2 0;
BA_ "GenSigTimeoutTime_ECM" SG_ 257 RHF_WheelSensorFailSts_B2 0;
BA_ "GenSigTimeoutTime_EPS" SG_ 257 RHF_WheelSensorFailSts_B2 0;
BA_ "GenSigTimeoutTime_EVCU2" SG_ 257 RHF_WheelSensorFailSts_B2 0;
BA_ "GenSigTimeoutTime_ORC" SG_ 257 RHF_WheelSensorFailSts_B2 0;
BA_ "GenSigTimeoutTime_BSM" SG_ 257 RHFWheelSpeed_B2 0;
BA_ "GenSigTimeoutTime_BSM2" SG_ 257 RHFWheelSpeed_B2 0;
BA_ "GenSigTimeoutTime_CVADAS" SG_ 257 RHFWheelSpeed_B2 0;
BA_ "GenSigTimeoutTime_ECM" SG_ 257 RHFWheelSpeed_B2 0;
BA_ "GenSigTimeoutTime_EPS" SG_ 257 RHFWheelSpeed_B2 0;
BA_ "GenSigTimeoutTime_EVCU2" SG_ 257 RHFWheelSpeed_B2 0;
BA_ "GenSigTimeoutTime_ORC" SG_ 257 RHFWheelSpeed_B2 0;
BA_ "GenSigTimeoutTime_BSM" SG_ 257 VehicleSpeedVSOSig_B2 0;
BA_ "GenSigTimeoutTime_BSM2" SG_ 257 VehicleSpeedVSOSig_B2 0;
BA_ "GenSigTimeoutTime_ECM" SG_ 257 VehicleSpeedVSOSig_B2 0;
BA_ "GenSigTimeoutTime_EVCU2" SG_ 257 VehicleSpeedVSOSig_B2 0;
BA_ "GenSigTimeoutTime_ORC" SG_ 257 VehicleSpeedVSOSig_B2 0;
BA_ "GenSigTimeoutTime_BSM" SG_ 524 AEB_Type_Brk_B2 0;
BA_ "GenSigTimeoutTime_BSM2" SG_ 524 AEB_Type_Brk_B2 0;
BA_ "GenSigTimeoutTime_CVADAS" SG_ 524 AEB_Type_Brk_B2 0;
BA_ "GenSigTimeoutTime_ECM" SG_ 524 AEB_Type_Brk_B2 0;
BA_ "GenSigTimeoutTime_EPS" SG_ 524 AEB_Type_Brk_B2 0;
BA_ "GenSigTimeoutTime_EVCU2" SG_ 524 AEB_Type_Brk_B2 0;
BA_ "GenSigTimeoutTime_ORC" SG_ 524 AEB_Type_Brk_B2 0;
BA_ "GenSigTimeoutTime_BSM" SG_ 524 Brake_OpStat_Sec 0;
BA_ "GenSigTimeoutTime_BSM2" SG_ 524 Brake_OpStat_Sec 0;
BA_ "GenSigTimeoutTime_CVADAS" SG_ 524 Brake_OpStat_Sec 0;
BA_ "GenSigTimeoutTime_ECM" SG_ 524 Brake_OpStat_Sec 0;
BA_ "GenSigTimeoutTime_EPS" SG_ 524 Brake_OpStat_Sec 0;
BA_ "GenSigTimeoutTime_EVCU2" SG_ 524 Brake_OpStat_Sec 0;
BA_ "GenSigTimeoutTime_ORC" SG_ 524 Brake_OpStat_Sec 0;
BA_ "GenSigStartValue" SG_ 524 BrkTrq_B2 32767;
BA_ "GenSigTimeoutTime_BSM" SG_ 524 BrkTrq_B2 0;
BA_ "GenSigTimeoutTime_BSM2" SG_ 524 BrkTrq_B2 0;
BA_ "GenSigTimeoutTime_CVADAS" SG_ 524 BrkTrq_B2 0;
BA_ "GenSigTimeoutTime_ECM" SG_ 524 BrkTrq_B2 0;
BA_ "GenSigTimeoutTime_EPS" SG_ 524 BrkTrq_B2 0;
BA_ "GenSigTimeoutTime_EVCU2" SG_ 524 BrkTrq_B2 0;
BA_ "GenSigTimeoutTime_ORC" SG_ 524 BrkTrq_B2 0;
BA_ "GenSigTimeoutTime_BSM2" SG_ 524 BSM2_HEALTH_CHECK 0;
BA_ "GenSigTimeoutTime_CADM" SG_ 524 BSM2_HEALTH_CHECK 0;
BA_ "GenSigTimeoutTime_CVADAS" SG_ 524 BSM2_HEALTH_CHECK 0;
BA_ "GenSigTimeoutTime_ECM" SG_ 524 BSM2_HEALTH_CHECK 0;
BA_ "GenSigTimeoutTime_EPS" SG_ 524 BSM2_HEALTH_CHECK 0;
BA_ "GenSigTimeoutTime_EVCU2" SG_ 524 BSM2_HEALTH_CHECK 0;
BA_ "GenSigTimeoutTime_ORC" SG_ 524 BSM2_HEALTH_CHECK 0;
BA_ "GenSigTimeoutTime_BSM2" SG_ 524 BSM2_OpStat 0;
BA_ "GenSigTimeoutTime_CVADAS" SG_ 524 BSM2_OpStat 0;
BA_ "GenSigTimeoutTime_ECM" SG_ 524 BSM2_OpStat 0;
BA_ "GenSigTimeoutTime_EPS" SG_ 524 BSM2_OpStat 0;
BA_ "GenSigTimeoutTime_EVCU2" SG_ 524 BSM2_OpStat 0;
BA_ "GenSigTimeoutTime_ORC" SG_ 524 BSM2_OpStat 0;
BA_ "GenSigTimeoutTime_BSM2" SG_ 524 CRC_BRAKE2_2 0;
BA_ "GenSigTimeoutTime_CVADAS" SG_ 524 CRC_BRAKE2_2 0;
BA_ "GenSigTimeoutTime_ECM" SG_ 524 CRC_BRAKE2_2 0;
BA_ "GenSigTimeoutTime_EPS" SG_ 524 CRC_BRAKE2_2 0;
BA_ "GenSigTimeoutTime_EVCU2" SG_ 524 CRC_BRAKE2_2 0;
BA_ "GenSigTimeoutTime_BSM2" SG_ 524 MessageCounter_BRAKE2_2 0;
BA_ "GenSigTimeoutTime_CVADAS" SG_ 524 MessageCounter_BRAKE2_2 0;
BA_ "GenSigTimeoutTime_ECM" SG_ 524 MessageCounter_BRAKE2_2 0;
BA_ "GenSigTimeoutTime_EPS" SG_ 524 MessageCounter_BRAKE2_2 0;
BA_ "GenSigTimeoutTime_EVCU2" SG_ 524 MessageCounter_BRAKE2_2 0;
BA_ "GenSigStartValue" SG_ 524 VehicleStandStillSts_B2 1;
BA_ "GenSigTimeoutTime_BSM2" SG_ 524 VehicleStandStillSts_B2 0;
BA_ "GenSigTimeoutTime_CVADAS" SG_ 524 VehicleStandStillSts_B2 0;
BA_ "GenSigTimeoutTime_ECM" SG_ 524 VehicleStandStillSts_B2 0;
BA_ "GenSigTimeoutTime_EPS" SG_ 524 VehicleStandStillSts_B2 0;
BA_ "GenSigTimeoutTime_EVCU2" SG_ 524 VehicleStandStillSts_B2 0;
BA_ "GenSigTimeoutTime_ORC" SG_ 524 VehicleStandStillSts_B2 0;
BA_ "GenSigSendType" SG_ 1156 ABSFailSts_B2 4;
BA_ "GenSigTimeoutTime_BSM" SG_ 1156 ABSFailSts_B2 0;
BA_ "GenSigTimeoutTime_BSM2" SG_ 1156 ABSFailSts_B2 0;
BA_ "GenSigTimeoutTime_CVADAS" SG_ 1156 ABSFailSts_B2 0;
BA_ "GenSigTimeoutTime_ECM" SG_ 1156 ABSFailSts_B2 0;
BA_ "GenSigTimeoutTime_EPS" SG_ 1156 ABSFailSts_B2 0;
BA_ "GenSigTimeoutTime_EVCU2" SG_ 1156 ABSFailSts_B2 0;
BA_ "GenSigTimeoutTime_ORC" SG_ 1156 ABSFailSts_B2 0;
BA_ "GenSigTimeoutTime_BSM" SG_ 1156 CRC_BRAKE2_3 0;
BA_ "GenSigTimeoutTime_BSM2" SG_ 1156 CRC_BRAKE2_3 0;
BA_ "GenSigTimeoutTime_CVADAS" SG_ 1156 CRC_BRAKE2_3 0;
BA_ "GenSigTimeoutTime_ECM" SG_ 1156 CRC_BRAKE2_3 0;
BA_ "GenSigTimeoutTime_EPS" SG_ 1156 CRC_BRAKE2_3 0;
BA_ "GenSigTimeoutTime_EVCU2" SG_ 1156 CRC_BRAKE2_3 0;
BA_ "GenSigTimeoutTime_BSM" SG_ 1156 MessageCounter_BRAKE2_3 0;
BA_ "GenSigTimeoutTime_BSM2" SG_ 1156 MessageCounter_BRAKE2_3 0;
BA_ "GenSigTimeoutTime_CVADAS" SG_ 1156 MessageCounter_BRAKE2_3 0;
BA_ "GenSigTimeoutTime_ECM" SG_ 1156 MessageCounter_BRAKE2_3 0;
BA_ "GenSigTimeoutTime_EPS" SG_ 1156 MessageCounter_BRAKE2_3 0;
BA_ "GenSigTimeoutTime_EVCU2" SG_ 1156 MessageCounter_BRAKE2_3 0;
BA_ "GenSigSendType" SG_ 1156 RollsModeAct_B2 4;
BA_ "GenSigTimeoutTime_BSM" SG_ 1156 RollsModeAct_B2 0;
BA_ "GenSigTimeoutTime_BSM2" SG_ 1156 RollsModeAct_B2 0;
BA_ "GenSigTimeoutTime_CVADAS" SG_ 1156 RollsModeAct_B2 0;
BA_ "GenSigTimeoutTime_ECM" SG_ 1156 RollsModeAct_B2 0;
BA_ "GenSigTimeoutTime_EPS" SG_ 1156 RollsModeAct_B2 0;
BA_ "GenSigTimeoutTime_EVCU2" SG_ 1156 RollsModeAct_B2 0;
BA_ "GenSigTimeoutTime_ORC" SG_ 1156 RollsModeAct_B2 0;
BA_ "GenSigTimeoutTime_BSM2" SG_ 275 CRC_CVPAM_FD_Control 0;
BA_ "GenSigTimeoutTime_CADM" SG_ 275 CRC_CVPAM_FD_Control 0;
BA_ "GenSigTimeoutTime_CVADAS" SG_ 275 CRC_CVPAM_FD_Control 0;
BA_ "GenSigTimeoutTime_ECM" SG_ 275 CRC_CVPAM_FD_Control 0;
BA_ "GenSigTimeoutTime_EVCU2" SG_ 275 CRC_CVPAM_FD_Control 0;
BA_ "GenSigTimeoutTime_ORC" SG_ 275 CRC_CVPAM_FD_Control 0;
BA_ "GenSigTimeoutTime_BSM" SG_ 275 ManoeuvrePhase 0;
BA_ "GenSigTimeoutTime_BSM2" SG_ 275 ManoeuvrePhase 0;
BA_ "GenSigTimeoutTime_CADM" SG_ 275 ManoeuvrePhase 0;
BA_ "GenSigTimeoutTime_CVADAS" SG_ 275 ManoeuvrePhase 0;
BA_ "GenSigTimeoutTime_ECM" SG_ 275 ManoeuvrePhase 0;
BA_ "GenSigTimeoutTime_EVCU2" SG_ 275 ManoeuvrePhase 0;
BA_ "GenSigTimeoutTime_ORC" SG_ 275 ManoeuvrePhase 0;
BA_ "GenSigTimeoutTime_BSM2" SG_ 275 MessageCounter_CVPAM_FD_Control 0;
BA_ "GenSigTimeoutTime_CADM" SG_ 275 MessageCounter_CVPAM_FD_Control 0;
BA_ "GenSigTimeoutTime_CVADAS" SG_ 275 MessageCounter_CVPAM_FD_Control 0;
BA_ "GenSigTimeoutTime_ECM" SG_ 275 MessageCounter_CVPAM_FD_Control 0;
BA_ "GenSigTimeoutTime_EVCU2" SG_ 275 MessageCounter_CVPAM_FD_Control 0;
BA_ "GenSigTimeoutTime_ORC" SG_ 275 MessageCounter_CVPAM_FD_Control 0;
BA_ "GenSigTimeoutTime_BSM2" SG_ 275 ParkingGearShiftReq 0;
BA_ "GenSigTimeoutTime_CADM" SG_ 275 ParkingGearShiftReq 0;
BA_ "GenSigTimeoutTime_CVADAS" SG_ 275 ParkingGearShiftReq 0;
BA_ "GenSigTimeoutTime_ECM" SG_ 275 ParkingGearShiftReq 0;
BA_ "GenSigTimeoutTime_EPS" SG_ 275 ParkingGearShiftReq 0;
BA_ "GenSigTimeoutTime_EVCU2" SG_ 275 ParkingGearShiftReq 0;
BA_ "GenSigTimeoutTime_ORC" SG_ 275 ParkingGearShiftReq 0;
BA_ "GenSigTimeoutTime_BSM2" SG_ 275 PPPA_AccelMax 0;
BA_ "GenSigTimeoutTime_CADM" SG_ 275 PPPA_AccelMax 0;
BA_ "GenSigTimeoutTime_CVADAS" SG_ 275 PPPA_AccelMax 0;
BA_ "GenSigTimeoutTime_ECM" SG_ 275 PPPA_AccelMax 0;
BA_ "GenSigTimeoutTime_EPS" SG_ 275 PPPA_AccelMax 0;
BA_ "GenSigTimeoutTime_EVCU2" SG_ 275 PPPA_AccelMax 0;
BA_ "GenSigTimeoutTime_ORC" SG_ 275 PPPA_AccelMax 0;
BA_ "GenSigTimeoutTime_BSM2" SG_ 275 PPPA_AccelMin 0;
BA_ "GenSigTimeoutTime_CADM" SG_ 275 PPPA_AccelMin 0;
BA_ "GenSigTimeoutTime_CVADAS" SG_ 275 PPPA_AccelMin 0;
BA_ "GenSigTimeoutTime_ECM" SG_ 275 PPPA_AccelMin 0;
BA_ "GenSigTimeoutTime_EPS" SG_ 275 PPPA_AccelMin 0;
BA_ "GenSigTimeoutTime_EVCU2" SG_ 275 PPPA_AccelMin 0;
BA_ "GenSigTimeoutTime_ORC" SG_ 275 PPPA_AccelMin 0;
BA_ "GenSigTimeoutTime_BSM2" SG_ 275 PPPA_DecelMax 0;
BA_ "GenSigTimeoutTime_CADM" SG_ 275 PPPA_DecelMax 0;
BA_ "GenSigTimeoutTime_CVADAS" SG_ 275 PPPA_DecelMax 0;
BA_ "GenSigTimeoutTime_ECM" SG_ 275 PPPA_DecelMax 0;
BA_ "GenSigTimeoutTime_EPS" SG_ 275 PPPA_DecelMax 0;
BA_ "GenSigTimeoutTime_EVCU2" SG_ 275 PPPA_DecelMax 0;
BA_ "GenSigTimeoutTime_ORC" SG_ 275 PPPA_DecelMax 0;
BA_ "GenSigTimeoutTime_BSM2" SG_ 275 PPPA_DecelMin 0;
BA_ "GenSigTimeoutTime_CADM" SG_ 275 PPPA_DecelMin 0;
BA_ "GenSigTimeoutTime_CVADAS" SG_ 275 PPPA_DecelMin 0;
BA_ "GenSigTimeoutTime_ECM" SG_ 275 PPPA_DecelMin 0;
BA_ "GenSigTimeoutTime_EPS" SG_ 275 PPPA_DecelMin 0;
BA_ "GenSigTimeoutTime_EVCU2" SG_ 275 PPPA_DecelMin 0;
BA_ "GenSigTimeoutTime_ORC" SG_ 275 PPPA_DecelMin 0;
BA_ "GenSigTimeoutTime_BSM2" SG_ 275 PPPA_Interface_BSM 0;
BA_ "GenSigTimeoutTime_CADM" SG_ 275 PPPA_Interface_BSM 0;
BA_ "GenSigTimeoutTime_CVADAS" SG_ 275 PPPA_Interface_BSM 0;
BA_ "GenSigTimeoutTime_ECM" SG_ 275 PPPA_Interface_BSM 0;
BA_ "GenSigTimeoutTime_EPS" SG_ 275 PPPA_Interface_BSM 0;
BA_ "GenSigTimeoutTime_EVCU2" SG_ 275 PPPA_Interface_BSM 0;
BA_ "GenSigTimeoutTime_ORC" SG_ 275 PPPA_Interface_BSM 0;
BA_ "GenSigTimeoutTime_BSM2" SG_ 275 PPPA_JerkAccelMax 0;
BA_ "GenSigTimeoutTime_CADM" SG_ 275 PPPA_JerkAccelMax 0;
BA_ "GenSigTimeoutTime_CVADAS" SG_ 275 PPPA_JerkAccelMax 0;
BA_ "GenSigTimeoutTime_ECM" SG_ 275 PPPA_JerkAccelMax 0;
BA_ "GenSigTimeoutTime_EPS" SG_ 275 PPPA_JerkAccelMax 0;
BA_ "GenSigTimeoutTime_EVCU2" SG_ 275 PPPA_JerkAccelMax 0;
BA_ "GenSigTimeoutTime_ORC" SG_ 275 PPPA_JerkAccelMax 0;
BA_ "GenSigTimeoutTime_BSM2" SG_ 275 PPPA_JerkAccelMin 0;
BA_ "GenSigTimeoutTime_CADM" SG_ 275 PPPA_JerkAccelMin 0;
BA_ "GenSigTimeoutTime_CVADAS" SG_ 275 PPPA_JerkAccelMin 0;
BA_ "GenSigTimeoutTime_ECM" SG_ 275 PPPA_JerkAccelMin 0;
BA_ "GenSigTimeoutTime_EPS" SG_ 275 PPPA_JerkAccelMin 0;
BA_ "GenSigTimeoutTime_EVCU2" SG_ 275 PPPA_JerkAccelMin 0;
BA_ "GenSigTimeoutTime_ORC" SG_ 275 PPPA_JerkAccelMin 0;
BA_ "GenSigTimeoutTime_BSM2" SG_ 275 PPPA_JerkDecelMax 0;
BA_ "GenSigTimeoutTime_CADM" SG_ 275 PPPA_JerkDecelMax 0;
BA_ "GenSigTimeoutTime_CVADAS" SG_ 275 PPPA_JerkDecelMax 0;
BA_ "GenSigTimeoutTime_ECM" SG_ 275 PPPA_JerkDecelMax 0;
BA_ "GenSigTimeoutTime_EPS" SG_ 275 PPPA_JerkDecelMax 0;
BA_ "GenSigTimeoutTime_EVCU2" SG_ 275 PPPA_JerkDecelMax 0;
BA_ "GenSigTimeoutTime_ORC" SG_ 275 PPPA_JerkDecelMax 0;
BA_ "GenSigTimeoutTime_BSM2" SG_ 275 PPPA_JerkDecelMin 0;
BA_ "GenSigTimeoutTime_CADM" SG_ 275 PPPA_JerkDecelMin 0;
BA_ "GenSigTimeoutTime_CVADAS" SG_ 275 PPPA_JerkDecelMin 0;
BA_ "GenSigTimeoutTime_ECM" SG_ 275 PPPA_JerkDecelMin 0;
BA_ "GenSigTimeoutTime_EPS" SG_ 275 PPPA_JerkDecelMin 0;
BA_ "GenSigTimeoutTime_EVCU2" SG_ 275 PPPA_JerkDecelMin 0;
BA_ "GenSigTimeoutTime_ORC" SG_ 275 PPPA_JerkDecelMin 0;
BA_ "GenSigTimeoutTime_BSM2" SG_ 275 PPPA_MaxSpeed 0;
BA_ "GenSigTimeoutTime_CADM" SG_ 275 PPPA_MaxSpeed 0;
BA_ "GenSigTimeoutTime_CVADAS" SG_ 275 PPPA_MaxSpeed 0;
BA_ "GenSigTimeoutTime_ECM" SG_ 275 PPPA_MaxSpeed 0;
BA_ "GenSigTimeoutTime_EPS" SG_ 275 PPPA_MaxSpeed 0;
BA_ "GenSigTimeoutTime_EVCU2" SG_ 275 PPPA_MaxSpeed 0;
BA_ "GenSigTimeoutTime_ORC" SG_ 275 PPPA_MaxSpeed 0;
BA_ "GenSigTimeoutTime_BSM2" SG_ 275 PPPA_StandstillRqst 0;
BA_ "GenSigTimeoutTime_CADM" SG_ 275 PPPA_StandstillRqst 0;
BA_ "GenSigTimeoutTime_CVADAS" SG_ 275 PPPA_StandstillRqst 0;
BA_ "GenSigTimeoutTime_ECM" SG_ 275 PPPA_StandstillRqst 0;
BA_ "GenSigTimeoutTime_EPS" SG_ 275 PPPA_StandstillRqst 0;
BA_ "GenSigTimeoutTime_EVCU2" SG_ 275 PPPA_StandstillRqst 0;
BA_ "GenSigTimeoutTime_ORC" SG_ 275 PPPA_StandstillRqst 0;
BA_ "GenSigTimeoutTime_BSM2" SG_ 275 PPPA_TargetDistance 0;
BA_ "GenSigTimeoutTime_CADM" SG_ 275 PPPA_TargetDistance 0;
BA_ "GenSigTimeoutTime_CVADAS" SG_ 275 PPPA_TargetDistance 0;
BA_ "GenSigTimeoutTime_ECM" SG_ 275 PPPA_TargetDistance 0;
BA_ "GenSigTimeoutTime_EPS" SG_ 275 PPPA_TargetDistance 0;
BA_ "GenSigTimeoutTime_EVCU2" SG_ 275 PPPA_TargetDistance 0;
BA_ "GenSigTimeoutTime_ORC" SG_ 275 PPPA_TargetDistance 0;
BA_ "GenSigTimeoutTime_BSM2" SG_ 275 RR_PAM_Brk_RqSts 0;
BA_ "GenSigTimeoutTime_CADM" SG_ 275 RR_PAM_Brk_RqSts 0;
BA_ "GenSigTimeoutTime_CVADAS" SG_ 275 RR_PAM_Brk_RqSts 0;
BA_ "GenSigTimeoutTime_ECM" SG_ 275 RR_PAM_Brk_RqSts 0;
BA_ "GenSigTimeoutTime_EPS" SG_ 275 RR_PAM_Brk_RqSts 0;
BA_ "GenSigTimeoutTime_EVCU2" SG_ 275 RR_PAM_Brk_RqSts 0;
BA_ "GenSigTimeoutTime_ORC" SG_ 275 RR_PAM_Brk_RqSts 0;
BA_ "GenSigTimeoutTime_BSM2" SG_ 275 RR_PAM_Dist 0;
BA_ "GenSigTimeoutTime_CADM" SG_ 275 RR_PAM_Dist 0;
BA_ "GenSigTimeoutTime_CVADAS" SG_ 275 RR_PAM_Dist 0;
BA_ "GenSigTimeoutTime_ECM" SG_ 275 RR_PAM_Dist 0;
BA_ "GenSigTimeoutTime_EPS" SG_ 275 RR_PAM_Dist 0;
BA_ "GenSigTimeoutTime_EVCU2" SG_ 275 RR_PAM_Dist 0;
BA_ "GenSigTimeoutTime_ORC" SG_ 275 RR_PAM_Dist 0;
BA_ "GenSigTimeoutTime_BSM" SG_ 275 SPM_Lat_Ctrl_RequestSts 0;
BA_ "GenSigTimeoutTime_BSM2" SG_ 275 SPM_Lat_Ctrl_RequestSts 0;
BA_ "GenSigTimeoutTime_CADM" SG_ 275 SPM_Lat_Ctrl_RequestSts 0;
BA_ "GenSigTimeoutTime_CVADAS" SG_ 275 SPM_Lat_Ctrl_RequestSts 0;
BA_ "GenSigTimeoutTime_ECM" SG_ 275 SPM_Lat_Ctrl_RequestSts 0;
BA_ "GenSigTimeoutTime_EVCU2" SG_ 275 SPM_Lat_Ctrl_RequestSts 0;
BA_ "GenSigStartValue" SG_ 275 TorqueOverlaySteeringReq_SPM 1024;
BA_ "GenSigTimeoutTime_BSM" SG_ 275 TorqueOverlaySteeringReq_SPM 0;
BA_ "GenSigTimeoutTime_BSM2" SG_ 275 TorqueOverlaySteeringReq_SPM 0;
BA_ "GenSigTimeoutTime_CADM" SG_ 275 TorqueOverlaySteeringReq_SPM 0;
BA_ "GenSigTimeoutTime_CVADAS" SG_ 275 TorqueOverlaySteeringReq_SPM 0;
BA_ "GenSigTimeoutTime_ECM" SG_ 275 TorqueOverlaySteeringReq_SPM 0;
BA_ "GenSigTimeoutTime_EVCU2" SG_ 275 TorqueOverlaySteeringReq_SPM 0;
BA_ "GenSigTimeoutTime_BSM" SG_ 726 CRC_CVPAM_FD_Data 0;
BA_ "GenSigTimeoutTime_BSM2" SG_ 726 CRC_CVPAM_FD_Data 0;
BA_ "GenSigTimeoutTime_CVADAS" SG_ 726 CRC_CVPAM_FD_Data 0;
BA_ "GenSigTimeoutTime_ECM" SG_ 726 CRC_CVPAM_FD_Data 0;
BA_ "GenSigTimeoutTime_EPS" SG_ 726 CRC_CVPAM_FD_Data 0;
BA_ "GenSigTimeoutTime_EVCU2" SG_ 726 CRC_CVPAM_FD_Data 0;
BA_ "GenSigTimeoutTime_ORC" SG_ 726 CRC_CVPAM_FD_Data 0;
BA_ "GenSigTimeoutTime_BSM" SG_ 726 MessageCounter_CVPAM_FD_Data 0;
BA_ "GenSigTimeoutTime_BSM2" SG_ 726 MessageCounter_CVPAM_FD_Data 0;
BA_ "GenSigTimeoutTime_CVADAS" SG_ 726 MessageCounter_CVPAM_FD_Data 0;
BA_ "GenSigTimeoutTime_ECM" SG_ 726 MessageCounter_CVPAM_FD_Data 0;
BA_ "GenSigTimeoutTime_EPS" SG_ 726 MessageCounter_CVPAM_FD_Data 0;
BA_ "GenSigTimeoutTime_EVCU2" SG_ 726 MessageCounter_CVPAM_FD_Data 0;
BA_ "GenSigTimeoutTime_ORC" SG_ 726 MessageCounter_CVPAM_FD_Data 0;
BA_ "GenSigTimeoutTime_BSM" SG_ 727 CRC_CVPAM_FD_Data2 0;
BA_ "GenSigTimeoutTime_BSM2" SG_ 727 CRC_CVPAM_FD_Data2 0;
BA_ "GenSigTimeoutTime_CVADAS" SG_ 727 CRC_CVPAM_FD_Data2 0;
BA_ "GenSigTimeoutTime_ECM" SG_ 727 CRC_CVPAM_FD_Data2 0;
BA_ "GenSigTimeoutTime_EPS" SG_ 727 CRC_CVPAM_FD_Data2 0;
BA_ "GenSigTimeoutTime_EVCU2" SG_ 727 CRC_CVPAM_FD_Data2 0;
BA_ "GenSigTimeoutTime_ORC" SG_ 727 CRC_CVPAM_FD_Data2 0;
BA_ "GenSigTimeoutTime_BSM" SG_ 727 MessageCounter_CVPAM_FD_Data2 0;
BA_ "GenSigTimeoutTime_BSM2" SG_ 727 MessageCounter_CVPAM_FD_Data2 0;
BA_ "GenSigTimeoutTime_CVADAS" SG_ 727 MessageCounter_CVPAM_FD_Data2 0;
BA_ "GenSigTimeoutTime_ECM" SG_ 727 MessageCounter_CVPAM_FD_Data2 0;
BA_ "GenSigTimeoutTime_EPS" SG_ 727 MessageCounter_CVPAM_FD_Data2 0;
BA_ "GenSigTimeoutTime_EVCU2" SG_ 727 MessageCounter_CVPAM_FD_Data2 0;
BA_ "GenSigTimeoutTime_ORC" SG_ 727 MessageCounter_CVPAM_FD_Data2 0;
BA_ "GenSigSendType" SG_ 950 ParkingManeuverActive 3;
BA_ "GenSigTimeoutTime_BSM2" SG_ 950 ParkingManeuverActive 0;
BA_ "GenSigTimeoutTime_CADM" SG_ 950 ParkingManeuverActive 0;
BA_ "GenSigTimeoutTime_CVADAS" SG_ 950 ParkingManeuverActive 0;
BA_ "GenSigTimeoutTime_ECM" SG_ 950 ParkingManeuverActive 0;
BA_ "GenSigTimeoutTime_EPS" SG_ 950 ParkingManeuverActive 0;
BA_ "GenSigTimeoutTime_EVCU2" SG_ 950 ParkingManeuverActive 0;
BA_ "GenSigTimeoutTime_ORC" SG_ 950 ParkingManeuverActive 0;
BA_ "GenSigTimeoutTime_BSM" SG_ 1054 CRC_ENGINE1 0;
BA_ "GenSigTimeoutTime_BSM2" SG_ 1054 CRC_ENGINE1 0;
BA_ "GenSigTimeoutTime_CVADAS" SG_ 1054 CRC_ENGINE1 0;
BA_ "GenSigTimeoutTime_ECM" SG_ 1054 CRC_ENGINE1 0;
BA_ "GenSigTimeoutTime_EPS" SG_ 1054 CRC_ENGINE1 0;
BA_ "GenSigTimeoutTime_EVCU2" SG_ 1054 CRC_ENGINE1 0;
BA_ "GenSigTimeoutTime_ORC" SG_ 1054 CRC_ENGINE1 0;
BA_ "GenSigTimeoutTime_BSM" SG_ 1054 MessageCounter_ENGINE1 0;
BA_ "GenSigTimeoutTime_BSM2" SG_ 1054 MessageCounter_ENGINE1 0;
BA_ "GenSigTimeoutTime_CVADAS" SG_ 1054 MessageCounter_ENGINE1 0;
BA_ "GenSigTimeoutTime_ECM" SG_ 1054 MessageCounter_ENGINE1 0;
BA_ "GenSigTimeoutTime_EPS" SG_ 1054 MessageCounter_ENGINE1 0;
BA_ "GenSigTimeoutTime_EVCU2" SG_ 1054 MessageCounter_ENGINE1 0;
BA_ "GenSigTimeoutTime_ORC" SG_ 1054 MessageCounter_ENGINE1 0;
BA_ "GenSigTimeoutTime_BSM" SG_ 1054 ThermalManagementActive_W 0;
BA_ "GenSigTimeoutTime_BSM2" SG_ 1054 ThermalManagementActive_W 0;
BA_ "GenSigTimeoutTime_CVADAS" SG_ 1054 ThermalManagementActive_W 0;
BA_ "GenSigTimeoutTime_ECM" SG_ 1054 ThermalManagementActive_W 0;
BA_ "GenSigTimeoutTime_EPS" SG_ 1054 ThermalManagementActive_W 0;
BA_ "GenSigTimeoutTime_EVCU2" SG_ 1054 ThermalManagementActive_W 0;
BA_ "GenSigTimeoutTime_ORC" SG_ 1054 ThermalManagementActive_W 0;
BA_ "GenSigTimeoutTime_BSM2" SG_ 262 CRC_ENGINE2 0;
BA_ "GenSigTimeoutTime_ECM" SG_ 262 CRC_ENGINE2 0;
BA_ "GenSigTimeoutTime_EVCU2" SG_ 262 CRC_ENGINE2 0;
BA_ "GenSigTimeoutTime_ORC" SG_ 262 CRC_ENGINE2 0;
BA_ "GenSigTimeoutTime_BSM" SG_ 262 ECM_LHOM_W 0;
BA_ "GenSigTimeoutTime_BSM2" SG_ 262 ECM_LHOM_W 0;
BA_ "GenSigTimeoutTime_CVADAS" SG_ 262 ECM_LHOM_W 0;
BA_ "GenSigTimeoutTime_ECM" SG_ 262 ECM_LHOM_W 0;
BA_ "GenSigTimeoutTime_EPS" SG_ 262 ECM_LHOM_W 0;
BA_ "GenSigTimeoutTime_EVCU2" SG_ 262 ECM_LHOM_W 0;
BA_ "GenSigTimeoutTime_ORC" SG_ 262 ECM_LHOM_W 0;
BA_ "GenSigTimeoutTime_BSM2" SG_ 262 EngineSpeed_W 0;
BA_ "GenSigTimeoutTime_CVADAS" SG_ 262 EngineSpeed_W 0;
BA_ "GenSigTimeoutTime_ECM" SG_ 262 EngineSpeed_W 0;
BA_ "GenSigTimeoutTime_EVCU2" SG_ 262 EngineSpeed_W 0;
BA_ "GenSigTimeoutTime_ORC" SG_ 262 EngineSpeed_W 0;
BA_ "GenSigStartValue" SG_ 262 EngineSts_W 3;
BA_ "GenSigTimeoutTime_BSM2" SG_ 262 EngineSts_W 0;
BA_ "GenSigTimeoutTime_ECM" SG_ 262 EngineSts_W 0;
BA_ "GenSigTimeoutTime_EPS" SG_ 262 EngineSts_W 0;
BA_ "GenSigTimeoutTime_EVCU2" SG_ 262 EngineSts_W 0;
BA_ "GenSigTimeoutTime_ORC" SG_ 262 EngineSts_W 0;
BA_ "GenSigStartValue" SG_ 262 ESS_ENG_ST_W 15;
BA_ "GenSigSendType" SG_ 262 ESS_ENG_ST_W 3;
BA_ "GenSigTimeoutTime_BSM2" SG_ 262 ESS_ENG_ST_W 0;
BA_ "GenSigTimeoutTime_ECM" SG_ 262 ESS_ENG_ST_W 0;
BA_ "GenSigTimeoutTime_EVCU2" SG_ 262 ESS_ENG_ST_W 0;
BA_ "GenSigTimeoutTime_ORC" SG_ 262 ESS_ENG_ST_W 0;
BA_ "GenSigTimeoutTime_BSM2" SG_ 262 GasPedalPosition_W 0;
BA_ "GenSigTimeoutTime_CADM" SG_ 262 GasPedalPosition_W 0;
BA_ "GenSigTimeoutTime_CVADAS" SG_ 262 GasPedalPosition_W 0;
BA_ "GenSigTimeoutTime_ECM" SG_ 262 GasPedalPosition_W 0;
BA_ "GenSigTimeoutTime_EPS" SG_ 262 GasPedalPosition_W 0;
BA_ "GenSigTimeoutTime_EVCU2" SG_ 262 GasPedalPosition_W 0;
BA_ "GenSigTimeoutTime_ORC" SG_ 262 GasPedalPosition_W 0;
BA_ "GenSigTimeoutTime_BSM2" SG_ 262 GasPedalPositionFailSts_W 0;
BA_ "GenSigTimeoutTime_CVADAS" SG_ 262 GasPedalPositionFailSts_W 0;
BA_ "GenSigTimeoutTime_ECM" SG_ 262 GasPedalPositionFailSts_W 0;
BA_ "GenSigTimeoutTime_EPS" SG_ 262 GasPedalPositionFailSts_W 0;
BA_ "GenSigTimeoutTime_EVCU2" SG_ 262 GasPedalPositionFailSts_W 0;
BA_ "GenSigTimeoutTime_ORC" SG_ 262 GasPedalPositionFailSts_W 0;
BA_ "GenSigTimeoutTime_BSM" SG_ 262 LV12PwrFreeRq_W 0;
BA_ "GenSigTimeoutTime_BSM2" SG_ 262 LV12PwrFreeRq_W 0;
BA_ "GenSigTimeoutTime_CADM" SG_ 262 LV12PwrFreeRq_W 0;
BA_ "GenSigTimeoutTime_CVADAS" SG_ 262 LV12PwrFreeRq_W 0;
BA_ "GenSigTimeoutTime_ECM" SG_ 262 LV12PwrFreeRq_W 0;
BA_ "GenSigTimeoutTime_EPS" SG_ 262 LV12PwrFreeRq_W 0;
BA_ "GenSigTimeoutTime_EVCU2" SG_ 262 LV12PwrFreeRq_W 0;
BA_ "GenSigTimeoutTime_ORC" SG_ 262 LV12PwrFreeRq_W 0;
BA_ "GenSigTimeoutTime_BSM2" SG_ 262 MessageCounter_ENGINE2 0;
BA_ "GenSigTimeoutTime_ECM" SG_ 262 MessageCounter_ENGINE2 0;
BA_ "GenSigTimeoutTime_EVCU2" SG_ 262 MessageCounter_ENGINE2 0;
BA_ "GenSigTimeoutTime_ORC" SG_ 262 MessageCounter_ENGINE2 0;
BA_ "GenSigTimeoutTime_BSM2" SG_ 262 PowertrainPrplsnActv 0;
BA_ "GenSigTimeoutTime_CVADAS" SG_ 262 PowertrainPrplsnActv 0;
BA_ "GenSigTimeoutTime_ECM" SG_ 262 PowertrainPrplsnActv 0;
BA_ "GenSigTimeoutTime_EPS" SG_ 262 PowertrainPrplsnActv 0;
BA_ "GenSigTimeoutTime_EVCU2" SG_ 262 PowertrainPrplsnActv 0;
BA_ "GenSigTimeoutTime_ORC" SG_ 262 PowertrainPrplsnActv 0;
BA_ "GenSigTimeoutTime_BSM2" SG_ 1036 CRC_ENGINE3 0;
BA_ "GenSigTimeoutTime_CADM" SG_ 1036 CRC_ENGINE3 0;
BA_ "GenSigTimeoutTime_CVADAS" SG_ 1036 CRC_ENGINE3 0;
BA_ "GenSigTimeoutTime_ECM" SG_ 1036 CRC_ENGINE3 0;
BA_ "GenSigTimeoutTime_EPS" SG_ 1036 CRC_ENGINE3 0;
BA_ "GenSigTimeoutTime_EVCU2" SG_ 1036 CRC_ENGINE3 0;
BA_ "GenSigTimeoutTime_ORC" SG_ 1036 CRC_ENGINE3 0;
BA_ "GenSigTimeoutTime_BSM2" SG_ 1036 MessageCounter_ENGINE3 0;
BA_ "GenSigTimeoutTime_CADM" SG_ 1036 MessageCounter_ENGINE3 0;
BA_ "GenSigTimeoutTime_CVADAS" SG_ 1036 MessageCounter_ENGINE3 0;
BA_ "GenSigTimeoutTime_ECM" SG_ 1036 MessageCounter_ENGINE3 0;
BA_ "GenSigTimeoutTime_EPS" SG_ 1036 MessageCounter_ENGINE3 0;
BA_ "GenSigTimeoutTime_EVCU2" SG_ 1036 MessageCounter_ENGINE3 0;
BA_ "GenSigTimeoutTime_ORC" SG_ 1036 MessageCounter_ENGINE3 0;
BA_ "GenSigTimeoutTime_CVADAS" SG_ 518 CRC_ENGINE5 0;
BA_ "GenSigTimeoutTime_ECM" SG_ 518 CRC_ENGINE5 0;
BA_ "GenSigTimeoutTime_EPS" SG_ 518 CRC_ENGINE5 0;
BA_ "GenSigTimeoutTime_EVCU2" SG_ 518 CRC_ENGINE5 0;
BA_ "GenSigTimeoutTime_ORC" SG_ 518 CRC_ENGINE5 0;
BA_ "GenSigTimeoutTime_CVADAS" SG_ 518 MessageCounter_ENGINE5 0;
BA_ "GenSigTimeoutTime_ECM" SG_ 518 MessageCounter_ENGINE5 0;
BA_ "GenSigTimeoutTime_EPS" SG_ 518 MessageCounter_ENGINE5 0;
BA_ "GenSigTimeoutTime_EVCU2" SG_ 518 MessageCounter_ENGINE5 0;
BA_ "GenSigTimeoutTime_ORC" SG_ 518 MessageCounter_ENGINE5 0;
BA_ "GenSigStartValue" SG_ 518 PdlPosActual 1;
BA_ "GenSigTimeoutTime_ECM" SG_ 518 PdlPosActual 0;
BA_ "GenSigTimeoutTime_EPS" SG_ 518 PdlPosActual 0;
BA_ "GenSigTimeoutTime_EVCU2" SG_ 518 PdlPosActual 0;
BA_ "GenSigTimeoutTime_ORC" SG_ 518 PdlPosActual 0;
BA_ "GenSigTimeoutTime_BSM" SG_ 518 RPMOverRev_W 0;
BA_ "GenSigTimeoutTime_BSM2" SG_ 518 RPMOverRev_W 0;
BA_ "GenSigTimeoutTime_CVADAS" SG_ 518 RPMOverRev_W 0;
BA_ "GenSigTimeoutTime_ECM" SG_ 518 RPMOverRev_W 0;
BA_ "GenSigTimeoutTime_EPS" SG_ 518 RPMOverRev_W 0;
BA_ "GenSigTimeoutTime_EVCU2" SG_ 518 RPMOverRev_W 0;
BA_ "GenSigTimeoutTime_ORC" SG_ 518 RPMOverRev_W 0;
BA_ "GenSigSendType" SG_ 1448 ECM_THA_Resp 4;
BA_ "GenSigTimeoutTime_BSM" SG_ 1448 ECM_THA_Resp 0;
BA_ "GenSigTimeoutTime_BSM2" SG_ 1448 ECM_THA_Resp 0;
BA_ "GenSigTimeoutTime_CADM" SG_ 1448 ECM_THA_Resp 0;
BA_ "GenSigTimeoutTime_ECM" SG_ 1448 ECM_THA_Resp 0;
BA_ "GenSigTimeoutTime_EPS" SG_ 1448 ECM_THA_Resp 0;
BA_ "GenSigTimeoutTime_EVCU2" SG_ 1448 ECM_THA_Resp 0;
BA_ "GenSigTimeoutTime_ORC" SG_ 1448 ECM_THA_Resp 0;
BA_ "GenSigSendType" SG_ 1448 ECM_TRSC_Resp 3;
BA_ "GenSigTimeoutTime_BSM" SG_ 1448 ECM_TRSC_Resp 0;
BA_ "GenSigTimeoutTime_BSM2" SG_ 1448 ECM_TRSC_Resp 0;
BA_ "GenSigTimeoutTime_CADM" SG_ 1448 ECM_TRSC_Resp 0;
BA_ "GenSigTimeoutTime_ECM" SG_ 1448 ECM_TRSC_Resp 0;
BA_ "GenSigTimeoutTime_EPS" SG_ 1448 ECM_TRSC_Resp 0;
BA_ "GenSigTimeoutTime_EVCU2" SG_ 1448 ECM_TRSC_Resp 0;
BA_ "GenSigTimeoutTime_ORC" SG_ 1448 ECM_TRSC_Resp 0;
BA_ "GenSigTimeoutTime_BSM2" SG_ 264 CRC_EPS1 0;
BA_ "GenSigTimeoutTime_ECM" SG_ 264 CRC_EPS1 0;
BA_ "GenSigTimeoutTime_EPS" SG_ 264 CRC_EPS1 0;
BA_ "GenSigTimeoutTime_EVCU2" SG_ 264 CRC_EPS1 0;
BA_ "GenSigTimeoutTime_BSM" SG_ 264 ElectricSteeringFailSts 0;
BA_ "GenSigTimeoutTime_BSM2" SG_ 264 ElectricSteeringFailSts 0;
BA_ "GenSigTimeoutTime_CADM" SG_ 264 ElectricSteeringFailSts 0;
BA_ "GenSigTimeoutTime_CVADAS" SG_ 264 ElectricSteeringFailSts 0;
BA_ "GenSigTimeoutTime_ECM" SG_ 264 ElectricSteeringFailSts 0;
BA_ "GenSigTimeoutTime_EPS" SG_ 264 ElectricSteeringFailSts 0;
BA_ "GenSigTimeoutTime_EVCU2" SG_ 264 ElectricSteeringFailSts 0;
BA_ "GenSigTimeoutTime_ORC" SG_ 264 ElectricSteeringFailSts 0;
BA_ "GenSigTimeoutTime_BSM" SG_ 264 EngineFanRequestActivation 0;
BA_ "GenSigTimeoutTime_BSM2" SG_ 264 EngineFanRequestActivation 0;
BA_ "GenSigTimeoutTime_CADM" SG_ 264 EngineFanRequestActivation 0;
BA_ "GenSigTimeoutTime_CVADAS" SG_ 264 EngineFanRequestActivation 0;
BA_ "GenSigTimeoutTime_ECM" SG_ 264 EngineFanRequestActivation 0;
BA_ "GenSigTimeoutTime_EPS" SG_ 264 EngineFanRequestActivation 0;
BA_ "GenSigTimeoutTime_EVCU2" SG_ 264 EngineFanRequestActivation 0;
BA_ "GenSigTimeoutTime_ORC" SG_ 264 EngineFanRequestActivation 0;
BA_ "GenSigTimeoutTime_BSM" SG_ 264 EPS_ADAS_IMC_Fault 0;
BA_ "GenSigTimeoutTime_BSM2" SG_ 264 EPS_ADAS_IMC_Fault 0;
BA_ "GenSigTimeoutTime_CVADAS" SG_ 264 EPS_ADAS_IMC_Fault 0;
BA_ "GenSigTimeoutTime_ECM" SG_ 264 EPS_ADAS_IMC_Fault 0;
BA_ "GenSigTimeoutTime_EPS" SG_ 264 EPS_ADAS_IMC_Fault 0;
BA_ "GenSigTimeoutTime_EVCU2" SG_ 264 EPS_ADAS_IMC_Fault 0;
BA_ "GenSigTimeoutTime_ORC" SG_ 264 EPS_ADAS_IMC_Fault 0;
BA_ "GenSigStartValue" SG_ 264 EPS_AsstStat 1;
BA_ "GenSigTimeoutTime_BSM" SG_ 264 EPS_AsstStat 0;
BA_ "GenSigTimeoutTime_BSM2" SG_ 264 EPS_AsstStat 0;
BA_ "GenSigTimeoutTime_CVADAS" SG_ 264 EPS_AsstStat 0;
BA_ "GenSigTimeoutTime_ECM" SG_ 264 EPS_AsstStat 0;
BA_ "GenSigTimeoutTime_EPS" SG_ 264 EPS_AsstStat 0;
BA_ "GenSigTimeoutTime_EVCU2" SG_ 264 EPS_AsstStat 0;
BA_ "GenSigTimeoutTime_ORC" SG_ 264 EPS_AsstStat 0;
BA_ "GenSigStartValue" SG_ 264 EPS_Curr 255;
BA_ "GenSigTimeoutTime_BSM" SG_ 264 EPS_Curr 0;
BA_ "GenSigTimeoutTime_BSM2" SG_ 264 EPS_Curr 0;
BA_ "GenSigTimeoutTime_CADM" SG_ 264 EPS_Curr 0;
BA_ "GenSigTimeoutTime_CVADAS" SG_ 264 EPS_Curr 0;
BA_ "GenSigTimeoutTime_ECM" SG_ 264 EPS_Curr 0;
BA_ "GenSigTimeoutTime_EPS" SG_ 264 EPS_Curr 0;
BA_ "GenSigTimeoutTime_EVCU2" SG_ 264 EPS_Curr 0;
BA_ "GenSigTimeoutTime_ORC" SG_ 264 EPS_Curr 0;
BA_ "GenSigTimeoutTime_BSM" SG_ 264 EPS_Hands_On_Sts 0;
BA_ "GenSigTimeoutTime_BSM2" SG_ 264 EPS_Hands_On_Sts 0;
BA_ "GenSigTimeoutTime_CVADAS" SG_ 264 EPS_Hands_On_Sts 0;
BA_ "GenSigTimeoutTime_ECM" SG_ 264 EPS_Hands_On_Sts 0;
BA_ "GenSigTimeoutTime_EPS" SG_ 264 EPS_Hands_On_Sts 0;
BA_ "GenSigTimeoutTime_EVCU2" SG_ 264 EPS_Hands_On_Sts 0;
BA_ "GenSigTimeoutTime_BSM" SG_ 264 EPS_HandsOnRecognition 0;
BA_ "GenSigTimeoutTime_BSM2" SG_ 264 EPS_HandsOnRecognition 0;
BA_ "GenSigTimeoutTime_CADM" SG_ 264 EPS_HandsOnRecognition 0;
BA_ "GenSigTimeoutTime_ECM" SG_ 264 EPS_HandsOnRecognition 0;
BA_ "GenSigTimeoutTime_EPS" SG_ 264 EPS_HandsOnRecognition 0;
BA_ "GenSigTimeoutTime_EVCU2" SG_ 264 EPS_HandsOnRecognition 0;
BA_ "GenSigStartValue" SG_ 264 EPSMotorTorque 1024;
BA_ "GenSigTimeoutTime_BSM" SG_ 264 EPSMotorTorque 0;
BA_ "GenSigTimeoutTime_BSM2" SG_ 264 EPSMotorTorque 0;
BA_ "GenSigTimeoutTime_CVADAS" SG_ 264 EPSMotorTorque 0;
BA_ "GenSigTimeoutTime_ECM" SG_ 264 EPSMotorTorque 0;
BA_ "GenSigTimeoutTime_EPS" SG_ 264 EPSMotorTorque 0;
BA_ "GenSigTimeoutTime_EVCU2" SG_ 264 EPSMotorTorque 0;
BA_ "GenSigTimeoutTime_BSM2" SG_ 264 ESA_LAT_CTRL_ResponseSts 0;
BA_ "GenSigTimeoutTime_CVADAS" SG_ 264 ESA_LAT_CTRL_ResponseSts 0;
BA_ "GenSigTimeoutTime_ECM" SG_ 264 ESA_LAT_CTRL_ResponseSts 0;
BA_ "GenSigTimeoutTime_EPS" SG_ 264 ESA_LAT_CTRL_ResponseSts 0;
BA_ "GenSigTimeoutTime_EVCU2" SG_ 264 ESA_LAT_CTRL_ResponseSts 0;
BA_ "GenSigTimeoutTime_ORC" SG_ 264 ESA_LAT_CTRL_ResponseSts 0;
BA_ "GenSigTimeoutTime_BSM" SG_ 264 HAS_LAT_CTRL_ResponseSts 0;
BA_ "GenSigTimeoutTime_BSM2" SG_ 264 HAS_LAT_CTRL_ResponseSts 0;
BA_ "GenSigTimeoutTime_CVADAS" SG_ 264 HAS_LAT_CTRL_ResponseSts 0;
BA_ "GenSigTimeoutTime_ECM" SG_ 264 HAS_LAT_CTRL_ResponseSts 0;
BA_ "GenSigTimeoutTime_EPS" SG_ 264 HAS_LAT_CTRL_ResponseSts 0;
BA_ "GenSigTimeoutTime_EVCU2" SG_ 264 HAS_LAT_CTRL_ResponseSts 0;
BA_ "GenSigTimeoutTime_BSM" SG_ 264 LKA_LAT_CTRL_ResponseSts 0;
BA_ "GenSigTimeoutTime_BSM2" SG_ 264 LKA_LAT_CTRL_ResponseSts 0;
BA_ "GenSigTimeoutTime_CVADAS" SG_ 264 LKA_LAT_CTRL_ResponseSts 0;
BA_ "GenSigTimeoutTime_ECM" SG_ 264 LKA_LAT_CTRL_ResponseSts 0;
BA_ "GenSigTimeoutTime_EPS" SG_ 264 LKA_LAT_CTRL_ResponseSts 0;
BA_ "GenSigTimeoutTime_EVCU2" SG_ 264 LKA_LAT_CTRL_ResponseSts 0;
BA_ "GenSigTimeoutTime_BSM2" SG_ 264 LwsAngle 0;
BA_ "GenSigTimeoutTime_ECM" SG_ 264 LwsAngle 0;
BA_ "GenSigTimeoutTime_EPS" SG_ 264 LwsAngle 0;
BA_ "GenSigTimeoutTime_ORC" SG_ 264 LwsAngle 0;
BA_ "GenSigTimeoutTime_BSM2" SG_ 264 LwsAngleType 0;
BA_ "GenSigTimeoutTime_ECM" SG_ 264 LwsAngleType 0;
BA_ "GenSigTimeoutTime_EPS" SG_ 264 LwsAngleType 0;
BA_ "GenSigTimeoutTime_EVCU2" SG_ 264 LwsAngleType 0;
BA_ "GenSigTimeoutTime_ORC" SG_ 264 LwsAngleType 0;
BA_ "GenSigTimeoutTime_BSM2" SG_ 264 LwsCalibration 0;
BA_ "GenSigTimeoutTime_CVADAS" SG_ 264 LwsCalibration 0;
BA_ "GenSigTimeoutTime_ECM" SG_ 264 LwsCalibration 0;
BA_ "GenSigTimeoutTime_EPS" SG_ 264 LwsCalibration 0;
BA_ "GenSigTimeoutTime_EVCU2" SG_ 264 LwsCalibration 0;
BA_ "GenSigTimeoutTime_ORC" SG_ 264 LwsCalibration 0;
BA_ "GenSigTimeoutTime_BSM" SG_ 264 LwsSpeed 0;
BA_ "GenSigTimeoutTime_BSM2" SG_ 264 LwsSpeed 0;
BA_ "GenSigTimeoutTime_ECM" SG_ 264 LwsSpeed 0;
BA_ "GenSigTimeoutTime_EPS" SG_ 264 LwsSpeed 0;
BA_ "GenSigTimeoutTime_ORC" SG_ 264 LwsSpeed 0;
BA_ "GenSigTimeoutTime_BSM2" SG_ 264 MessageCounter_EPS1 0;
BA_ "GenSigTimeoutTime_ECM" SG_ 264 MessageCounter_EPS1 0;
BA_ "GenSigTimeoutTime_EPS" SG_ 264 MessageCounter_EPS1 0;
BA_ "GenSigTimeoutTime_EVCU2" SG_ 264 MessageCounter_EPS1 0;
BA_ "GenSigTimeoutTime_BSM" SG_ 264 SPM_Lat_Ctrl_ResponseSts 0;
BA_ "GenSigTimeoutTime_BSM2" SG_ 264 SPM_Lat_Ctrl_ResponseSts 0;
BA_ "GenSigTimeoutTime_CADM" SG_ 264 SPM_Lat_Ctrl_ResponseSts 0;
BA_ "GenSigTimeoutTime_ECM" SG_ 264 SPM_Lat_Ctrl_ResponseSts 0;
BA_ "GenSigTimeoutTime_EPS" SG_ 264 SPM_Lat_Ctrl_ResponseSts 0;
BA_ "GenSigTimeoutTime_EVCU2" SG_ 264 SPM_Lat_Ctrl_ResponseSts 0;
BA_ "GenSigTimeoutTime_BSM" SG_ 264 Steering_Column_Torque 0;
BA_ "GenSigTimeoutTime_BSM2" SG_ 264 Steering_Column_Torque 0;
BA_ "GenSigTimeoutTime_ECM" SG_ 264 Steering_Column_Torque 0;
BA_ "GenSigTimeoutTime_EPS" SG_ 264 Steering_Column_Torque 0;
BA_ "GenSigTimeoutTime_EVCU2" SG_ 264 Steering_Column_Torque 0;
BA_ "GenSigTimeoutTime_ORC" SG_ 264 Steering_Column_Torque 0;
BA_ "GenSigTimeoutTime_BSM" SG_ 264 Steering_OpStat_Prim 0;
BA_ "GenSigTimeoutTime_BSM2" SG_ 264 Steering_OpStat_Prim 0;
BA_ "GenSigTimeoutTime_CVADAS" SG_ 264 Steering_OpStat_Prim 0;
BA_ "GenSigTimeoutTime_ECM" SG_ 264 Steering_OpStat_Prim 0;
BA_ "GenSigTimeoutTime_EPS" SG_ 264 Steering_OpStat_Prim 0;
BA_ "GenSigTimeoutTime_EVCU2" SG_ 264 Steering_OpStat_Prim 0;
BA_ "GenSigTimeoutTime_BSM" SG_ 264 SteeringVibration_Fault 0;
BA_ "GenSigTimeoutTime_BSM2" SG_ 264 SteeringVibration_Fault 0;
BA_ "GenSigTimeoutTime_CVADAS" SG_ 264 SteeringVibration_Fault 0;
BA_ "GenSigTimeoutTime_ECM" SG_ 264 SteeringVibration_Fault 0;
BA_ "GenSigTimeoutTime_EPS" SG_ 264 SteeringVibration_Fault 0;
BA_ "GenSigTimeoutTime_EVCU2" SG_ 264 SteeringVibration_Fault 0;
BA_ "GenSigTimeoutTime_ORC" SG_ 264 SteeringVibration_Fault 0;
BA_ "GenSigTimeoutTime_BSM" SG_ 264 SteeringVibration_Status 0;
BA_ "GenSigTimeoutTime_BSM2" SG_ 264 SteeringVibration_Status 0;
BA_ "GenSigTimeoutTime_CVADAS" SG_ 264 SteeringVibration_Status 0;
BA_ "GenSigTimeoutTime_ECM" SG_ 264 SteeringVibration_Status 0;
BA_ "GenSigTimeoutTime_EPS" SG_ 264 SteeringVibration_Status 0;
BA_ "GenSigTimeoutTime_EVCU2" SG_ 264 SteeringVibration_Status 0;
BA_ "GenSigTimeoutTime_BSM" SG_ 1056 EPS_MODE_STAT 0;
BA_ "GenSigTimeoutTime_BSM2" SG_ 1056 EPS_MODE_STAT 0;
BA_ "GenSigTimeoutTime_CADM" SG_ 1056 EPS_MODE_STAT 0;
BA_ "GenSigTimeoutTime_CVADAS" SG_ 1056 EPS_MODE_STAT 0;
BA_ "GenSigTimeoutTime_ECM" SG_ 1056 EPS_MODE_STAT 0;
BA_ "GenSigTimeoutTime_EPS" SG_ 1056 EPS_MODE_STAT 0;
BA_ "GenSigTimeoutTime_EVCU2" SG_ 1056 EPS_MODE_STAT 0;
BA_ "GenSigTimeoutTime_ORC" SG_ 1056 EPS_MODE_STAT 0;
BA_ "GenSigTimeoutTime_BSM" SG_ 1056 EPS_SteeringTouchStat 0;
BA_ "GenSigTimeoutTime_BSM2" SG_ 1056 EPS_SteeringTouchStat 0;
BA_ "GenSigTimeoutTime_CADM" SG_ 1056 EPS_SteeringTouchStat 0;
BA_ "GenSigTimeoutTime_ECM" SG_ 1056 EPS_SteeringTouchStat 0;
BA_ "GenSigTimeoutTime_EPS" SG_ 1056 EPS_SteeringTouchStat 0;
BA_ "GenSigTimeoutTime_EVCU2" SG_ 1056 EPS_SteeringTouchStat 0;
BA_ "GenSigTimeoutTime_ORC" SG_ 1056 EPS_SteeringTouchStat 0;
BA_ "GenSigTimeoutTime_BSM" SG_ 1056 EPS_SteeringTouq_Resp 0;
BA_ "GenSigTimeoutTime_BSM2" SG_ 1056 EPS_SteeringTouq_Resp 0;
BA_ "GenSigTimeoutTime_CADM" SG_ 1056 EPS_SteeringTouq_Resp 0;
BA_ "GenSigTimeoutTime_ECM" SG_ 1056 EPS_SteeringTouq_Resp 0;
BA_ "GenSigTimeoutTime_EPS" SG_ 1056 EPS_SteeringTouq_Resp 0;
BA_ "GenSigTimeoutTime_EVCU2" SG_ 1056 EPS_SteeringTouq_Resp 0;
BA_ "GenSigTimeoutTime_ORC" SG_ 1056 EPS_SteeringTouq_Resp 0;
BA_ "GenSigTimeoutTime_BSM" SG_ 1056 EPS_THA_DriverTorqueOverride 0;
BA_ "GenSigTimeoutTime_BSM2" SG_ 1056 EPS_THA_DriverTorqueOverride 0;
BA_ "GenSigTimeoutTime_CADM" SG_ 1056 EPS_THA_DriverTorqueOverride 0;
BA_ "GenSigTimeoutTime_ECM" SG_ 1056 EPS_THA_DriverTorqueOverride 0;
BA_ "GenSigTimeoutTime_EPS" SG_ 1056 EPS_THA_DriverTorqueOverride 0;
BA_ "GenSigTimeoutTime_EVCU2" SG_ 1056 EPS_THA_DriverTorqueOverride 0;
BA_ "GenSigTimeoutTime_ORC" SG_ 1056 EPS_THA_DriverTorqueOverride 0;
BA_ "GenSigTimeoutTime_BSM" SG_ 1056 EPS_THA_SteeringTorqueResp 0;
BA_ "GenSigTimeoutTime_BSM2" SG_ 1056 EPS_THA_SteeringTorqueResp 0;
BA_ "GenSigTimeoutTime_CADM" SG_ 1056 EPS_THA_SteeringTorqueResp 0;
BA_ "GenSigTimeoutTime_ECM" SG_ 1056 EPS_THA_SteeringTorqueResp 0;
BA_ "GenSigTimeoutTime_EPS" SG_ 1056 EPS_THA_SteeringTorqueResp 0;
BA_ "GenSigTimeoutTime_EVCU2" SG_ 1056 EPS_THA_SteeringTorqueResp 0;
BA_ "GenSigTimeoutTime_ORC" SG_ 1056 EPS_THA_SteeringTorqueResp 0;
BA_ "GenSigTimeoutTime_BSM" SG_ 1056 EPS_Warn_Disp_Rq 0;
BA_ "GenSigTimeoutTime_BSM2" SG_ 1056 EPS_Warn_Disp_Rq 0;
BA_ "GenSigTimeoutTime_CADM" SG_ 1056 EPS_Warn_Disp_Rq 0;
BA_ "GenSigTimeoutTime_CVADAS" SG_ 1056 EPS_Warn_Disp_Rq 0;
BA_ "GenSigTimeoutTime_ECM" SG_ 1056 EPS_Warn_Disp_Rq 0;
BA_ "GenSigTimeoutTime_EPS" SG_ 1056 EPS_Warn_Disp_Rq 0;
BA_ "GenSigTimeoutTime_EVCU2" SG_ 1056 EPS_Warn_Disp_Rq 0;
BA_ "GenSigTimeoutTime_ORC" SG_ 1056 EPS_Warn_Disp_Rq 0;
BA_ "GenSigTimeoutTime_BSM" SG_ 1056 THA_SteeringTouchStat 0;
BA_ "GenSigTimeoutTime_BSM2" SG_ 1056 THA_SteeringTouchStat 0;
BA_ "GenSigTimeoutTime_CADM" SG_ 1056 THA_SteeringTouchStat 0;
BA_ "GenSigTimeoutTime_ECM" SG_ 1056 THA_SteeringTouchStat 0;
BA_ "GenSigTimeoutTime_EPS" SG_ 1056 THA_SteeringTouchStat 0;
BA_ "GenSigTimeoutTime_EVCU2" SG_ 1056 THA_SteeringTouchStat 0;
BA_ "GenSigTimeoutTime_ORC" SG_ 1056 THA_SteeringTouchStat 0;
BA_ "GenSigTimeoutTime_BSM" SG_ 276 DriveModeSts_EPT 0;
BA_ "GenSigTimeoutTime_BSM2" SG_ 276 DriveModeSts_EPT 0;
BA_ "GenSigTimeoutTime_CADM" SG_ 276 DriveModeSts_EPT 0;
BA_ "GenSigTimeoutTime_CVADAS" SG_ 276 DriveModeSts_EPT 0;
BA_ "GenSigTimeoutTime_ECM" SG_ 276 DriveModeSts_EPT 0;
BA_ "GenSigTimeoutTime_EPS" SG_ 276 DriveModeSts_EPT 0;
BA_ "GenSigTimeoutTime_EVCU2" SG_ 276 DriveModeSts_EPT 0;
BA_ "GenSigTimeoutTime_ORC" SG_ 276 DriveModeSts_EPT 0;
BA_ "GenSigStartValue" SG_ 1580 Motor1_RPM 32768;
BA_ "GenSigTimeoutTime_BSM" SG_ 1580 Motor1_RPM 0;
BA_ "GenSigTimeoutTime_BSM2" SG_ 1580 Motor1_RPM 0;
BA_ "GenSigTimeoutTime_CADM" SG_ 1580 Motor1_RPM 0;
BA_ "GenSigTimeoutTime_CVADAS" SG_ 1580 Motor1_RPM 0;
BA_ "GenSigTimeoutTime_ECM" SG_ 1580 Motor1_RPM 0;
BA_ "GenSigTimeoutTime_EPS" SG_ 1580 Motor1_RPM 0;
BA_ "GenSigTimeoutTime_EVCU2" SG_ 1580 Motor1_RPM 0;
BA_ "GenSigTimeoutTime_ORC" SG_ 1580 Motor1_RPM 0;
BA_ "GenSigStartValue" SG_ 1580 Motor2_RPM 32768;
BA_ "GenSigTimeoutTime_BSM" SG_ 1580 Motor2_RPM 0;
BA_ "GenSigTimeoutTime_BSM2" SG_ 1580 Motor2_RPM 0;
BA_ "GenSigTimeoutTime_CADM" SG_ 1580 Motor2_RPM 0;
BA_ "GenSigTimeoutTime_CVADAS" SG_ 1580 Motor2_RPM 0;
BA_ "GenSigTimeoutTime_ECM" SG_ 1580 Motor2_RPM 0;
BA_ "GenSigTimeoutTime_EPS" SG_ 1580 Motor2_RPM 0;
BA_ "GenSigTimeoutTime_EVCU2" SG_ 1580 Motor2_RPM 0;
BA_ "GenSigTimeoutTime_ORC" SG_ 1580 Motor2_RPM 0;
BA_ "GenSigTimeoutTime_BSM" SG_ 1626 IMPACT_B 0;
BA_ "GenSigTimeoutTime_BSM2" SG_ 1626 IMPACT_B 0;
BA_ "GenSigTimeoutTime_CADM" SG_ 1626 IMPACT_B 0;
BA_ "GenSigTimeoutTime_CVADAS" SG_ 1626 IMPACT_B 0;
BA_ "GenSigTimeoutTime_ECM" SG_ 1626 IMPACT_B 0;
BA_ "GenSigTimeoutTime_EPS" SG_ 1626 IMPACT_B 0;
BA_ "GenSigTimeoutTime_EVCU2" SG_ 1626 IMPACT_B 0;
BA_ "GenSigTimeoutTime_ORC" SG_ 1626 IMPACT_B 0;
BA_ "GenSigTimeoutTime_BSM" SG_ 1626 IMPACT_C 0;
BA_ "GenSigTimeoutTime_BSM2" SG_ 1626 IMPACT_C 0;
BA_ "GenSigTimeoutTime_CADM" SG_ 1626 IMPACT_C 0;
BA_ "GenSigTimeoutTime_CVADAS" SG_ 1626 IMPACT_C 0;
BA_ "GenSigTimeoutTime_ECM" SG_ 1626 IMPACT_C 0;
BA_ "GenSigTimeoutTime_EPS" SG_ 1626 IMPACT_C 0;
BA_ "GenSigTimeoutTime_EVCU2" SG_ 1626 IMPACT_C 0;
BA_ "GenSigTimeoutTime_ORC" SG_ 1626 IMPACT_C 0;
BA_ "GenSigTimeoutTime_BSM" SG_ 1626 IMPACT_F 0;
BA_ "GenSigTimeoutTime_BSM2" SG_ 1626 IMPACT_F 0;
BA_ "GenSigTimeoutTime_CADM" SG_ 1626 IMPACT_F 0;
BA_ "GenSigTimeoutTime_CVADAS" SG_ 1626 IMPACT_F 0;
BA_ "GenSigTimeoutTime_ECM" SG_ 1626 IMPACT_F 0;
BA_ "GenSigTimeoutTime_EPS" SG_ 1626 IMPACT_F 0;
BA_ "GenSigTimeoutTime_EVCU2" SG_ 1626 IMPACT_F 0;
BA_ "GenSigTimeoutTime_ORC" SG_ 1626 IMPACT_F 0;
BA_ "GenSigTimeoutTime_BSM" SG_ 1626 IMPACT_I 0;
BA_ "GenSigTimeoutTime_BSM2" SG_ 1626 IMPACT_I 0;
BA_ "GenSigTimeoutTime_CADM" SG_ 1626 IMPACT_I 0;
BA_ "GenSigTimeoutTime_CVADAS" SG_ 1626 IMPACT_I 0;
BA_ "GenSigTimeoutTime_ECM" SG_ 1626 IMPACT_I 0;
BA_ "GenSigTimeoutTime_EPS" SG_ 1626 IMPACT_I 0;
BA_ "GenSigTimeoutTime_EVCU2" SG_ 1626 IMPACT_I 0;
BA_ "GenSigTimeoutTime_ORC" SG_ 1626 IMPACT_I 0;
BA_ "GenSigTimeoutTime_BSM" SG_ 1626 IMPACT_K 0;
BA_ "GenSigTimeoutTime_BSM2" SG_ 1626 IMPACT_K 0;
BA_ "GenSigTimeoutTime_CADM" SG_ 1626 IMPACT_K 0;
BA_ "GenSigTimeoutTime_CVADAS" SG_ 1626 IMPACT_K 0;
BA_ "GenSigTimeoutTime_ECM" SG_ 1626 IMPACT_K 0;
BA_ "GenSigTimeoutTime_EPS" SG_ 1626 IMPACT_K 0;
BA_ "GenSigTimeoutTime_EVCU2" SG_ 1626 IMPACT_K 0;
BA_ "GenSigTimeoutTime_ORC" SG_ 1626 IMPACT_K 0;
BA_ "GenSigTimeoutTime_BSM" SG_ 1626 IMPACT_M 0;
BA_ "GenSigTimeoutTime_BSM2" SG_ 1626 IMPACT_M 0;
BA_ "GenSigTimeoutTime_CADM" SG_ 1626 IMPACT_M 0;
BA_ "GenSigTimeoutTime_CVADAS" SG_ 1626 IMPACT_M 0;
BA_ "GenSigTimeoutTime_ECM" SG_ 1626 IMPACT_M 0;
BA_ "GenSigTimeoutTime_EPS" SG_ 1626 IMPACT_M 0;
BA_ "GenSigTimeoutTime_EVCU2" SG_ 1626 IMPACT_M 0;
BA_ "GenSigTimeoutTime_ORC" SG_ 1626 IMPACT_M 0;
BA_ "GenSigSendType" SG_ 1626 IMPACTCommand 5;
BA_ "GenSigTimeoutTime_BSM" SG_ 1626 IMPACTCommand 0;
BA_ "GenSigTimeoutTime_BSM2" SG_ 1626 IMPACTCommand 0;
BA_ "GenSigTimeoutTime_CVADAS" SG_ 1626 IMPACTCommand 0;
BA_ "GenSigTimeoutTime_ECM" SG_ 1626 IMPACTCommand 0;
BA_ "GenSigTimeoutTime_EPS" SG_ 1626 IMPACTCommand 0;
BA_ "GenSigTimeoutTime_ORC" SG_ 1626 IMPACTCommand 0;
BA_ "GenSigStartValue" SG_ 1626 IMPACTConfirm 1;
BA_ "GenSigInactiveValue" SG_ 1626 IMPACTConfirm 1;
BA_ "GenSigSendType" SG_ 1626 IMPACTConfirm 5;
BA_ "GenSigTimeoutTime_BSM" SG_ 1626 IMPACTConfirm 0;
BA_ "GenSigTimeoutTime_BSM2" SG_ 1626 IMPACTConfirm 0;
BA_ "GenSigTimeoutTime_CVADAS" SG_ 1626 IMPACTConfirm 0;
BA_ "GenSigTimeoutTime_ECM" SG_ 1626 IMPACTConfirm 0;
BA_ "GenSigTimeoutTime_EPS" SG_ 1626 IMPACTConfirm 0;
BA_ "GenSigTimeoutTime_ORC" SG_ 1626 IMPACTConfirm 0;
BA_ "GenSigSendType" SG_ 1626 IMPACTFailSts 5;
BA_ "GenSigTimeoutTime_BSM" SG_ 1626 IMPACTFailSts 0;
BA_ "GenSigTimeoutTime_BSM2" SG_ 1626 IMPACTFailSts 0;
BA_ "GenSigTimeoutTime_CADM" SG_ 1626 IMPACTFailSts 0;
BA_ "GenSigTimeoutTime_CVADAS" SG_ 1626 IMPACTFailSts 0;
BA_ "GenSigTimeoutTime_ECM" SG_ 1626 IMPACTFailSts 0;
BA_ "GenSigTimeoutTime_EPS" SG_ 1626 IMPACTFailSts 0;
BA_ "GenSigTimeoutTime_EVCU2" SG_ 1626 IMPACTFailSts 0;
BA_ "GenSigTimeoutTime_ORC" SG_ 1626 IMPACTFailSts 0;
BA_ "GenSigTimeoutTime_BSM" SG_ 1626 IMPACTThreshold 0;
BA_ "GenSigTimeoutTime_BSM2" SG_ 1626 IMPACTThreshold 0;
BA_ "GenSigTimeoutTime_CADM" SG_ 1626 IMPACTThreshold 0;
BA_ "GenSigTimeoutTime_CVADAS" SG_ 1626 IMPACTThreshold 0;
BA_ "GenSigTimeoutTime_ECM" SG_ 1626 IMPACTThreshold 0;
BA_ "GenSigTimeoutTime_EPS" SG_ 1626 IMPACTThreshold 0;
BA_ "GenSigTimeoutTime_EVCU2" SG_ 1626 IMPACTThreshold 0;
BA_ "GenSigTimeoutTime_ORC" SG_ 1626 IMPACTThreshold 0;
BA_ "GenSigTimeoutTime_BSM" SG_ 2654486534 CBV_bit0_RepeatMessageRequestBit 0;
BA_ "GenSigTimeoutTime_BSM2" SG_ 2654486534 CBV_bit0_RepeatMessageRequestBit 0;
BA_ "GenSigTimeoutTime_CADM" SG_ 2654486534 CBV_bit0_RepeatMessageRequestBit 0;
BA_ "GenSigTimeoutTime_CVADAS" SG_ 2654486534 CBV_bit0_RepeatMessageRequestBit 0;
BA_ "GenSigTimeoutTime_ECM" SG_ 2654486534 CBV_bit0_RepeatMessageRequestBit 0;
BA_ "GenSigTimeoutTime_EPS" SG_ 2654486534 CBV_bit0_RepeatMessageRequestBit 0;
BA_ "GenSigTimeoutTime_EVCU2" SG_ 2654486534 CBV_bit0_RepeatMessageRequestBit 0;
BA_ "GenSigTimeoutTime_ORC" SG_ 2654486534 CBV_bit0_RepeatMessageRequestBit 0;
BA_ "GenSigTimeoutTime_BSM" SG_ 2654486534 CBV_bit1 0;
BA_ "GenSigTimeoutTime_BSM2" SG_ 2654486534 CBV_bit1 0;
BA_ "GenSigTimeoutTime_CADM" SG_ 2654486534 CBV_bit1 0;
BA_ "GenSigTimeoutTime_CVADAS" SG_ 2654486534 CBV_bit1 0;
BA_ "GenSigTimeoutTime_ECM" SG_ 2654486534 CBV_bit1 0;
BA_ "GenSigTimeoutTime_EPS" SG_ 2654486534 CBV_bit1 0;
BA_ "GenSigTimeoutTime_EVCU2" SG_ 2654486534 CBV_bit1 0;
BA_ "GenSigTimeoutTime_ORC" SG_ 2654486534 CBV_bit1 0;
BA_ "GenSigTimeoutTime_BSM" SG_ 2654486534 CBV_bit2 0;
BA_ "GenSigTimeoutTime_BSM2" SG_ 2654486534 CBV_bit2 0;
BA_ "GenSigTimeoutTime_CADM" SG_ 2654486534 CBV_bit2 0;
BA_ "GenSigTimeoutTime_CVADAS" SG_ 2654486534 CBV_bit2 0;
BA_ "GenSigTimeoutTime_ECM" SG_ 2654486534 CBV_bit2 0;
BA_ "GenSigTimeoutTime_EPS" SG_ 2654486534 CBV_bit2 0;
BA_ "GenSigTimeoutTime_EVCU2" SG_ 2654486534 CBV_bit2 0;
BA_ "GenSigTimeoutTime_ORC" SG_ 2654486534 CBV_bit2 0;
BA_ "GenSigTimeoutTime_BSM" SG_ 2654486534 CBV_bit3_NMCoordinatorBit 0;
BA_ "GenSigTimeoutTime_BSM2" SG_ 2654486534 CBV_bit3_NMCoordinatorBit 0;
BA_ "GenSigTimeoutTime_CADM" SG_ 2654486534 CBV_bit3_NMCoordinatorBit 0;
BA_ "GenSigTimeoutTime_CVADAS" SG_ 2654486534 CBV_bit3_NMCoordinatorBit 0;
BA_ "GenSigTimeoutTime_ECM" SG_ 2654486534 CBV_bit3_NMCoordinatorBit 0;
BA_ "GenSigTimeoutTime_EPS" SG_ 2654486534 CBV_bit3_NMCoordinatorBit 0;
BA_ "GenSigTimeoutTime_EVCU2" SG_ 2654486534 CBV_bit3_NMCoordinatorBit 0;
BA_ "GenSigTimeoutTime_ORC" SG_ 2654486534 CBV_bit3_NMCoordinatorBit 0;
BA_ "GenSigTimeoutTime_BSM" SG_ 2654486534 CBV_bit4_ActiveWakeupBit 0;
BA_ "GenSigTimeoutTime_BSM2" SG_ 2654486534 CBV_bit4_ActiveWakeupBit 0;
BA_ "GenSigTimeoutTime_CADM" SG_ 2654486534 CBV_bit4_ActiveWakeupBit 0;
BA_ "GenSigTimeoutTime_CVADAS" SG_ 2654486534 CBV_bit4_ActiveWakeupBit 0;
BA_ "GenSigTimeoutTime_ECM" SG_ 2654486534 CBV_bit4_ActiveWakeupBit 0;
BA_ "GenSigTimeoutTime_EPS" SG_ 2654486534 CBV_bit4_ActiveWakeupBit 0;
BA_ "GenSigTimeoutTime_EVCU2" SG_ 2654486534 CBV_bit4_ActiveWakeupBit 0;
BA_ "GenSigTimeoutTime_ORC" SG_ 2654486534 CBV_bit4_ActiveWakeupBit 0;
BA_ "GenSigTimeoutTime_BSM" SG_ 2654486534 CBV_bit5 0;
BA_ "GenSigTimeoutTime_BSM2" SG_ 2654486534 CBV_bit5 0;
BA_ "GenSigTimeoutTime_CADM" SG_ 2654486534 CBV_bit5 0;
BA_ "GenSigTimeoutTime_CVADAS" SG_ 2654486534 CBV_bit5 0;
BA_ "GenSigTimeoutTime_ECM" SG_ 2654486534 CBV_bit5 0;
BA_ "GenSigTimeoutTime_EPS" SG_ 2654486534 CBV_bit5 0;
BA_ "GenSigTimeoutTime_EVCU2" SG_ 2654486534 CBV_bit5 0;
BA_ "GenSigTimeoutTime_ORC" SG_ 2654486534 CBV_bit5 0;
BA_ "GenSigTimeoutTime_BSM" SG_ 2654486534 CBV_bit6_PartialNtwInfBit 0;
BA_ "GenSigTimeoutTime_BSM2" SG_ 2654486534 CBV_bit6_PartialNtwInfBit 0;
BA_ "GenSigTimeoutTime_CADM" SG_ 2654486534 CBV_bit6_PartialNtwInfBit 0;
BA_ "GenSigTimeoutTime_CVADAS" SG_ 2654486534 CBV_bit6_PartialNtwInfBit 0;
BA_ "GenSigTimeoutTime_ECM" SG_ 2654486534 CBV_bit6_PartialNtwInfBit 0;
BA_ "GenSigTimeoutTime_EPS" SG_ 2654486534 CBV_bit6_PartialNtwInfBit 0;
BA_ "GenSigTimeoutTime_EVCU2" SG_ 2654486534 CBV_bit6_PartialNtwInfBit 0;
BA_ "GenSigTimeoutTime_ORC" SG_ 2654486534 CBV_bit6_PartialNtwInfBit 0;
BA_ "GenSigTimeoutTime_BSM" SG_ 2654486534 CBV_bit7 0;
BA_ "GenSigTimeoutTime_BSM2" SG_ 2654486534 CBV_bit7 0;
BA_ "GenSigTimeoutTime_CADM" SG_ 2654486534 CBV_bit7 0;
BA_ "GenSigTimeoutTime_CVADAS" SG_ 2654486534 CBV_bit7 0;
BA_ "GenSigTimeoutTime_ECM" SG_ 2654486534 CBV_bit7 0;
BA_ "GenSigTimeoutTime_EPS" SG_ 2654486534 CBV_bit7 0;
BA_ "GenSigTimeoutTime_EVCU2" SG_ 2654486534 CBV_bit7 0;
BA_ "GenSigTimeoutTime_ORC" SG_ 2654486534 CBV_bit7 0;
BA_ "GenSigTimeoutTime_BSM" SG_ 2654486534 SourceNodeIdentifier 0;
BA_ "GenSigTimeoutTime_BSM2" SG_ 2654486534 SourceNodeIdentifier 0;
BA_ "GenSigTimeoutTime_CADM" SG_ 2654486534 SourceNodeIdentifier 0;
BA_ "GenSigTimeoutTime_CVADAS" SG_ 2654486534 SourceNodeIdentifier 0;
BA_ "GenSigTimeoutTime_ECM" SG_ 2654486534 SourceNodeIdentifier 0;
BA_ "GenSigTimeoutTime_EPS" SG_ 2654486534 SourceNodeIdentifier 0;
BA_ "GenSigTimeoutTime_EVCU2" SG_ 2654486534 SourceNodeIdentifier 0;
BA_ "GenSigTimeoutTime_ORC" SG_ 2654486534 SourceNodeIdentifier 0;
BA_ "GenSigTimeoutTime_BSM" SG_ 2654486676 CBV_bit0_RepeatMessageRequestBit 0;
BA_ "GenSigTimeoutTime_BSM2" SG_ 2654486676 CBV_bit0_RepeatMessageRequestBit 0;
BA_ "GenSigTimeoutTime_CADM" SG_ 2654486676 CBV_bit0_RepeatMessageRequestBit 0;
BA_ "GenSigTimeoutTime_CVADAS" SG_ 2654486676 CBV_bit0_RepeatMessageRequestBit 0;
BA_ "GenSigTimeoutTime_ECM" SG_ 2654486676 CBV_bit0_RepeatMessageRequestBit 0;
BA_ "GenSigTimeoutTime_EPS" SG_ 2654486676 CBV_bit0_RepeatMessageRequestBit 0;
BA_ "GenSigTimeoutTime_EVCU2" SG_ 2654486676 CBV_bit0_RepeatMessageRequestBit 0;
BA_ "GenSigTimeoutTime_ORC" SG_ 2654486676 CBV_bit0_RepeatMessageRequestBit 0;
BA_ "GenSigTimeoutTime_BSM" SG_ 2654486676 CBV_bit1 0;
BA_ "GenSigTimeoutTime_BSM2" SG_ 2654486676 CBV_bit1 0;
BA_ "GenSigTimeoutTime_CADM" SG_ 2654486676 CBV_bit1 0;
BA_ "GenSigTimeoutTime_CVADAS" SG_ 2654486676 CBV_bit1 0;
BA_ "GenSigTimeoutTime_ECM" SG_ 2654486676 CBV_bit1 0;
BA_ "GenSigTimeoutTime_EPS" SG_ 2654486676 CBV_bit1 0;
BA_ "GenSigTimeoutTime_EVCU2" SG_ 2654486676 CBV_bit1 0;
BA_ "GenSigTimeoutTime_ORC" SG_ 2654486676 CBV_bit1 0;
BA_ "GenSigTimeoutTime_BSM" SG_ 2654486676 CBV_bit2 0;
BA_ "GenSigTimeoutTime_BSM2" SG_ 2654486676 CBV_bit2 0;
BA_ "GenSigTimeoutTime_CADM" SG_ 2654486676 CBV_bit2 0;
BA_ "GenSigTimeoutTime_CVADAS" SG_ 2654486676 CBV_bit2 0;
BA_ "GenSigTimeoutTime_ECM" SG_ 2654486676 CBV_bit2 0;
BA_ "GenSigTimeoutTime_EPS" SG_ 2654486676 CBV_bit2 0;
BA_ "GenSigTimeoutTime_EVCU2" SG_ 2654486676 CBV_bit2 0;
BA_ "GenSigTimeoutTime_ORC" SG_ 2654486676 CBV_bit2 0;
BA_ "GenSigTimeoutTime_BSM" SG_ 2654486676 CBV_bit3_NMCoordinatorBit 0;
BA_ "GenSigTimeoutTime_BSM2" SG_ 2654486676 CBV_bit3_NMCoordinatorBit 0;
BA_ "GenSigTimeoutTime_CADM" SG_ 2654486676 CBV_bit3_NMCoordinatorBit 0;
BA_ "GenSigTimeoutTime_CVADAS" SG_ 2654486676 CBV_bit3_NMCoordinatorBit 0;
BA_ "GenSigTimeoutTime_ECM" SG_ 2654486676 CBV_bit3_NMCoordinatorBit 0;
BA_ "GenSigTimeoutTime_EPS" SG_ 2654486676 CBV_bit3_NMCoordinatorBit 0;
BA_ "GenSigTimeoutTime_EVCU2" SG_ 2654486676 CBV_bit3_NMCoordinatorBit 0;
BA_ "GenSigTimeoutTime_ORC" SG_ 2654486676 CBV_bit3_NMCoordinatorBit 0;
BA_ "GenSigTimeoutTime_BSM" SG_ 2654486676 CBV_bit4_ActiveWakeupBit 0;
BA_ "GenSigTimeoutTime_BSM2" SG_ 2654486676 CBV_bit4_ActiveWakeupBit 0;
BA_ "GenSigTimeoutTime_CADM" SG_ 2654486676 CBV_bit4_ActiveWakeupBit 0;
BA_ "GenSigTimeoutTime_CVADAS" SG_ 2654486676 CBV_bit4_ActiveWakeupBit 0;
BA_ "GenSigTimeoutTime_ECM" SG_ 2654486676 CBV_bit4_ActiveWakeupBit 0;
BA_ "GenSigTimeoutTime_EPS" SG_ 2654486676 CBV_bit4_ActiveWakeupBit 0;
BA_ "GenSigTimeoutTime_EVCU2" SG_ 2654486676 CBV_bit4_ActiveWakeupBit 0;
BA_ "GenSigTimeoutTime_ORC" SG_ 2654486676 CBV_bit4_ActiveWakeupBit 0;
BA_ "GenSigTimeoutTime_BSM" SG_ 2654486676 CBV_bit5 0;
BA_ "GenSigTimeoutTime_BSM2" SG_ 2654486676 CBV_bit5 0;
BA_ "GenSigTimeoutTime_CADM" SG_ 2654486676 CBV_bit5 0;
BA_ "GenSigTimeoutTime_CVADAS" SG_ 2654486676 CBV_bit5 0;
BA_ "GenSigTimeoutTime_ECM" SG_ 2654486676 CBV_bit5 0;
BA_ "GenSigTimeoutTime_EPS" SG_ 2654486676 CBV_bit5 0;
BA_ "GenSigTimeoutTime_EVCU2" SG_ 2654486676 CBV_bit5 0;
BA_ "GenSigTimeoutTime_ORC" SG_ 2654486676 CBV_bit5 0;
BA_ "GenSigTimeoutTime_BSM" SG_ 2654486676 CBV_bit6_PartialNtwInfBit 0;
BA_ "GenSigTimeoutTime_BSM2" SG_ 2654486676 CBV_bit6_PartialNtwInfBit 0;
BA_ "GenSigTimeoutTime_CADM" SG_ 2654486676 CBV_bit6_PartialNtwInfBit 0;
BA_ "GenSigTimeoutTime_CVADAS" SG_ 2654486676 CBV_bit6_PartialNtwInfBit 0;
BA_ "GenSigTimeoutTime_ECM" SG_ 2654486676 CBV_bit6_PartialNtwInfBit 0;
BA_ "GenSigTimeoutTime_EPS" SG_ 2654486676 CBV_bit6_PartialNtwInfBit 0;
BA_ "GenSigTimeoutTime_EVCU2" SG_ 2654486676 CBV_bit6_PartialNtwInfBit 0;
BA_ "GenSigTimeoutTime_ORC" SG_ 2654486676 CBV_bit6_PartialNtwInfBit 0;
BA_ "GenSigTimeoutTime_BSM" SG_ 2654486676 CBV_bit7 0;
BA_ "GenSigTimeoutTime_BSM2" SG_ 2654486676 CBV_bit7 0;
BA_ "GenSigTimeoutTime_CADM" SG_ 2654486676 CBV_bit7 0;
BA_ "GenSigTimeoutTime_CVADAS" SG_ 2654486676 CBV_bit7 0;
BA_ "GenSigTimeoutTime_ECM" SG_ 2654486676 CBV_bit7 0;
BA_ "GenSigTimeoutTime_EPS" SG_ 2654486676 CBV_bit7 0;
BA_ "GenSigTimeoutTime_EVCU2" SG_ 2654486676 CBV_bit7 0;
BA_ "GenSigTimeoutTime_ORC" SG_ 2654486676 CBV_bit7 0;
BA_ "GenSigTimeoutTime_BSM" SG_ 2654486676 SourceNodeIdentifier 0;
BA_ "GenSigTimeoutTime_BSM2" SG_ 2654486676 SourceNodeIdentifier 0;
BA_ "GenSigTimeoutTime_CADM" SG_ 2654486676 SourceNodeIdentifier 0;
BA_ "GenSigTimeoutTime_CVADAS" SG_ 2654486676 SourceNodeIdentifier 0;
BA_ "GenSigTimeoutTime_ECM" SG_ 2654486676 SourceNodeIdentifier 0;
BA_ "GenSigTimeoutTime_EPS" SG_ 2654486676 SourceNodeIdentifier 0;
BA_ "GenSigTimeoutTime_EVCU2" SG_ 2654486676 SourceNodeIdentifier 0;
BA_ "GenSigTimeoutTime_ORC" SG_ 2654486676 SourceNodeIdentifier 0;
BA_ "GenSigTimeoutTime_BSM" SG_ 2654486669 CBV_bit0_RepeatMessageRequestBit 0;
BA_ "GenSigTimeoutTime_BSM2" SG_ 2654486669 CBV_bit0_RepeatMessageRequestBit 0;
BA_ "GenSigTimeoutTime_CADM" SG_ 2654486669 CBV_bit0_RepeatMessageRequestBit 0;
BA_ "GenSigTimeoutTime_CVADAS" SG_ 2654486669 CBV_bit0_RepeatMessageRequestBit 0;
BA_ "GenSigTimeoutTime_ECM" SG_ 2654486669 CBV_bit0_RepeatMessageRequestBit 0;
BA_ "GenSigTimeoutTime_EPS" SG_ 2654486669 CBV_bit0_RepeatMessageRequestBit 0;
BA_ "GenSigTimeoutTime_EVCU2" SG_ 2654486669 CBV_bit0_RepeatMessageRequestBit 0;
BA_ "GenSigTimeoutTime_ORC" SG_ 2654486669 CBV_bit0_RepeatMessageRequestBit 0;
BA_ "GenSigTimeoutTime_BSM" SG_ 2654486669 CBV_bit1 0;
BA_ "GenSigTimeoutTime_BSM2" SG_ 2654486669 CBV_bit1 0;
BA_ "GenSigTimeoutTime_CADM" SG_ 2654486669 CBV_bit1 0;
BA_ "GenSigTimeoutTime_CVADAS" SG_ 2654486669 CBV_bit1 0;
BA_ "GenSigTimeoutTime_ECM" SG_ 2654486669 CBV_bit1 0;
BA_ "GenSigTimeoutTime_EPS" SG_ 2654486669 CBV_bit1 0;
BA_ "GenSigTimeoutTime_EVCU2" SG_ 2654486669 CBV_bit1 0;
BA_ "GenSigTimeoutTime_ORC" SG_ 2654486669 CBV_bit1 0;
BA_ "GenSigTimeoutTime_BSM" SG_ 2654486669 CBV_bit2 0;
BA_ "GenSigTimeoutTime_BSM2" SG_ 2654486669 CBV_bit2 0;
BA_ "GenSigTimeoutTime_CADM" SG_ 2654486669 CBV_bit2 0;
BA_ "GenSigTimeoutTime_CVADAS" SG_ 2654486669 CBV_bit2 0;
BA_ "GenSigTimeoutTime_ECM" SG_ 2654486669 CBV_bit2 0;
BA_ "GenSigTimeoutTime_EPS" SG_ 2654486669 CBV_bit2 0;
BA_ "GenSigTimeoutTime_EVCU2" SG_ 2654486669 CBV_bit2 0;
BA_ "GenSigTimeoutTime_ORC" SG_ 2654486669 CBV_bit2 0;
BA_ "GenSigTimeoutTime_BSM" SG_ 2654486669 CBV_bit3_NMCoordinatorBit 0;
BA_ "GenSigTimeoutTime_BSM2" SG_ 2654486669 CBV_bit3_NMCoordinatorBit 0;
BA_ "GenSigTimeoutTime_CADM" SG_ 2654486669 CBV_bit3_NMCoordinatorBit 0;
BA_ "GenSigTimeoutTime_CVADAS" SG_ 2654486669 CBV_bit3_NMCoordinatorBit 0;
BA_ "GenSigTimeoutTime_ECM" SG_ 2654486669 CBV_bit3_NMCoordinatorBit 0;
BA_ "GenSigTimeoutTime_EPS" SG_ 2654486669 CBV_bit3_NMCoordinatorBit 0;
BA_ "GenSigTimeoutTime_EVCU2" SG_ 2654486669 CBV_bit3_NMCoordinatorBit 0;
BA_ "GenSigTimeoutTime_ORC" SG_ 2654486669 CBV_bit3_NMCoordinatorBit 0;
BA_ "GenSigTimeoutTime_BSM" SG_ 2654486669 CBV_bit4_ActiveWakeupBit 0;
BA_ "GenSigTimeoutTime_BSM2" SG_ 2654486669 CBV_bit4_ActiveWakeupBit 0;
BA_ "GenSigTimeoutTime_CADM" SG_ 2654486669 CBV_bit4_ActiveWakeupBit 0;
BA_ "GenSigTimeoutTime_CVADAS" SG_ 2654486669 CBV_bit4_ActiveWakeupBit 0;
BA_ "GenSigTimeoutTime_ECM" SG_ 2654486669 CBV_bit4_ActiveWakeupBit 0;
BA_ "GenSigTimeoutTime_EPS" SG_ 2654486669 CBV_bit4_ActiveWakeupBit 0;
BA_ "GenSigTimeoutTime_EVCU2" SG_ 2654486669 CBV_bit4_ActiveWakeupBit 0;
BA_ "GenSigTimeoutTime_ORC" SG_ 2654486669 CBV_bit4_ActiveWakeupBit 0;
BA_ "GenSigTimeoutTime_BSM" SG_ 2654486669 CBV_bit5 0;
BA_ "GenSigTimeoutTime_BSM2" SG_ 2654486669 CBV_bit5 0;
BA_ "GenSigTimeoutTime_CADM" SG_ 2654486669 CBV_bit5 0;
BA_ "GenSigTimeoutTime_CVADAS" SG_ 2654486669 CBV_bit5 0;
BA_ "GenSigTimeoutTime_ECM" SG_ 2654486669 CBV_bit5 0;
BA_ "GenSigTimeoutTime_EPS" SG_ 2654486669 CBV_bit5 0;
BA_ "GenSigTimeoutTime_EVCU2" SG_ 2654486669 CBV_bit5 0;
BA_ "GenSigTimeoutTime_ORC" SG_ 2654486669 CBV_bit5 0;
BA_ "GenSigTimeoutTime_BSM" SG_ 2654486669 CBV_bit6_PartialNtwInfBit 0;
BA_ "GenSigTimeoutTime_BSM2" SG_ 2654486669 CBV_bit6_PartialNtwInfBit 0;
BA_ "GenSigTimeoutTime_CADM" SG_ 2654486669 CBV_bit6_PartialNtwInfBit 0;
BA_ "GenSigTimeoutTime_CVADAS" SG_ 2654486669 CBV_bit6_PartialNtwInfBit 0;
BA_ "GenSigTimeoutTime_ECM" SG_ 2654486669 CBV_bit6_PartialNtwInfBit 0;
BA_ "GenSigTimeoutTime_EPS" SG_ 2654486669 CBV_bit6_PartialNtwInfBit 0;
BA_ "GenSigTimeoutTime_EVCU2" SG_ 2654486669 CBV_bit6_PartialNtwInfBit 0;
BA_ "GenSigTimeoutTime_ORC" SG_ 2654486669 CBV_bit6_PartialNtwInfBit 0;
BA_ "GenSigTimeoutTime_BSM" SG_ 2654486669 CBV_bit7 0;
BA_ "GenSigTimeoutTime_BSM2" SG_ 2654486669 CBV_bit7 0;
BA_ "GenSigTimeoutTime_CADM" SG_ 2654486669 CBV_bit7 0;
BA_ "GenSigTimeoutTime_CVADAS" SG_ 2654486669 CBV_bit7 0;
BA_ "GenSigTimeoutTime_ECM" SG_ 2654486669 CBV_bit7 0;
BA_ "GenSigTimeoutTime_EPS" SG_ 2654486669 CBV_bit7 0;
BA_ "GenSigTimeoutTime_EVCU2" SG_ 2654486669 CBV_bit7 0;
BA_ "GenSigTimeoutTime_ORC" SG_ 2654486669 CBV_bit7 0;
BA_ "GenSigTimeoutTime_BSM" SG_ 2654486669 SourceNodeIdentifier 0;
BA_ "GenSigTimeoutTime_BSM2" SG_ 2654486669 SourceNodeIdentifier 0;
BA_ "GenSigTimeoutTime_CADM" SG_ 2654486669 SourceNodeIdentifier 0;
BA_ "GenSigTimeoutTime_CVADAS" SG_ 2654486669 SourceNodeIdentifier 0;
BA_ "GenSigTimeoutTime_ECM" SG_ 2654486669 SourceNodeIdentifier 0;
BA_ "GenSigTimeoutTime_EPS" SG_ 2654486669 SourceNodeIdentifier 0;
BA_ "GenSigTimeoutTime_EVCU2" SG_ 2654486669 SourceNodeIdentifier 0;
BA_ "GenSigTimeoutTime_ORC" SG_ 2654486669 SourceNodeIdentifier 0;
BA_ "GenSigTimeoutTime_BSM" SG_ 2654486529 CBV_bit0_RepeatMessageRequestBit 0;
BA_ "GenSigTimeoutTime_BSM2" SG_ 2654486529 CBV_bit0_RepeatMessageRequestBit 0;
BA_ "GenSigTimeoutTime_CADM" SG_ 2654486529 CBV_bit0_RepeatMessageRequestBit 0;
BA_ "GenSigTimeoutTime_CVADAS" SG_ 2654486529 CBV_bit0_RepeatMessageRequestBit 0;
BA_ "GenSigTimeoutTime_ECM" SG_ 2654486529 CBV_bit0_RepeatMessageRequestBit 0;
BA_ "GenSigTimeoutTime_EPS" SG_ 2654486529 CBV_bit0_RepeatMessageRequestBit 0;
BA_ "GenSigTimeoutTime_EVCU2" SG_ 2654486529 CBV_bit0_RepeatMessageRequestBit 0;
BA_ "GenSigTimeoutTime_ORC" SG_ 2654486529 CBV_bit0_RepeatMessageRequestBit 0;
BA_ "GenSigTimeoutTime_BSM" SG_ 2654486529 CBV_bit1 0;
BA_ "GenSigTimeoutTime_BSM2" SG_ 2654486529 CBV_bit1 0;
BA_ "GenSigTimeoutTime_CADM" SG_ 2654486529 CBV_bit1 0;
BA_ "GenSigTimeoutTime_CVADAS" SG_ 2654486529 CBV_bit1 0;
BA_ "GenSigTimeoutTime_ECM" SG_ 2654486529 CBV_bit1 0;
BA_ "GenSigTimeoutTime_EPS" SG_ 2654486529 CBV_bit1 0;
BA_ "GenSigTimeoutTime_EVCU2" SG_ 2654486529 CBV_bit1 0;
BA_ "GenSigTimeoutTime_ORC" SG_ 2654486529 CBV_bit1 0;
BA_ "GenSigTimeoutTime_BSM" SG_ 2654486529 CBV_bit2 0;
BA_ "GenSigTimeoutTime_BSM2" SG_ 2654486529 CBV_bit2 0;
BA_ "GenSigTimeoutTime_CADM" SG_ 2654486529 CBV_bit2 0;
BA_ "GenSigTimeoutTime_CVADAS" SG_ 2654486529 CBV_bit2 0;
BA_ "GenSigTimeoutTime_ECM" SG_ 2654486529 CBV_bit2 0;
BA_ "GenSigTimeoutTime_EPS" SG_ 2654486529 CBV_bit2 0;
BA_ "GenSigTimeoutTime_EVCU2" SG_ 2654486529 CBV_bit2 0;
BA_ "GenSigTimeoutTime_ORC" SG_ 2654486529 CBV_bit2 0;
BA_ "GenSigTimeoutTime_BSM" SG_ 2654486529 CBV_bit3_NMCoordinatorBit 0;
BA_ "GenSigTimeoutTime_BSM2" SG_ 2654486529 CBV_bit3_NMCoordinatorBit 0;
BA_ "GenSigTimeoutTime_CADM" SG_ 2654486529 CBV_bit3_NMCoordinatorBit 0;
BA_ "GenSigTimeoutTime_CVADAS" SG_ 2654486529 CBV_bit3_NMCoordinatorBit 0;
BA_ "GenSigTimeoutTime_ECM" SG_ 2654486529 CBV_bit3_NMCoordinatorBit 0;
BA_ "GenSigTimeoutTime_EPS" SG_ 2654486529 CBV_bit3_NMCoordinatorBit 0;
BA_ "GenSigTimeoutTime_EVCU2" SG_ 2654486529 CBV_bit3_NMCoordinatorBit 0;
BA_ "GenSigTimeoutTime_ORC" SG_ 2654486529 CBV_bit3_NMCoordinatorBit 0;
BA_ "GenSigTimeoutTime_BSM" SG_ 2654486529 CBV_bit4_ActiveWakeupBit 0;
BA_ "GenSigTimeoutTime_BSM2" SG_ 2654486529 CBV_bit4_ActiveWakeupBit 0;
BA_ "GenSigTimeoutTime_CADM" SG_ 2654486529 CBV_bit4_ActiveWakeupBit 0;
BA_ "GenSigTimeoutTime_CVADAS" SG_ 2654486529 CBV_bit4_ActiveWakeupBit 0;
BA_ "GenSigTimeoutTime_ECM" SG_ 2654486529 CBV_bit4_ActiveWakeupBit 0;
BA_ "GenSigTimeoutTime_EPS" SG_ 2654486529 CBV_bit4_ActiveWakeupBit 0;
BA_ "GenSigTimeoutTime_EVCU2" SG_ 2654486529 CBV_bit4_ActiveWakeupBit 0;
BA_ "GenSigTimeoutTime_ORC" SG_ 2654486529 CBV_bit4_ActiveWakeupBit 0;
BA_ "GenSigTimeoutTime_BSM" SG_ 2654486529 CBV_bit5 0;
BA_ "GenSigTimeoutTime_BSM2" SG_ 2654486529 CBV_bit5 0;
BA_ "GenSigTimeoutTime_CADM" SG_ 2654486529 CBV_bit5 0;
BA_ "GenSigTimeoutTime_CVADAS" SG_ 2654486529 CBV_bit5 0;
BA_ "GenSigTimeoutTime_ECM" SG_ 2654486529 CBV_bit5 0;
BA_ "GenSigTimeoutTime_EPS" SG_ 2654486529 CBV_bit5 0;
BA_ "GenSigTimeoutTime_EVCU2" SG_ 2654486529 CBV_bit5 0;
BA_ "GenSigTimeoutTime_ORC" SG_ 2654486529 CBV_bit5 0;
BA_ "GenSigTimeoutTime_BSM" SG_ 2654486529 CBV_bit6_PartialNtwInfBit 0;
BA_ "GenSigTimeoutTime_BSM2" SG_ 2654486529 CBV_bit6_PartialNtwInfBit 0;
BA_ "GenSigTimeoutTime_CADM" SG_ 2654486529 CBV_bit6_PartialNtwInfBit 0;
BA_ "GenSigTimeoutTime_CVADAS" SG_ 2654486529 CBV_bit6_PartialNtwInfBit 0;
BA_ "GenSigTimeoutTime_ECM" SG_ 2654486529 CBV_bit6_PartialNtwInfBit 0;
BA_ "GenSigTimeoutTime_EPS" SG_ 2654486529 CBV_bit6_PartialNtwInfBit 0;
BA_ "GenSigTimeoutTime_EVCU2" SG_ 2654486529 CBV_bit6_PartialNtwInfBit 0;
BA_ "GenSigTimeoutTime_ORC" SG_ 2654486529 CBV_bit6_PartialNtwInfBit 0;
BA_ "GenSigTimeoutTime_BSM" SG_ 2654486529 CBV_bit7 0;
BA_ "GenSigTimeoutTime_BSM2" SG_ 2654486529 CBV_bit7 0;
BA_ "GenSigTimeoutTime_CADM" SG_ 2654486529 CBV_bit7 0;
BA_ "GenSigTimeoutTime_CVADAS" SG_ 2654486529 CBV_bit7 0;
BA_ "GenSigTimeoutTime_ECM" SG_ 2654486529 CBV_bit7 0;
BA_ "GenSigTimeoutTime_EPS" SG_ 2654486529 CBV_bit7 0;
BA_ "GenSigTimeoutTime_EVCU2" SG_ 2654486529 CBV_bit7 0;
BA_ "GenSigTimeoutTime_ORC" SG_ 2654486529 CBV_bit7 0;
BA_ "GenSigTimeoutTime_BSM" SG_ 2654486529 SourceNodeIdentifier 0;
BA_ "GenSigTimeoutTime_BSM2" SG_ 2654486529 SourceNodeIdentifier 0;
BA_ "GenSigTimeoutTime_CADM" SG_ 2654486529 SourceNodeIdentifier 0;
BA_ "GenSigTimeoutTime_CVADAS" SG_ 2654486529 SourceNodeIdentifier 0;
BA_ "GenSigTimeoutTime_ECM" SG_ 2654486529 SourceNodeIdentifier 0;
BA_ "GenSigTimeoutTime_EPS" SG_ 2654486529 SourceNodeIdentifier 0;
BA_ "GenSigTimeoutTime_EVCU2" SG_ 2654486529 SourceNodeIdentifier 0;
BA_ "GenSigTimeoutTime_ORC" SG_ 2654486529 SourceNodeIdentifier 0;
BA_ "GenSigTimeoutTime_BSM" SG_ 2654486530 CBV_bit0_RepeatMessageRequestBit 0;
BA_ "GenSigTimeoutTime_BSM2" SG_ 2654486530 CBV_bit0_RepeatMessageRequestBit 0;
BA_ "GenSigTimeoutTime_CADM" SG_ 2654486530 CBV_bit0_RepeatMessageRequestBit 0;
BA_ "GenSigTimeoutTime_CVADAS" SG_ 2654486530 CBV_bit0_RepeatMessageRequestBit 0;
BA_ "GenSigTimeoutTime_ECM" SG_ 2654486530 CBV_bit0_RepeatMessageRequestBit 0;
BA_ "GenSigTimeoutTime_EPS" SG_ 2654486530 CBV_bit0_RepeatMessageRequestBit 0;
BA_ "GenSigTimeoutTime_EVCU2" SG_ 2654486530 CBV_bit0_RepeatMessageRequestBit 0;
BA_ "GenSigTimeoutTime_ORC" SG_ 2654486530 CBV_bit0_RepeatMessageRequestBit 0;
BA_ "GenSigTimeoutTime_BSM" SG_ 2654486530 CBV_bit1 0;
BA_ "GenSigTimeoutTime_BSM2" SG_ 2654486530 CBV_bit1 0;
BA_ "GenSigTimeoutTime_CADM" SG_ 2654486530 CBV_bit1 0;
BA_ "GenSigTimeoutTime_CVADAS" SG_ 2654486530 CBV_bit1 0;
BA_ "GenSigTimeoutTime_ECM" SG_ 2654486530 CBV_bit1 0;
BA_ "GenSigTimeoutTime_EPS" SG_ 2654486530 CBV_bit1 0;
BA_ "GenSigTimeoutTime_EVCU2" SG_ 2654486530 CBV_bit1 0;
BA_ "GenSigTimeoutTime_ORC" SG_ 2654486530 CBV_bit1 0;
BA_ "GenSigTimeoutTime_BSM" SG_ 2654486530 CBV_bit2 0;
BA_ "GenSigTimeoutTime_BSM2" SG_ 2654486530 CBV_bit2 0;
BA_ "GenSigTimeoutTime_CADM" SG_ 2654486530 CBV_bit2 0;
BA_ "GenSigTimeoutTime_CVADAS" SG_ 2654486530 CBV_bit2 0;
BA_ "GenSigTimeoutTime_ECM" SG_ 2654486530 CBV_bit2 0;
BA_ "GenSigTimeoutTime_EPS" SG_ 2654486530 CBV_bit2 0;
BA_ "GenSigTimeoutTime_EVCU2" SG_ 2654486530 CBV_bit2 0;
BA_ "GenSigTimeoutTime_ORC" SG_ 2654486530 CBV_bit2 0;
BA_ "GenSigTimeoutTime_BSM" SG_ 2654486530 CBV_bit3_NMCoordinatorBit 0;
BA_ "GenSigTimeoutTime_BSM2" SG_ 2654486530 CBV_bit3_NMCoordinatorBit 0;
BA_ "GenSigTimeoutTime_CADM" SG_ 2654486530 CBV_bit3_NMCoordinatorBit 0;
BA_ "GenSigTimeoutTime_CVADAS" SG_ 2654486530 CBV_bit3_NMCoordinatorBit 0;
BA_ "GenSigTimeoutTime_ECM" SG_ 2654486530 CBV_bit3_NMCoordinatorBit 0;
BA_ "GenSigTimeoutTime_EPS" SG_ 2654486530 CBV_bit3_NMCoordinatorBit 0;
BA_ "GenSigTimeoutTime_EVCU2" SG_ 2654486530 CBV_bit3_NMCoordinatorBit 0;
BA_ "GenSigTimeoutTime_ORC" SG_ 2654486530 CBV_bit3_NMCoordinatorBit 0;
BA_ "GenSigTimeoutTime_BSM" SG_ 2654486530 CBV_bit4_ActiveWakeupBit 0;
BA_ "GenSigTimeoutTime_BSM2" SG_ 2654486530 CBV_bit4_ActiveWakeupBit 0;
BA_ "GenSigTimeoutTime_CADM" SG_ 2654486530 CBV_bit4_ActiveWakeupBit 0;
BA_ "GenSigTimeoutTime_CVADAS" SG_ 2654486530 CBV_bit4_ActiveWakeupBit 0;
BA_ "GenSigTimeoutTime_ECM" SG_ 2654486530 CBV_bit4_ActiveWakeupBit 0;
BA_ "GenSigTimeoutTime_EPS" SG_ 2654486530 CBV_bit4_ActiveWakeupBit 0;
BA_ "GenSigTimeoutTime_EVCU2" SG_ 2654486530 CBV_bit4_ActiveWakeupBit 0;
BA_ "GenSigTimeoutTime_ORC" SG_ 2654486530 CBV_bit4_ActiveWakeupBit 0;
BA_ "GenSigTimeoutTime_BSM" SG_ 2654486530 CBV_bit5 0;
BA_ "GenSigTimeoutTime_BSM2" SG_ 2654486530 CBV_bit5 0;
BA_ "GenSigTimeoutTime_CADM" SG_ 2654486530 CBV_bit5 0;
BA_ "GenSigTimeoutTime_CVADAS" SG_ 2654486530 CBV_bit5 0;
BA_ "GenSigTimeoutTime_ECM" SG_ 2654486530 CBV_bit5 0;
BA_ "GenSigTimeoutTime_EPS" SG_ 2654486530 CBV_bit5 0;
BA_ "GenSigTimeoutTime_EVCU2" SG_ 2654486530 CBV_bit5 0;
BA_ "GenSigTimeoutTime_ORC" SG_ 2654486530 CBV_bit5 0;
BA_ "GenSigTimeoutTime_BSM" SG_ 2654486530 CBV_bit6_PartialNtwInfBit 0;
BA_ "GenSigTimeoutTime_BSM2" SG_ 2654486530 CBV_bit6_PartialNtwInfBit 0;
BA_ "GenSigTimeoutTime_CADM" SG_ 2654486530 CBV_bit6_PartialNtwInfBit 0;
BA_ "GenSigTimeoutTime_CVADAS" SG_ 2654486530 CBV_bit6_PartialNtwInfBit 0;
BA_ "GenSigTimeoutTime_ECM" SG_ 2654486530 CBV_bit6_PartialNtwInfBit 0;
BA_ "GenSigTimeoutTime_EPS" SG_ 2654486530 CBV_bit6_PartialNtwInfBit 0;
BA_ "GenSigTimeoutTime_EVCU2" SG_ 2654486530 CBV_bit6_PartialNtwInfBit 0;
BA_ "GenSigTimeoutTime_ORC" SG_ 2654486530 CBV_bit6_PartialNtwInfBit 0;
BA_ "GenSigTimeoutTime_BSM" SG_ 2654486530 CBV_bit7 0;
BA_ "GenSigTimeoutTime_BSM2" SG_ 2654486530 CBV_bit7 0;
BA_ "GenSigTimeoutTime_CADM" SG_ 2654486530 CBV_bit7 0;
BA_ "GenSigTimeoutTime_CVADAS" SG_ 2654486530 CBV_bit7 0;
BA_ "GenSigTimeoutTime_ECM" SG_ 2654486530 CBV_bit7 0;
BA_ "GenSigTimeoutTime_EPS" SG_ 2654486530 CBV_bit7 0;
BA_ "GenSigTimeoutTime_EVCU2" SG_ 2654486530 CBV_bit7 0;
BA_ "GenSigTimeoutTime_ORC" SG_ 2654486530 CBV_bit7 0;
BA_ "GenSigTimeoutTime_BSM" SG_ 2654486530 SourceNodeIdentifier 0;
BA_ "GenSigTimeoutTime_BSM2" SG_ 2654486530 SourceNodeIdentifier 0;
BA_ "GenSigTimeoutTime_CADM" SG_ 2654486530 SourceNodeIdentifier 0;
BA_ "GenSigTimeoutTime_CVADAS" SG_ 2654486530 SourceNodeIdentifier 0;
BA_ "GenSigTimeoutTime_ECM" SG_ 2654486530 SourceNodeIdentifier 0;
BA_ "GenSigTimeoutTime_EPS" SG_ 2654486530 SourceNodeIdentifier 0;
BA_ "GenSigTimeoutTime_EVCU2" SG_ 2654486530 SourceNodeIdentifier 0;
BA_ "GenSigTimeoutTime_ORC" SG_ 2654486530 SourceNodeIdentifier 0;
BA_ "GenSigTimeoutTime_BSM" SG_ 2654486592 CBV_bit0_RepeatMessageRequestBit 0;
BA_ "GenSigTimeoutTime_BSM2" SG_ 2654486592 CBV_bit0_RepeatMessageRequestBit 0;
BA_ "GenSigTimeoutTime_CADM" SG_ 2654486592 CBV_bit0_RepeatMessageRequestBit 0;
BA_ "GenSigTimeoutTime_CVADAS" SG_ 2654486592 CBV_bit0_RepeatMessageRequestBit 0;
BA_ "GenSigTimeoutTime_ECM" SG_ 2654486592 CBV_bit0_RepeatMessageRequestBit 0;
BA_ "GenSigTimeoutTime_EPS" SG_ 2654486592 CBV_bit0_RepeatMessageRequestBit 0;
BA_ "GenSigTimeoutTime_EVCU2" SG_ 2654486592 CBV_bit0_RepeatMessageRequestBit 0;
BA_ "GenSigTimeoutTime_ORC" SG_ 2654486592 CBV_bit0_RepeatMessageRequestBit 0;
BA_ "GenSigTimeoutTime_BSM" SG_ 2654486592 CBV_bit1 0;
BA_ "GenSigTimeoutTime_BSM2" SG_ 2654486592 CBV_bit1 0;
BA_ "GenSigTimeoutTime_CADM" SG_ 2654486592 CBV_bit1 0;
BA_ "GenSigTimeoutTime_CVADAS" SG_ 2654486592 CBV_bit1 0;
BA_ "GenSigTimeoutTime_ECM" SG_ 2654486592 CBV_bit1 0;
BA_ "GenSigTimeoutTime_EPS" SG_ 2654486592 CBV_bit1 0;
BA_ "GenSigTimeoutTime_EVCU2" SG_ 2654486592 CBV_bit1 0;
BA_ "GenSigTimeoutTime_ORC" SG_ 2654486592 CBV_bit1 0;
BA_ "GenSigTimeoutTime_BSM" SG_ 2654486592 CBV_bit2 0;
BA_ "GenSigTimeoutTime_BSM2" SG_ 2654486592 CBV_bit2 0;
BA_ "GenSigTimeoutTime_CADM" SG_ 2654486592 CBV_bit2 0;
BA_ "GenSigTimeoutTime_CVADAS" SG_ 2654486592 CBV_bit2 0;
BA_ "GenSigTimeoutTime_ECM" SG_ 2654486592 CBV_bit2 0;
BA_ "GenSigTimeoutTime_EPS" SG_ 2654486592 CBV_bit2 0;
BA_ "GenSigTimeoutTime_EVCU2" SG_ 2654486592 CBV_bit2 0;
BA_ "GenSigTimeoutTime_ORC" SG_ 2654486592 CBV_bit2 0;
BA_ "GenSigTimeoutTime_BSM" SG_ 2654486592 CBV_bit3_NMCoordinatorBit 0;
BA_ "GenSigTimeoutTime_BSM2" SG_ 2654486592 CBV_bit3_NMCoordinatorBit 0;
BA_ "GenSigTimeoutTime_CADM" SG_ 2654486592 CBV_bit3_NMCoordinatorBit 0;
BA_ "GenSigTimeoutTime_CVADAS" SG_ 2654486592 CBV_bit3_NMCoordinatorBit 0;
BA_ "GenSigTimeoutTime_ECM" SG_ 2654486592 CBV_bit3_NMCoordinatorBit 0;
BA_ "GenSigTimeoutTime_EPS" SG_ 2654486592 CBV_bit3_NMCoordinatorBit 0;
BA_ "GenSigTimeoutTime_EVCU2" SG_ 2654486592 CBV_bit3_NMCoordinatorBit 0;
BA_ "GenSigTimeoutTime_ORC" SG_ 2654486592 CBV_bit3_NMCoordinatorBit 0;
BA_ "GenSigTimeoutTime_BSM" SG_ 2654486592 CBV_bit4_ActiveWakeupBit 0;
BA_ "GenSigTimeoutTime_BSM2" SG_ 2654486592 CBV_bit4_ActiveWakeupBit 0;
BA_ "GenSigTimeoutTime_CADM" SG_ 2654486592 CBV_bit4_ActiveWakeupBit 0;
BA_ "GenSigTimeoutTime_CVADAS" SG_ 2654486592 CBV_bit4_ActiveWakeupBit 0;
BA_ "GenSigTimeoutTime_ECM" SG_ 2654486592 CBV_bit4_ActiveWakeupBit 0;
BA_ "GenSigTimeoutTime_EPS" SG_ 2654486592 CBV_bit4_ActiveWakeupBit 0;
BA_ "GenSigTimeoutTime_EVCU2" SG_ 2654486592 CBV_bit4_ActiveWakeupBit 0;
BA_ "GenSigTimeoutTime_ORC" SG_ 2654486592 CBV_bit4_ActiveWakeupBit 0;
BA_ "GenSigTimeoutTime_BSM" SG_ 2654486592 CBV_bit5 0;
BA_ "GenSigTimeoutTime_BSM2" SG_ 2654486592 CBV_bit5 0;
BA_ "GenSigTimeoutTime_CADM" SG_ 2654486592 CBV_bit5 0;
BA_ "GenSigTimeoutTime_CVADAS" SG_ 2654486592 CBV_bit5 0;
BA_ "GenSigTimeoutTime_ECM" SG_ 2654486592 CBV_bit5 0;
BA_ "GenSigTimeoutTime_EPS" SG_ 2654486592 CBV_bit5 0;
BA_ "GenSigTimeoutTime_EVCU2" SG_ 2654486592 CBV_bit5 0;
BA_ "GenSigTimeoutTime_ORC" SG_ 2654486592 CBV_bit5 0;
BA_ "GenSigTimeoutTime_BSM" SG_ 2654486592 CBV_bit6_PartialNtwInfBit 0;
BA_ "GenSigTimeoutTime_BSM2" SG_ 2654486592 CBV_bit6_PartialNtwInfBit 0;
BA_ "GenSigTimeoutTime_CADM" SG_ 2654486592 CBV_bit6_PartialNtwInfBit 0;
BA_ "GenSigTimeoutTime_CVADAS" SG_ 2654486592 CBV_bit6_PartialNtwInfBit 0;
BA_ "GenSigTimeoutTime_ECM" SG_ 2654486592 CBV_bit6_PartialNtwInfBit 0;
BA_ "GenSigTimeoutTime_EPS" SG_ 2654486592 CBV_bit6_PartialNtwInfBit 0;
BA_ "GenSigTimeoutTime_EVCU2" SG_ 2654486592 CBV_bit6_PartialNtwInfBit 0;
BA_ "GenSigTimeoutTime_ORC" SG_ 2654486592 CBV_bit6_PartialNtwInfBit 0;
BA_ "GenSigTimeoutTime_BSM" SG_ 2654486592 CBV_bit7 0;
BA_ "GenSigTimeoutTime_BSM2" SG_ 2654486592 CBV_bit7 0;
BA_ "GenSigTimeoutTime_CADM" SG_ 2654486592 CBV_bit7 0;
BA_ "GenSigTimeoutTime_CVADAS" SG_ 2654486592 CBV_bit7 0;
BA_ "GenSigTimeoutTime_ECM" SG_ 2654486592 CBV_bit7 0;
BA_ "GenSigTimeoutTime_EPS" SG_ 2654486592 CBV_bit7 0;
BA_ "GenSigTimeoutTime_EVCU2" SG_ 2654486592 CBV_bit7 0;
BA_ "GenSigTimeoutTime_ORC" SG_ 2654486592 CBV_bit7 0;
BA_ "GenSigTimeoutTime_BSM" SG_ 2654486592 SourceNodeIdentifier 0;
BA_ "GenSigTimeoutTime_BSM2" SG_ 2654486592 SourceNodeIdentifier 0;
BA_ "GenSigTimeoutTime_CADM" SG_ 2654486592 SourceNodeIdentifier 0;
BA_ "GenSigTimeoutTime_CVADAS" SG_ 2654486592 SourceNodeIdentifier 0;
BA_ "GenSigTimeoutTime_ECM" SG_ 2654486592 SourceNodeIdentifier 0;
BA_ "GenSigTimeoutTime_EPS" SG_ 2654486592 SourceNodeIdentifier 0;
BA_ "GenSigTimeoutTime_EVCU2" SG_ 2654486592 SourceNodeIdentifier 0;
BA_ "GenSigTimeoutTime_ORC" SG_ 2654486592 SourceNodeIdentifier 0;
BA_ "GenSigTimeoutTime_BSM" SG_ 2654486554 CBV_bit0_RepeatMessageRequestBit 0;
BA_ "GenSigTimeoutTime_BSM2" SG_ 2654486554 CBV_bit0_RepeatMessageRequestBit 0;
BA_ "GenSigTimeoutTime_CADM" SG_ 2654486554 CBV_bit0_RepeatMessageRequestBit 0;
BA_ "GenSigTimeoutTime_CVADAS" SG_ 2654486554 CBV_bit0_RepeatMessageRequestBit 0;
BA_ "GenSigTimeoutTime_ECM" SG_ 2654486554 CBV_bit0_RepeatMessageRequestBit 0;
BA_ "GenSigTimeoutTime_EPS" SG_ 2654486554 CBV_bit0_RepeatMessageRequestBit 0;
BA_ "GenSigTimeoutTime_EVCU2" SG_ 2654486554 CBV_bit0_RepeatMessageRequestBit 0;
BA_ "GenSigTimeoutTime_ORC" SG_ 2654486554 CBV_bit0_RepeatMessageRequestBit 0;
BA_ "GenSigTimeoutTime_BSM" SG_ 2654486554 CBV_bit1 0;
BA_ "GenSigTimeoutTime_BSM2" SG_ 2654486554 CBV_bit1 0;
BA_ "GenSigTimeoutTime_CADM" SG_ 2654486554 CBV_bit1 0;
BA_ "GenSigTimeoutTime_CVADAS" SG_ 2654486554 CBV_bit1 0;
BA_ "GenSigTimeoutTime_ECM" SG_ 2654486554 CBV_bit1 0;
BA_ "GenSigTimeoutTime_EPS" SG_ 2654486554 CBV_bit1 0;
BA_ "GenSigTimeoutTime_EVCU2" SG_ 2654486554 CBV_bit1 0;
BA_ "GenSigTimeoutTime_ORC" SG_ 2654486554 CBV_bit1 0;
BA_ "GenSigTimeoutTime_BSM" SG_ 2654486554 CBV_bit2 0;
BA_ "GenSigTimeoutTime_BSM2" SG_ 2654486554 CBV_bit2 0;
BA_ "GenSigTimeoutTime_CADM" SG_ 2654486554 CBV_bit2 0;
BA_ "GenSigTimeoutTime_CVADAS" SG_ 2654486554 CBV_bit2 0;
BA_ "GenSigTimeoutTime_ECM" SG_ 2654486554 CBV_bit2 0;
BA_ "GenSigTimeoutTime_EPS" SG_ 2654486554 CBV_bit2 0;
BA_ "GenSigTimeoutTime_EVCU2" SG_ 2654486554 CBV_bit2 0;
BA_ "GenSigTimeoutTime_ORC" SG_ 2654486554 CBV_bit2 0;
BA_ "GenSigTimeoutTime_BSM" SG_ 2654486554 CBV_bit3_NMCoordinatorBit 0;
BA_ "GenSigTimeoutTime_BSM2" SG_ 2654486554 CBV_bit3_NMCoordinatorBit 0;
BA_ "GenSigTimeoutTime_CADM" SG_ 2654486554 CBV_bit3_NMCoordinatorBit 0;
BA_ "GenSigTimeoutTime_CVADAS" SG_ 2654486554 CBV_bit3_NMCoordinatorBit 0;
BA_ "GenSigTimeoutTime_ECM" SG_ 2654486554 CBV_bit3_NMCoordinatorBit 0;
BA_ "GenSigTimeoutTime_EPS" SG_ 2654486554 CBV_bit3_NMCoordinatorBit 0;
BA_ "GenSigTimeoutTime_EVCU2" SG_ 2654486554 CBV_bit3_NMCoordinatorBit 0;
BA_ "GenSigTimeoutTime_ORC" SG_ 2654486554 CBV_bit3_NMCoordinatorBit 0;
BA_ "GenSigTimeoutTime_BSM" SG_ 2654486554 CBV_bit4_ActiveWakeupBit 0;
BA_ "GenSigTimeoutTime_BSM2" SG_ 2654486554 CBV_bit4_ActiveWakeupBit 0;
BA_ "GenSigTimeoutTime_CADM" SG_ 2654486554 CBV_bit4_ActiveWakeupBit 0;
BA_ "GenSigTimeoutTime_CVADAS" SG_ 2654486554 CBV_bit4_ActiveWakeupBit 0;
BA_ "GenSigTimeoutTime_ECM" SG_ 2654486554 CBV_bit4_ActiveWakeupBit 0;
BA_ "GenSigTimeoutTime_EPS" SG_ 2654486554 CBV_bit4_ActiveWakeupBit 0;
BA_ "GenSigTimeoutTime_EVCU2" SG_ 2654486554 CBV_bit4_ActiveWakeupBit 0;
BA_ "GenSigTimeoutTime_ORC" SG_ 2654486554 CBV_bit4_ActiveWakeupBit 0;
BA_ "GenSigTimeoutTime_BSM" SG_ 2654486554 CBV_bit5 0;
BA_ "GenSigTimeoutTime_BSM2" SG_ 2654486554 CBV_bit5 0;
BA_ "GenSigTimeoutTime_CADM" SG_ 2654486554 CBV_bit5 0;
BA_ "GenSigTimeoutTime_CVADAS" SG_ 2654486554 CBV_bit5 0;
BA_ "GenSigTimeoutTime_ECM" SG_ 2654486554 CBV_bit5 0;
BA_ "GenSigTimeoutTime_EPS" SG_ 2654486554 CBV_bit5 0;
BA_ "GenSigTimeoutTime_EVCU2" SG_ 2654486554 CBV_bit5 0;
BA_ "GenSigTimeoutTime_ORC" SG_ 2654486554 CBV_bit5 0;
BA_ "GenSigTimeoutTime_BSM" SG_ 2654486554 CBV_bit6_PartialNtwInfBit 0;
BA_ "GenSigTimeoutTime_BSM2" SG_ 2654486554 CBV_bit6_PartialNtwInfBit 0;
BA_ "GenSigTimeoutTime_CADM" SG_ 2654486554 CBV_bit6_PartialNtwInfBit 0;
BA_ "GenSigTimeoutTime_CVADAS" SG_ 2654486554 CBV_bit6_PartialNtwInfBit 0;
BA_ "GenSigTimeoutTime_ECM" SG_ 2654486554 CBV_bit6_PartialNtwInfBit 0;
BA_ "GenSigTimeoutTime_EPS" SG_ 2654486554 CBV_bit6_PartialNtwInfBit 0;
BA_ "GenSigTimeoutTime_EVCU2" SG_ 2654486554 CBV_bit6_PartialNtwInfBit 0;
BA_ "GenSigTimeoutTime_ORC" SG_ 2654486554 CBV_bit6_PartialNtwInfBit 0;
BA_ "GenSigTimeoutTime_BSM" SG_ 2654486554 CBV_bit7 0;
BA_ "GenSigTimeoutTime_BSM2" SG_ 2654486554 CBV_bit7 0;
BA_ "GenSigTimeoutTime_CADM" SG_ 2654486554 CBV_bit7 0;
BA_ "GenSigTimeoutTime_CVADAS" SG_ 2654486554 CBV_bit7 0;
BA_ "GenSigTimeoutTime_ECM" SG_ 2654486554 CBV_bit7 0;
BA_ "GenSigTimeoutTime_EPS" SG_ 2654486554 CBV_bit7 0;
BA_ "GenSigTimeoutTime_EVCU2" SG_ 2654486554 CBV_bit7 0;
BA_ "GenSigTimeoutTime_ORC" SG_ 2654486554 CBV_bit7 0;
BA_ "GenSigTimeoutTime_BSM" SG_ 2654486554 SourceNodeIdentifier 0;
BA_ "GenSigTimeoutTime_BSM2" SG_ 2654486554 SourceNodeIdentifier 0;
BA_ "GenSigTimeoutTime_CADM" SG_ 2654486554 SourceNodeIdentifier 0;
BA_ "GenSigTimeoutTime_CVADAS" SG_ 2654486554 SourceNodeIdentifier 0;
BA_ "GenSigTimeoutTime_ECM" SG_ 2654486554 SourceNodeIdentifier 0;
BA_ "GenSigTimeoutTime_EPS" SG_ 2654486554 SourceNodeIdentifier 0;
BA_ "GenSigTimeoutTime_EVCU2" SG_ 2654486554 SourceNodeIdentifier 0;
BA_ "GenSigTimeoutTime_ORC" SG_ 2654486554 SourceNodeIdentifier 0;
BA_ "GenSigTimeoutTime_BSM" SG_ 2654486552 CBV_bit0_RepeatMessageRequestBit 0;
BA_ "GenSigTimeoutTime_BSM2" SG_ 2654486552 CBV_bit0_RepeatMessageRequestBit 0;
BA_ "GenSigTimeoutTime_CADM" SG_ 2654486552 CBV_bit0_RepeatMessageRequestBit 0;
BA_ "GenSigTimeoutTime_CVADAS" SG_ 2654486552 CBV_bit0_RepeatMessageRequestBit 0;
BA_ "GenSigTimeoutTime_ECM" SG_ 2654486552 CBV_bit0_RepeatMessageRequestBit 0;
BA_ "GenSigTimeoutTime_EPS" SG_ 2654486552 CBV_bit0_RepeatMessageRequestBit 0;
BA_ "GenSigTimeoutTime_EVCU2" SG_ 2654486552 CBV_bit0_RepeatMessageRequestBit 0;
BA_ "GenSigTimeoutTime_ORC" SG_ 2654486552 CBV_bit0_RepeatMessageRequestBit 0;
BA_ "GenSigTimeoutTime_BSM" SG_ 2654486552 CBV_bit1 0;
BA_ "GenSigTimeoutTime_BSM2" SG_ 2654486552 CBV_bit1 0;
BA_ "GenSigTimeoutTime_CADM" SG_ 2654486552 CBV_bit1 0;
BA_ "GenSigTimeoutTime_CVADAS" SG_ 2654486552 CBV_bit1 0;
BA_ "GenSigTimeoutTime_ECM" SG_ 2654486552 CBV_bit1 0;
BA_ "GenSigTimeoutTime_EPS" SG_ 2654486552 CBV_bit1 0;
BA_ "GenSigTimeoutTime_EVCU2" SG_ 2654486552 CBV_bit1 0;
BA_ "GenSigTimeoutTime_ORC" SG_ 2654486552 CBV_bit1 0;
BA_ "GenSigTimeoutTime_BSM" SG_ 2654486552 CBV_bit2 0;
BA_ "GenSigTimeoutTime_BSM2" SG_ 2654486552 CBV_bit2 0;
BA_ "GenSigTimeoutTime_CADM" SG_ 2654486552 CBV_bit2 0;
BA_ "GenSigTimeoutTime_CVADAS" SG_ 2654486552 CBV_bit2 0;
BA_ "GenSigTimeoutTime_ECM" SG_ 2654486552 CBV_bit2 0;
BA_ "GenSigTimeoutTime_EPS" SG_ 2654486552 CBV_bit2 0;
BA_ "GenSigTimeoutTime_EVCU2" SG_ 2654486552 CBV_bit2 0;
BA_ "GenSigTimeoutTime_ORC" SG_ 2654486552 CBV_bit2 0;
BA_ "GenSigTimeoutTime_BSM" SG_ 2654486552 CBV_bit3_NMCoordinatorBit 0;
BA_ "GenSigTimeoutTime_BSM2" SG_ 2654486552 CBV_bit3_NMCoordinatorBit 0;
BA_ "GenSigTimeoutTime_CADM" SG_ 2654486552 CBV_bit3_NMCoordinatorBit 0;
BA_ "GenSigTimeoutTime_CVADAS" SG_ 2654486552 CBV_bit3_NMCoordinatorBit 0;
BA_ "GenSigTimeoutTime_ECM" SG_ 2654486552 CBV_bit3_NMCoordinatorBit 0;
BA_ "GenSigTimeoutTime_EPS" SG_ 2654486552 CBV_bit3_NMCoordinatorBit 0;
BA_ "GenSigTimeoutTime_EVCU2" SG_ 2654486552 CBV_bit3_NMCoordinatorBit 0;
BA_ "GenSigTimeoutTime_ORC" SG_ 2654486552 CBV_bit3_NMCoordinatorBit 0;
BA_ "GenSigTimeoutTime_BSM" SG_ 2654486552 CBV_bit4_ActiveWakeupBit 0;
BA_ "GenSigTimeoutTime_BSM2" SG_ 2654486552 CBV_bit4_ActiveWakeupBit 0;
BA_ "GenSigTimeoutTime_CADM" SG_ 2654486552 CBV_bit4_ActiveWakeupBit 0;
BA_ "GenSigTimeoutTime_CVADAS" SG_ 2654486552 CBV_bit4_ActiveWakeupBit 0;
BA_ "GenSigTimeoutTime_ECM" SG_ 2654486552 CBV_bit4_ActiveWakeupBit 0;
BA_ "GenSigTimeoutTime_EPS" SG_ 2654486552 CBV_bit4_ActiveWakeupBit 0;
BA_ "GenSigTimeoutTime_EVCU2" SG_ 2654486552 CBV_bit4_ActiveWakeupBit 0;
BA_ "GenSigTimeoutTime_ORC" SG_ 2654486552 CBV_bit4_ActiveWakeupBit 0;
BA_ "GenSigTimeoutTime_BSM" SG_ 2654486552 CBV_bit5 0;
BA_ "GenSigTimeoutTime_BSM2" SG_ 2654486552 CBV_bit5 0;
BA_ "GenSigTimeoutTime_CADM" SG_ 2654486552 CBV_bit5 0;
BA_ "GenSigTimeoutTime_CVADAS" SG_ 2654486552 CBV_bit5 0;
BA_ "GenSigTimeoutTime_ECM" SG_ 2654486552 CBV_bit5 0;
BA_ "GenSigTimeoutTime_EPS" SG_ 2654486552 CBV_bit5 0;
BA_ "GenSigTimeoutTime_EVCU2" SG_ 2654486552 CBV_bit5 0;
BA_ "GenSigTimeoutTime_ORC" SG_ 2654486552 CBV_bit5 0;
BA_ "GenSigTimeoutTime_BSM" SG_ 2654486552 CBV_bit6_PartialNtwInfBit 0;
BA_ "GenSigTimeoutTime_BSM2" SG_ 2654486552 CBV_bit6_PartialNtwInfBit 0;
BA_ "GenSigTimeoutTime_CADM" SG_ 2654486552 CBV_bit6_PartialNtwInfBit 0;
BA_ "GenSigTimeoutTime_CVADAS" SG_ 2654486552 CBV_bit6_PartialNtwInfBit 0;
BA_ "GenSigTimeoutTime_ECM" SG_ 2654486552 CBV_bit6_PartialNtwInfBit 0;
BA_ "GenSigTimeoutTime_EPS" SG_ 2654486552 CBV_bit6_PartialNtwInfBit 0;
BA_ "GenSigTimeoutTime_EVCU2" SG_ 2654486552 CBV_bit6_PartialNtwInfBit 0;
BA_ "GenSigTimeoutTime_ORC" SG_ 2654486552 CBV_bit6_PartialNtwInfBit 0;
BA_ "GenSigTimeoutTime_BSM" SG_ 2654486552 CBV_bit7 0;
BA_ "GenSigTimeoutTime_BSM2" SG_ 2654486552 CBV_bit7 0;
BA_ "GenSigTimeoutTime_CADM" SG_ 2654486552 CBV_bit7 0;
BA_ "GenSigTimeoutTime_CVADAS" SG_ 2654486552 CBV_bit7 0;
BA_ "GenSigTimeoutTime_ECM" SG_ 2654486552 CBV_bit7 0;
BA_ "GenSigTimeoutTime_EPS" SG_ 2654486552 CBV_bit7 0;
BA_ "GenSigTimeoutTime_EVCU2" SG_ 2654486552 CBV_bit7 0;
BA_ "GenSigTimeoutTime_ORC" SG_ 2654486552 CBV_bit7 0;
BA_ "GenSigTimeoutTime_BSM" SG_ 2654486552 SourceNodeIdentifier 0;
BA_ "GenSigTimeoutTime_BSM2" SG_ 2654486552 SourceNodeIdentifier 0;
BA_ "GenSigTimeoutTime_CADM" SG_ 2654486552 SourceNodeIdentifier 0;
BA_ "GenSigTimeoutTime_CVADAS" SG_ 2654486552 SourceNodeIdentifier 0;
BA_ "GenSigTimeoutTime_ECM" SG_ 2654486552 SourceNodeIdentifier 0;
BA_ "GenSigTimeoutTime_EPS" SG_ 2654486552 SourceNodeIdentifier 0;
BA_ "GenSigTimeoutTime_EVCU2" SG_ 2654486552 SourceNodeIdentifier 0;
BA_ "GenSigTimeoutTime_ORC" SG_ 2654486552 SourceNodeIdentifier 0;
BA_ "GenSigTimeoutTime_BSM2" SG_ 611 CRC_ORC1 0;
BA_ "GenSigTimeoutTime_CVADAS" SG_ 611 CRC_ORC1 0;
BA_ "GenSigTimeoutTime_ECM" SG_ 611 CRC_ORC1 0;
BA_ "GenSigTimeoutTime_EPS" SG_ 611 CRC_ORC1 0;
BA_ "GenSigTimeoutTime_EVCU2" SG_ 611 CRC_ORC1 0;
BA_ "GenSigTimeoutTime_ORC" SG_ 611 CRC_ORC1 0;
BA_ "GenSigTimeoutTime_BSM2" SG_ 611 MessageCounter_ORC1 0;
BA_ "GenSigTimeoutTime_CVADAS" SG_ 611 MessageCounter_ORC1 0;
BA_ "GenSigTimeoutTime_ECM" SG_ 611 MessageCounter_ORC1 0;
BA_ "GenSigTimeoutTime_EPS" SG_ 611 MessageCounter_ORC1 0;
BA_ "GenSigTimeoutTime_EVCU2" SG_ 611 MessageCounter_ORC1 0;
BA_ "GenSigTimeoutTime_ORC" SG_ 611 MessageCounter_ORC1 0;
BA_ "GenSigStartValue" SG_ 611 SBR1RowDriverSeatSts 3;
BA_ "GenSigSendType" SG_ 611 SBR1RowDriverSeatSts 3;
BA_ "GenSigTimeoutTime_BSM2" SG_ 611 SBR1RowDriverSeatSts 0;
BA_ "GenSigTimeoutTime_CVADAS" SG_ 611 SBR1RowDriverSeatSts 0;
BA_ "GenSigTimeoutTime_ECM" SG_ 611 SBR1RowDriverSeatSts 0;
BA_ "GenSigTimeoutTime_EPS" SG_ 611 SBR1RowDriverSeatSts 0;
BA_ "GenSigTimeoutTime_ORC" SG_ 611 SBR1RowDriverSeatSts 0;
BA_ "GenSigTimeoutTime_BSM2" SG_ 1954 CRC_ORC2 0;
BA_ "GenSigTimeoutTime_CADM" SG_ 1954 CRC_ORC2 0;
BA_ "GenSigTimeoutTime_CVADAS" SG_ 1954 CRC_ORC2 0;
BA_ "GenSigTimeoutTime_ECM" SG_ 1954 CRC_ORC2 0;
BA_ "GenSigTimeoutTime_EPS" SG_ 1954 CRC_ORC2 0;
BA_ "GenSigTimeoutTime_EVCU2" SG_ 1954 CRC_ORC2 0;
BA_ "GenSigTimeoutTime_ORC" SG_ 1954 CRC_ORC2 0;
BA_ "GenSigTimeoutTime_BSM2" SG_ 1954 MessageCounter_ORC2 0;
BA_ "GenSigTimeoutTime_CADM" SG_ 1954 MessageCounter_ORC2 0;
BA_ "GenSigTimeoutTime_CVADAS" SG_ 1954 MessageCounter_ORC2 0;
BA_ "GenSigTimeoutTime_ECM" SG_ 1954 MessageCounter_ORC2 0;
BA_ "GenSigTimeoutTime_EPS" SG_ 1954 MessageCounter_ORC2 0;
BA_ "GenSigTimeoutTime_EVCU2" SG_ 1954 MessageCounter_ORC2 0;
BA_ "GenSigTimeoutTime_ORC" SG_ 1954 MessageCounter_ORC2 0;
BA_ "GenSigTimeoutTime_BSM2" SG_ 1954 ORCIdentification 0;
BA_ "GenSigTimeoutTime_CADM" SG_ 1954 ORCIdentification 0;
BA_ "GenSigTimeoutTime_CVADAS" SG_ 1954 ORCIdentification 0;
BA_ "GenSigTimeoutTime_ECM" SG_ 1954 ORCIdentification 0;
BA_ "GenSigTimeoutTime_EPS" SG_ 1954 ORCIdentification 0;
BA_ "GenSigTimeoutTime_EVCU2" SG_ 1954 ORCIdentification 0;
BA_ "GenSigTimeoutTime_ORC" SG_ 1954 ORCIdentification 0;
BA_ "GenSigTimeoutTime_BSM2" SG_ 274 CRC_ORC3 0;
BA_ "GenSigTimeoutTime_CVADAS" SG_ 274 CRC_ORC3 0;
BA_ "GenSigTimeoutTime_ECM" SG_ 274 CRC_ORC3 0;
BA_ "GenSigTimeoutTime_EPS" SG_ 274 CRC_ORC3 0;
BA_ "GenSigTimeoutTime_EVCU2" SG_ 274 CRC_ORC3 0;
BA_ "GenSigTimeoutTime_ORC" SG_ 274 CRC_ORC3 0;
BA_ "GenSigTimeoutTime_BSM2" SG_ 274 InternalError 0;
BA_ "GenSigTimeoutTime_CVADAS" SG_ 274 InternalError 0;
BA_ "GenSigTimeoutTime_ECM" SG_ 274 InternalError 0;
BA_ "GenSigTimeoutTime_EPS" SG_ 274 InternalError 0;
BA_ "GenSigTimeoutTime_EVCU2" SG_ 274 InternalError 0;
BA_ "GenSigTimeoutTime_ORC" SG_ 274 InternalError 0;
BA_ "GenSigStartValue" SG_ 274 LatAcceleration 4095;
BA_ "GenSigTimeoutTime_BSM2" SG_ 274 LatAcceleration 0;
BA_ "GenSigTimeoutTime_CVADAS" SG_ 274 LatAcceleration 0;
BA_ "GenSigTimeoutTime_ECM" SG_ 274 LatAcceleration 0;
BA_ "GenSigTimeoutTime_EPS" SG_ 274 LatAcceleration 0;
BA_ "GenSigTimeoutTime_ORC" SG_ 274 LatAcceleration 0;
BA_ "GenSigTimeoutTime_BSM2" SG_ 274 LatAccelerationFailSts 0;
BA_ "GenSigTimeoutTime_CVADAS" SG_ 274 LatAccelerationFailSts 0;
BA_ "GenSigTimeoutTime_ECM" SG_ 274 LatAccelerationFailSts 0;
BA_ "GenSigTimeoutTime_EPS" SG_ 274 LatAccelerationFailSts 0;
BA_ "GenSigTimeoutTime_ORC" SG_ 274 LatAccelerationFailSts 0;
BA_ "GenSigStartValue" SG_ 274 LongAcceleration 4095;
BA_ "GenSigTimeoutTime_BSM2" SG_ 274 LongAcceleration 0;
BA_ "GenSigTimeoutTime_CVADAS" SG_ 274 LongAcceleration 0;
BA_ "GenSigTimeoutTime_ECM" SG_ 274 LongAcceleration 0;
BA_ "GenSigTimeoutTime_EPS" SG_ 274 LongAcceleration 0;
BA_ "GenSigTimeoutTime_ORC" SG_ 274 LongAcceleration 0;
BA_ "GenSigTimeoutTime_BSM2" SG_ 274 LongAccelerationFailSts 0;
BA_ "GenSigTimeoutTime_CVADAS" SG_ 274 LongAccelerationFailSts 0;
BA_ "GenSigTimeoutTime_ECM" SG_ 274 LongAccelerationFailSts 0;
BA_ "GenSigTimeoutTime_EPS" SG_ 274 LongAccelerationFailSts 0;
BA_ "GenSigTimeoutTime_ORC" SG_ 274 LongAccelerationFailSts 0;
BA_ "GenSigTimeoutTime_BSM2" SG_ 274 MessageCounter_ORC3 0;
BA_ "GenSigTimeoutTime_CVADAS" SG_ 274 MessageCounter_ORC3 0;
BA_ "GenSigTimeoutTime_ECM" SG_ 274 MessageCounter_ORC3 0;
BA_ "GenSigTimeoutTime_EPS" SG_ 274 MessageCounter_ORC3 0;
BA_ "GenSigTimeoutTime_EVCU2" SG_ 274 MessageCounter_ORC3 0;
BA_ "GenSigTimeoutTime_ORC" SG_ 274 MessageCounter_ORC3 0;
BA_ "GenSigStartValue" SG_ 274 YawRate 4095;
BA_ "GenSigTimeoutTime_BSM2" SG_ 274 YawRate 0;
BA_ "GenSigTimeoutTime_CVADAS" SG_ 274 YawRate 0;
BA_ "GenSigTimeoutTime_ECM" SG_ 274 YawRate 0;
BA_ "GenSigTimeoutTime_EPS" SG_ 274 YawRate 0;
BA_ "GenSigTimeoutTime_ORC" SG_ 274 YawRate 0;
BA_ "GenSigTimeoutTime_BSM" SG_ 274 YawRate_HR 0;
BA_ "GenSigTimeoutTime_BSM2" SG_ 274 YawRate_HR 0;
BA_ "GenSigTimeoutTime_CVADAS" SG_ 274 YawRate_HR 0;
BA_ "GenSigTimeoutTime_ECM" SG_ 274 YawRate_HR 0;
BA_ "GenSigTimeoutTime_EPS" SG_ 274 YawRate_HR 0;
BA_ "GenSigTimeoutTime_EVCU2" SG_ 274 YawRate_HR 0;
BA_ "GenSigTimeoutTime_ORC" SG_ 274 YawRate_HR 0;
BA_ "GenSigTimeoutTime_BSM" SG_ 274 YawRate_HR_Sign 0;
BA_ "GenSigTimeoutTime_BSM2" SG_ 274 YawRate_HR_Sign 0;
BA_ "GenSigTimeoutTime_CVADAS" SG_ 274 YawRate_HR_Sign 0;
BA_ "GenSigTimeoutTime_ECM" SG_ 274 YawRate_HR_Sign 0;
BA_ "GenSigTimeoutTime_EPS" SG_ 274 YawRate_HR_Sign 0;
BA_ "GenSigTimeoutTime_EVCU2" SG_ 274 YawRate_HR_Sign 0;
BA_ "GenSigTimeoutTime_ORC" SG_ 274 YawRate_HR_Sign 0;
BA_ "GenSigTimeoutTime_BSM2" SG_ 274 YawRateFailSts 0;
BA_ "GenSigTimeoutTime_CVADAS" SG_ 274 YawRateFailSts 0;
BA_ "GenSigTimeoutTime_ECM" SG_ 274 YawRateFailSts 0;
BA_ "GenSigTimeoutTime_EPS" SG_ 274 YawRateFailSts 0;
BA_ "GenSigTimeoutTime_ORC" SG_ 274 YawRateFailSts 0;
BA_ "GenSigTimeoutTime_BSM2" SG_ 263 CRC_PT_SYSTEM_FD_1 0;
BA_ "GenSigTimeoutTime_CVADAS" SG_ 263 CRC_PT_SYSTEM_FD_1 0;
BA_ "GenSigTimeoutTime_EPS" SG_ 263 CRC_PT_SYSTEM_FD_1 0;
BA_ "GenSigTimeoutTime_EVCU2" SG_ 263 CRC_PT_SYSTEM_FD_1 0;
BA_ "GenSigTimeoutTime_ORC" SG_ 263 CRC_PT_SYSTEM_FD_1 0;
BA_ "GenSigTimeoutTime_BSM" SG_ 263 DriveReady_PT 0;
BA_ "GenSigTimeoutTime_BSM2" SG_ 263 DriveReady_PT 0;
BA_ "GenSigTimeoutTime_CADM" SG_ 263 DriveReady_PT 0;
BA_ "GenSigTimeoutTime_CVADAS" SG_ 263 DriveReady_PT 0;
BA_ "GenSigTimeoutTime_ECM" SG_ 263 DriveReady_PT 0;
BA_ "GenSigTimeoutTime_EPS" SG_ 263 DriveReady_PT 0;
BA_ "GenSigTimeoutTime_EVCU2" SG_ 263 DriveReady_PT 0;
BA_ "GenSigTimeoutTime_ORC" SG_ 263 DriveReady_PT 0;
BA_ "GenSigTimeoutTime_BSM" SG_ 263 EVCU2_THA_Resp 0;
BA_ "GenSigTimeoutTime_BSM2" SG_ 263 EVCU2_THA_Resp 0;
BA_ "GenSigTimeoutTime_CADM" SG_ 263 EVCU2_THA_Resp 0;
BA_ "GenSigTimeoutTime_ECM" SG_ 263 EVCU2_THA_Resp 0;
BA_ "GenSigTimeoutTime_EPS" SG_ 263 EVCU2_THA_Resp 0;
BA_ "GenSigTimeoutTime_EVCU2" SG_ 263 EVCU2_THA_Resp 0;
BA_ "GenSigTimeoutTime_ORC" SG_ 263 EVCU2_THA_Resp 0;
BA_ "GenSigTimeoutTime_BSM2" SG_ 263 GasPedalPosition_PT 0;
BA_ "GenSigTimeoutTime_CADM" SG_ 263 GasPedalPosition_PT 0;
BA_ "GenSigTimeoutTime_CVADAS" SG_ 263 GasPedalPosition_PT 0;
BA_ "GenSigTimeoutTime_ECM" SG_ 263 GasPedalPosition_PT 0;
BA_ "GenSigTimeoutTime_EPS" SG_ 263 GasPedalPosition_PT 0;
BA_ "GenSigTimeoutTime_EVCU2" SG_ 263 GasPedalPosition_PT 0;
BA_ "GenSigTimeoutTime_ORC" SG_ 263 GasPedalPosition_PT 0;
BA_ "GenSigTimeoutTime_BSM" SG_ 263 GasPedalPositionFailSts_PT 0;
BA_ "GenSigTimeoutTime_BSM2" SG_ 263 GasPedalPositionFailSts_PT 0;
BA_ "GenSigTimeoutTime_CVADAS" SG_ 263 GasPedalPositionFailSts_PT 0;
BA_ "GenSigTimeoutTime_ECM" SG_ 263 GasPedalPositionFailSts_PT 0;
BA_ "GenSigTimeoutTime_EPS" SG_ 263 GasPedalPositionFailSts_PT 0;
BA_ "GenSigTimeoutTime_EVCU2" SG_ 263 GasPedalPositionFailSts_PT 0;
BA_ "GenSigTimeoutTime_ORC" SG_ 263 GasPedalPositionFailSts_PT 0;
BA_ "GenSigTimeoutTime_BSM" SG_ 263 GearEngaged_PT 0;
BA_ "GenSigTimeoutTime_CADM" SG_ 263 GearEngaged_PT 0;
BA_ "GenSigTimeoutTime_CVADAS" SG_ 263 GearEngaged_PT 0;
BA_ "GenSigTimeoutTime_ECM" SG_ 263 GearEngaged_PT 0;
BA_ "GenSigTimeoutTime_EVCU2" SG_ 263 GearEngaged_PT 0;
BA_ "GenSigTimeoutTime_ORC" SG_ 263 GearEngaged_PT 0;
BA_ "GenSigTimeoutTime_BSM" SG_ 263 GearEngagedForDisplay_PT 0;
BA_ "GenSigTimeoutTime_BSM2" SG_ 263 GearEngagedForDisplay_PT 0;
BA_ "GenSigTimeoutTime_CADM" SG_ 263 GearEngagedForDisplay_PT 0;
BA_ "GenSigTimeoutTime_ECM" SG_ 263 GearEngagedForDisplay_PT 0;
BA_ "GenSigTimeoutTime_EVCU2" SG_ 263 GearEngagedForDisplay_PT 0;
BA_ "GenSigTimeoutTime_ORC" SG_ 263 GearEngagedForDisplay_PT 0;
BA_ "GenSigTimeoutTime_BSM2" SG_ 263 MessageCounter_PT_SYSTEM_FD_1 0;
BA_ "GenSigTimeoutTime_CVADAS" SG_ 263 MessageCounter_PT_SYSTEM_FD_1 0;
BA_ "GenSigTimeoutTime_EPS" SG_ 263 MessageCounter_PT_SYSTEM_FD_1 0;
BA_ "GenSigTimeoutTime_EVCU2" SG_ 263 MessageCounter_PT_SYSTEM_FD_1 0;
BA_ "GenSigTimeoutTime_ORC" SG_ 263 MessageCounter_PT_SYSTEM_FD_1 0;
BA_ "GenSigTimeoutTime_ECM" SG_ 263 PdlPosActual_PT 0;
BA_ "GenSigTimeoutTime_EPS" SG_ 263 PdlPosActual_PT 0;
BA_ "GenSigTimeoutTime_EVCU2" SG_ 263 PdlPosActual_PT 0;
BA_ "GenSigTimeoutTime_ORC" SG_ 263 PdlPosActual_PT 0;
BA_ "GenSigTimeoutTime_BSM2" SG_ 263 PowertrainPrplsnActv_PT 0;
BA_ "GenSigTimeoutTime_ECM" SG_ 263 PowertrainPrplsnActv_PT 0;
BA_ "GenSigTimeoutTime_EPS" SG_ 263 PowertrainPrplsnActv_PT 0;
BA_ "GenSigTimeoutTime_EVCU2" SG_ 263 PowertrainPrplsnActv_PT 0;
BA_ "GenSigTimeoutTime_ORC" SG_ 263 PowertrainPrplsnActv_PT 0;
BA_ "GenSigTimeoutTime_BSM" SG_ 263 ShiftLeverPosition_PT 0;
BA_ "GenSigTimeoutTime_BSM2" SG_ 263 ShiftLeverPosition_PT 0;
BA_ "GenSigTimeoutTime_CADM" SG_ 263 ShiftLeverPosition_PT 0;
BA_ "GenSigTimeoutTime_CVADAS" SG_ 263 ShiftLeverPosition_PT 0;
BA_ "GenSigTimeoutTime_ECM" SG_ 263 ShiftLeverPosition_PT 0;
BA_ "GenSigTimeoutTime_EPS" SG_ 263 ShiftLeverPosition_PT 0;
BA_ "GenSigTimeoutTime_EVCU2" SG_ 263 ShiftLeverPosition_PT 0;
BA_ "GenSigTimeoutTime_ORC" SG_ 263 ShiftLeverPosition_PT 0;
BA_ "GenSigTimeoutTime_BSM" SG_ 263 TargetGear_PT 0;
BA_ "GenSigTimeoutTime_BSM2" SG_ 263 TargetGear_PT 0;
BA_ "GenSigTimeoutTime_CADM" SG_ 263 TargetGear_PT 0;
BA_ "GenSigTimeoutTime_CVADAS" SG_ 263 TargetGear_PT 0;
BA_ "GenSigTimeoutTime_ECM" SG_ 263 TargetGear_PT 0;
BA_ "GenSigTimeoutTime_EPS" SG_ 263 TargetGear_PT 0;
BA_ "GenSigTimeoutTime_EVCU2" SG_ 263 TargetGear_PT 0;
BA_ "GenSigTimeoutTime_ORC" SG_ 263 TargetGear_PT 0;
BA_ "GenSigTimeoutTime_BSM" SG_ 255 ACC_NCC_TrqEnblRq_Allowed 0;
BA_ "GenSigTimeoutTime_BSM2" SG_ 255 ACC_NCC_TrqEnblRq_Allowed 0;
BA_ "GenSigTimeoutTime_CVADAS" SG_ 255 ACC_NCC_TrqEnblRq_Allowed 0;
BA_ "GenSigTimeoutTime_ECM" SG_ 255 ACC_NCC_TrqEnblRq_Allowed 0;
BA_ "GenSigTimeoutTime_EPS" SG_ 255 ACC_NCC_TrqEnblRq_Allowed 0;
BA_ "GenSigTimeoutTime_EVCU2" SG_ 255 ACC_NCC_TrqEnblRq_Allowed 0;
BA_ "GenSigTimeoutTime_ORC" SG_ 255 ACC_NCC_TrqEnblRq_Allowed 0;
BA_ "GenSigTimeoutTime_BSM2" SG_ 255 Accel_Pedal_Override 0;
BA_ "GenSigTimeoutTime_ECM" SG_ 255 Accel_Pedal_Override 0;
BA_ "GenSigTimeoutTime_EPS" SG_ 255 Accel_Pedal_Override 0;
BA_ "GenSigTimeoutTime_EVCU2" SG_ 255 Accel_Pedal_Override 0;
BA_ "GenSigTimeoutTime_ORC" SG_ 255 Accel_Pedal_Override 0;
BA_ "GenSigTimeoutTime_BSM2" SG_ 255 CRC_PT_TORQUE_FD_1 0;
BA_ "GenSigTimeoutTime_CVADAS" SG_ 255 CRC_PT_TORQUE_FD_1 0;
BA_ "GenSigTimeoutTime_ECM" SG_ 255 CRC_PT_TORQUE_FD_1 0;
BA_ "GenSigTimeoutTime_EPS" SG_ 255 CRC_PT_TORQUE_FD_1 0;
BA_ "GenSigTimeoutTime_EVCU2" SG_ 255 CRC_PT_TORQUE_FD_1 0;
BA_ "GenSigTimeoutTime_ORC" SG_ 255 CRC_PT_TORQUE_FD_1 0;
BA_ "GenSigTimeoutTime_BSM" SG_ 255 ESC_TrqEnblRq_Allowed 0;
BA_ "GenSigTimeoutTime_BSM2" SG_ 255 ESC_TrqEnblRq_Allowed 0;
BA_ "GenSigTimeoutTime_CADM" SG_ 255 ESC_TrqEnblRq_Allowed 0;
BA_ "GenSigTimeoutTime_CVADAS" SG_ 255 ESC_TrqEnblRq_Allowed 0;
BA_ "GenSigTimeoutTime_ECM" SG_ 255 ESC_TrqEnblRq_Allowed 0;
BA_ "GenSigTimeoutTime_EPS" SG_ 255 ESC_TrqEnblRq_Allowed 0;
BA_ "GenSigTimeoutTime_EVCU2" SG_ 255 ESC_TrqEnblRq_Allowed 0;
BA_ "GenSigTimeoutTime_ORC" SG_ 255 ESC_TrqEnblRq_Allowed 0;
BA_ "GenSigStartValue" SG_ 255 Front_AxleTorque_Static 32767;
BA_ "GenSigTimeoutTime_BSM" SG_ 255 Front_AxleTorque_Static 0;
BA_ "GenSigTimeoutTime_BSM2" SG_ 255 Front_AxleTorque_Static 0;
BA_ "GenSigTimeoutTime_CADM" SG_ 255 Front_AxleTorque_Static 0;
BA_ "GenSigTimeoutTime_CVADAS" SG_ 255 Front_AxleTorque_Static 0;
BA_ "GenSigTimeoutTime_ECM" SG_ 255 Front_AxleTorque_Static 0;
BA_ "GenSigTimeoutTime_EPS" SG_ 255 Front_AxleTorque_Static 0;
BA_ "GenSigTimeoutTime_EVCU2" SG_ 255 Front_AxleTorque_Static 0;
BA_ "GenSigTimeoutTime_ORC" SG_ 255 Front_AxleTorque_Static 0;
BA_ "GenSigTimeoutTime_BSM2" SG_ 255 MessageCounter_PT_TORQUE_FD_1 0;
BA_ "GenSigTimeoutTime_CVADAS" SG_ 255 MessageCounter_PT_TORQUE_FD_1 0;
BA_ "GenSigTimeoutTime_ECM" SG_ 255 MessageCounter_PT_TORQUE_FD_1 0;
BA_ "GenSigTimeoutTime_EPS" SG_ 255 MessageCounter_PT_TORQUE_FD_1 0;
BA_ "GenSigTimeoutTime_EVCU2" SG_ 255 MessageCounter_PT_TORQUE_FD_1 0;
BA_ "GenSigTimeoutTime_ORC" SG_ 255 MessageCounter_PT_TORQUE_FD_1 0;
BA_ "GenSigTimeoutTime_BSM2" SG_ 255 PPPA_TrqEnblRq_Allowed 0;
BA_ "GenSigTimeoutTime_CADM" SG_ 255 PPPA_TrqEnblRq_Allowed 0;
BA_ "GenSigTimeoutTime_ECM" SG_ 255 PPPA_TrqEnblRq_Allowed 0;
BA_ "GenSigTimeoutTime_EPS" SG_ 255 PPPA_TrqEnblRq_Allowed 0;
BA_ "GenSigTimeoutTime_EVCU2" SG_ 255 PPPA_TrqEnblRq_Allowed 0;
BA_ "GenSigTimeoutTime_ORC" SG_ 255 PPPA_TrqEnblRq_Allowed 0;
BA_ "GenSigStartValue" SG_ 255 Rear_AxleTorque_Static 32767;
BA_ "GenSigTimeoutTime_BSM" SG_ 255 Rear_AxleTorque_Static 0;
BA_ "GenSigTimeoutTime_BSM2" SG_ 255 Rear_AxleTorque_Static 0;
BA_ "GenSigTimeoutTime_CADM" SG_ 255 Rear_AxleTorque_Static 0;
BA_ "GenSigTimeoutTime_CVADAS" SG_ 255 Rear_AxleTorque_Static 0;
BA_ "GenSigTimeoutTime_ECM" SG_ 255 Rear_AxleTorque_Static 0;
BA_ "GenSigTimeoutTime_EPS" SG_ 255 Rear_AxleTorque_Static 0;
BA_ "GenSigTimeoutTime_EVCU2" SG_ 255 Rear_AxleTorque_Static 0;
BA_ "GenSigTimeoutTime_ORC" SG_ 255 Rear_AxleTorque_Static 0;
BA_ "GenSigTimeoutTime_BSM" SG_ 255 RRCC_TrqEnblRq_Allowed 0;
BA_ "GenSigTimeoutTime_BSM2" SG_ 255 RRCC_TrqEnblRq_Allowed 0;
BA_ "GenSigTimeoutTime_CVADAS" SG_ 255 RRCC_TrqEnblRq_Allowed 0;
BA_ "GenSigTimeoutTime_ECM" SG_ 255 RRCC_TrqEnblRq_Allowed 0;
BA_ "GenSigTimeoutTime_EPS" SG_ 255 RRCC_TrqEnblRq_Allowed 0;
BA_ "GenSigTimeoutTime_EVCU2" SG_ 255 RRCC_TrqEnblRq_Allowed 0;
BA_ "GenSigTimeoutTime_ORC" SG_ 255 RRCC_TrqEnblRq_Allowed 0;
BA_ "GenSigTimeoutTime_BSM" SG_ 255 SSC_TrqEnblRq_Allowed 0;
BA_ "GenSigTimeoutTime_BSM2" SG_ 255 SSC_TrqEnblRq_Allowed 0;
BA_ "GenSigTimeoutTime_CADM" SG_ 255 SSC_TrqEnblRq_Allowed 0;
BA_ "GenSigTimeoutTime_CVADAS" SG_ 255 SSC_TrqEnblRq_Allowed 0;
BA_ "GenSigTimeoutTime_ECM" SG_ 255 SSC_TrqEnblRq_Allowed 0;
BA_ "GenSigTimeoutTime_EPS" SG_ 255 SSC_TrqEnblRq_Allowed 0;
BA_ "GenSigTimeoutTime_EVCU2" SG_ 255 SSC_TrqEnblRq_Allowed 0;
BA_ "GenSigTimeoutTime_ORC" SG_ 255 SSC_TrqEnblRq_Allowed 0;
BA_ "GenSigTimeoutTime_BSM" SG_ 255 SumTorque_DrvReqMod 0;
BA_ "GenSigTimeoutTime_BSM2" SG_ 255 SumTorque_DrvReqMod 0;
BA_ "GenSigTimeoutTime_CADM" SG_ 255 SumTorque_DrvReqMod 0;
BA_ "GenSigTimeoutTime_CVADAS" SG_ 255 SumTorque_DrvReqMod 0;
BA_ "GenSigTimeoutTime_ECM" SG_ 255 SumTorque_DrvReqMod 0;
BA_ "GenSigTimeoutTime_EPS" SG_ 255 SumTorque_DrvReqMod 0;
BA_ "GenSigTimeoutTime_EVCU2" SG_ 255 SumTorque_DrvReqMod 0;
BA_ "GenSigTimeoutTime_ORC" SG_ 255 SumTorque_DrvReqMod 0;
BA_ "GenSigTimeoutTime_BSM" SG_ 255 SumTorqueExp 0;
BA_ "GenSigTimeoutTime_BSM2" SG_ 255 SumTorqueExp 0;
BA_ "GenSigTimeoutTime_CADM" SG_ 255 SumTorqueExp 0;
BA_ "GenSigTimeoutTime_CVADAS" SG_ 255 SumTorqueExp 0;
BA_ "GenSigTimeoutTime_ECM" SG_ 255 SumTorqueExp 0;
BA_ "GenSigTimeoutTime_EPS" SG_ 255 SumTorqueExp 0;
BA_ "GenSigTimeoutTime_EVCU2" SG_ 255 SumTorqueExp 0;
BA_ "GenSigTimeoutTime_ORC" SG_ 255 SumTorqueExp 0;
BA_ "GenSigTimeoutTime_BSM" SG_ 255 SumTorqueMax 0;
BA_ "GenSigTimeoutTime_BSM2" SG_ 255 SumTorqueMax 0;
BA_ "GenSigTimeoutTime_CADM" SG_ 255 SumTorqueMax 0;
BA_ "GenSigTimeoutTime_CVADAS" SG_ 255 SumTorqueMax 0;
BA_ "GenSigTimeoutTime_ECM" SG_ 255 SumTorqueMax 0;
BA_ "GenSigTimeoutTime_EPS" SG_ 255 SumTorqueMax 0;
BA_ "GenSigTimeoutTime_EVCU2" SG_ 255 SumTorqueMax 0;
BA_ "GenSigTimeoutTime_ORC" SG_ 255 SumTorqueMax 0;
BA_ "GenSigTimeoutTime_BSM" SG_ 255 SumTorqueMin 0;
BA_ "GenSigTimeoutTime_BSM2" SG_ 255 SumTorqueMin 0;
BA_ "GenSigTimeoutTime_CADM" SG_ 255 SumTorqueMin 0;
BA_ "GenSigTimeoutTime_CVADAS" SG_ 255 SumTorqueMin 0;
BA_ "GenSigTimeoutTime_ECM" SG_ 255 SumTorqueMin 0;
BA_ "GenSigTimeoutTime_EPS" SG_ 255 SumTorqueMin 0;
BA_ "GenSigTimeoutTime_EVCU2" SG_ 255 SumTorqueMin 0;
BA_ "GenSigTimeoutTime_ORC" SG_ 255 SumTorqueMin 0;
BA_ "GenSigTimeoutTime_BSM" SG_ 255 SumTorqueSel_D_TTC 0;
BA_ "GenSigTimeoutTime_BSM2" SG_ 255 SumTorqueSel_D_TTC 0;
BA_ "GenSigTimeoutTime_CADM" SG_ 255 SumTorqueSel_D_TTC 0;
BA_ "GenSigTimeoutTime_CVADAS" SG_ 255 SumTorqueSel_D_TTC 0;
BA_ "GenSigTimeoutTime_ECM" SG_ 255 SumTorqueSel_D_TTC 0;
BA_ "GenSigTimeoutTime_EPS" SG_ 255 SumTorqueSel_D_TTC 0;
BA_ "GenSigTimeoutTime_EVCU2" SG_ 255 SumTorqueSel_D_TTC 0;
BA_ "GenSigTimeoutTime_ORC" SG_ 255 SumTorqueSel_D_TTC 0;
BA_ "GenSigTimeoutTime_BSM" SG_ 255 SumTorqueStatic 0;
BA_ "GenSigTimeoutTime_BSM2" SG_ 255 SumTorqueStatic 0;
BA_ "GenSigTimeoutTime_CADM" SG_ 255 SumTorqueStatic 0;
BA_ "GenSigTimeoutTime_CVADAS" SG_ 255 SumTorqueStatic 0;
BA_ "GenSigTimeoutTime_ECM" SG_ 255 SumTorqueStatic 0;
BA_ "GenSigTimeoutTime_EPS" SG_ 255 SumTorqueStatic 0;
BA_ "GenSigTimeoutTime_EVCU2" SG_ 255 SumTorqueStatic 0;
BA_ "GenSigTimeoutTime_ORC" SG_ 255 SumTorqueStatic 0;
BA_ "GenSigStartValue" SG_ 255 Total_AxleTorque_Static 32767;
BA_ "GenSigTimeoutTime_BSM" SG_ 255 Total_AxleTorque_Static 0;
BA_ "GenSigTimeoutTime_BSM2" SG_ 255 Total_AxleTorque_Static 0;
BA_ "GenSigTimeoutTime_CVADAS" SG_ 255 Total_AxleTorque_Static 0;
BA_ "GenSigTimeoutTime_ECM" SG_ 255 Total_AxleTorque_Static 0;
BA_ "GenSigTimeoutTime_EPS" SG_ 255 Total_AxleTorque_Static 0;
BA_ "GenSigTimeoutTime_EVCU2" SG_ 255 Total_AxleTorque_Static 0;
BA_ "GenSigTimeoutTime_ORC" SG_ 255 Total_AxleTorque_Static 0;
BA_ "GenSigTimeoutTime_BSM2" SG_ 1472 CRC_TRSCM1 0;
BA_ "GenSigTimeoutTime_CADM" SG_ 1472 CRC_TRSCM1 0;
BA_ "GenSigTimeoutTime_CVADAS" SG_ 1472 CRC_TRSCM1 0;
BA_ "GenSigTimeoutTime_EVCU2" SG_ 1472 CRC_TRSCM1 0;
BA_ "GenSigTimeoutTime_ORC" SG_ 1472 CRC_TRSCM1 0;
BA_ "GenSigTimeoutTime_BSM2" SG_ 1472 MessageCounter_TRSCM1 0;
BA_ "GenSigTimeoutTime_CADM" SG_ 1472 MessageCounter_TRSCM1 0;
BA_ "GenSigTimeoutTime_CVADAS" SG_ 1472 MessageCounter_TRSCM1 0;
BA_ "GenSigTimeoutTime_EVCU2" SG_ 1472 MessageCounter_TRSCM1 0;
BA_ "GenSigTimeoutTime_ORC" SG_ 1472 MessageCounter_TRSCM1 0;
BA_ "GenSigSendType" SG_ 1472 THA_EPB_Req 4;
BA_ "GenSigTimeoutTime_BSM2" SG_ 1472 THA_EPB_Req 0;
BA_ "GenSigTimeoutTime_CADM" SG_ 1472 THA_EPB_Req 0;
BA_ "GenSigTimeoutTime_CVADAS" SG_ 1472 THA_EPB_Req 0;
BA_ "GenSigTimeoutTime_ECM" SG_ 1472 THA_EPB_Req 0;
BA_ "GenSigTimeoutTime_EPS" SG_ 1472 THA_EPB_Req 0;
BA_ "GenSigTimeoutTime_EVCU2" SG_ 1472 THA_EPB_Req 0;
BA_ "GenSigTimeoutTime_ORC" SG_ 1472 THA_EPB_Req 0;
BA_ "GenSigSendType" SG_ 1472 THA_Speed_Limit 4;
BA_ "GenSigTimeoutTime_BSM2" SG_ 1472 THA_Speed_Limit 0;
BA_ "GenSigTimeoutTime_CADM" SG_ 1472 THA_Speed_Limit 0;
BA_ "GenSigTimeoutTime_CVADAS" SG_ 1472 THA_Speed_Limit 0;
BA_ "GenSigTimeoutTime_ORC" SG_ 1472 THA_Speed_Limit 0;
BA_ "GenSigSendType" SG_ 1472 THA_SpeedLimit_Req 4;
BA_ "GenSigTimeoutTime_BSM2" SG_ 1472 THA_SpeedLimit_Req 0;
BA_ "GenSigTimeoutTime_CADM" SG_ 1472 THA_SpeedLimit_Req 0;
BA_ "GenSigTimeoutTime_CVADAS" SG_ 1472 THA_SpeedLimit_Req 0;
BA_ "GenSigTimeoutTime_EPS" SG_ 1472 THA_SpeedLimit_Req 0;
BA_ "GenSigTimeoutTime_ORC" SG_ 1472 THA_SpeedLimit_Req 0;
BA_ "GenSigSendType" SG_ 1472 THA_STAT 4;
BA_ "GenSigTimeoutTime_BSM2" SG_ 1472 THA_STAT 0;
BA_ "GenSigTimeoutTime_CADM" SG_ 1472 THA_STAT 0;
BA_ "GenSigTimeoutTime_CVADAS" SG_ 1472 THA_STAT 0;
BA_ "GenSigTimeoutTime_ORC" SG_ 1472 THA_STAT 0;
BA_ "GenSigStartValue" SG_ 1472 THA_SteeringDamping 100;
BA_ "GenSigSendType" SG_ 1472 THA_SteeringDamping 3;
BA_ "GenSigTimeoutTime_BSM" SG_ 1472 THA_SteeringDamping 0;
BA_ "GenSigTimeoutTime_BSM2" SG_ 1472 THA_SteeringDamping 0;
BA_ "GenSigTimeoutTime_CADM" SG_ 1472 THA_SteeringDamping 0;
BA_ "GenSigTimeoutTime_CVADAS" SG_ 1472 THA_SteeringDamping 0;
BA_ "GenSigTimeoutTime_ECM" SG_ 1472 THA_SteeringDamping 0;
BA_ "GenSigTimeoutTime_EVCU2" SG_ 1472 THA_SteeringDamping 0;
BA_ "GenSigTimeoutTime_ORC" SG_ 1472 THA_SteeringDamping 0;
BA_ "GenSigStartValue" SG_ 1472 THA_SteeringTorqueInfo 1024;
BA_ "GenSigSendType" SG_ 1472 THA_SteeringTorqueInfo 3;
BA_ "GenSigTimeoutTime_BSM" SG_ 1472 THA_SteeringTorqueInfo 0;
BA_ "GenSigTimeoutTime_BSM2" SG_ 1472 THA_SteeringTorqueInfo 0;
BA_ "GenSigTimeoutTime_CADM" SG_ 1472 THA_SteeringTorqueInfo 0;
BA_ "GenSigTimeoutTime_CVADAS" SG_ 1472 THA_SteeringTorqueInfo 0;
BA_ "GenSigTimeoutTime_ECM" SG_ 1472 THA_SteeringTorqueInfo 0;
BA_ "GenSigTimeoutTime_EVCU2" SG_ 1472 THA_SteeringTorqueInfo 0;
BA_ "GenSigTimeoutTime_ORC" SG_ 1472 THA_SteeringTorqueInfo 0;
BA_ "GenSigSendType" SG_ 1472 THA_SteeringTorqueReq 4;
BA_ "GenSigTimeoutTime_BSM" SG_ 1472 THA_SteeringTorqueReq 0;
BA_ "GenSigTimeoutTime_BSM2" SG_ 1472 THA_SteeringTorqueReq 0;
BA_ "GenSigTimeoutTime_CADM" SG_ 1472 THA_SteeringTorqueReq 0;
BA_ "GenSigTimeoutTime_CVADAS" SG_ 1472 THA_SteeringTorqueReq 0;
BA_ "GenSigTimeoutTime_ECM" SG_ 1472 THA_SteeringTorqueReq 0;
BA_ "GenSigTimeoutTime_EVCU2" SG_ 1472 THA_SteeringTorqueReq 0;
BA_ "GenSigTimeoutTime_ORC" SG_ 1472 THA_SteeringTorqueReq 0;
BA_ "GenSigSendType" SG_ 1472 TRSC_SpeedLimit_Req 3;
BA_ "GenSigTimeoutTime_BSM2" SG_ 1472 TRSC_SpeedLimit_Req 0;
BA_ "GenSigTimeoutTime_CADM" SG_ 1472 TRSC_SpeedLimit_Req 0;
BA_ "GenSigTimeoutTime_CVADAS" SG_ 1472 TRSC_SpeedLimit_Req 0;
BA_ "GenSigTimeoutTime_EPS" SG_ 1472 TRSC_SpeedLimit_Req 0;
BA_ "GenSigTimeoutTime_EVCU2" SG_ 1472 TRSC_SpeedLimit_Req 0;
BA_ "GenSigTimeoutTime_ORC" SG_ 1472 TRSC_SpeedLimit_Req 0;
BA_ "GenSigStartValue" SG_ 1472 TRSC_STAT 1;
BA_ "GenSigSendType" SG_ 1472 TRSC_STAT 3;
BA_ "GenSigTimeoutTime_BSM2" SG_ 1472 TRSC_STAT 0;
BA_ "GenSigTimeoutTime_CADM" SG_ 1472 TRSC_STAT 0;
BA_ "GenSigTimeoutTime_CVADAS" SG_ 1472 TRSC_STAT 0;
BA_ "GenSigTimeoutTime_EVCU2" SG_ 1472 TRSC_STAT 0;
BA_ "GenSigTimeoutTime_ORC" SG_ 1472 TRSC_STAT 0;
BA_ "GenSigStartValue" SG_ 1472 TRSC_SteeringDamping 100;
BA_ "GenSigTimeoutTime_BSM" SG_ 1472 TRSC_SteeringDamping 0;
BA_ "GenSigTimeoutTime_BSM2" SG_ 1472 TRSC_SteeringDamping 0;
BA_ "GenSigTimeoutTime_CADM" SG_ 1472 TRSC_SteeringDamping 0;
BA_ "GenSigTimeoutTime_CVADAS" SG_ 1472 TRSC_SteeringDamping 0;
BA_ "GenSigTimeoutTime_ECM" SG_ 1472 TRSC_SteeringDamping 0;
BA_ "GenSigTimeoutTime_EVCU2" SG_ 1472 TRSC_SteeringDamping 0;
BA_ "GenSigTimeoutTime_ORC" SG_ 1472 TRSC_SteeringDamping 0;
BA_ "GenSigStartValue" SG_ 1472 TRSC_SteeringTorqueInfo 1024;
BA_ "GenSigSendType" SG_ 1472 TRSC_SteeringTorqueInfo 3;
BA_ "GenSigTimeoutTime_BSM" SG_ 1472 TRSC_SteeringTorqueInfo 0;
BA_ "GenSigTimeoutTime_BSM2" SG_ 1472 TRSC_SteeringTorqueInfo 0;
BA_ "GenSigTimeoutTime_CADM" SG_ 1472 TRSC_SteeringTorqueInfo 0;
BA_ "GenSigTimeoutTime_CVADAS" SG_ 1472 TRSC_SteeringTorqueInfo 0;
BA_ "GenSigTimeoutTime_ECM" SG_ 1472 TRSC_SteeringTorqueInfo 0;
BA_ "GenSigTimeoutTime_EVCU2" SG_ 1472 TRSC_SteeringTorqueInfo 0;
BA_ "GenSigTimeoutTime_ORC" SG_ 1472 TRSC_SteeringTorqueInfo 0;
BA_ "GenSigSendType" SG_ 1472 TRSC_SteeringTorqueReq 3;
BA_ "GenSigTimeoutTime_BSM" SG_ 1472 TRSC_SteeringTorqueReq 0;
BA_ "GenSigTimeoutTime_BSM2" SG_ 1472 TRSC_SteeringTorqueReq 0;
BA_ "GenSigTimeoutTime_CADM" SG_ 1472 TRSC_SteeringTorqueReq 0;
BA_ "GenSigTimeoutTime_CVADAS" SG_ 1472 TRSC_SteeringTorqueReq 0;
BA_ "GenSigTimeoutTime_ECM" SG_ 1472 TRSC_SteeringTorqueReq 0;
BA_ "GenSigTimeoutTime_EVCU2" SG_ 1472 TRSC_SteeringTorqueReq 0;
BA_ "GenSigTimeoutTime_ORC" SG_ 1472 TRSC_SteeringTorqueReq 0;
BA_ "GenSigStartValue" SG_ 1472 TRSC_VehicleStop_Req 3;
BA_ "GenSigSendType" SG_ 1472 TRSC_VehicleStop_Req 3;
BA_ "GenSigTimeoutTime_BSM2" SG_ 1472 TRSC_VehicleStop_Req 0;
BA_ "GenSigTimeoutTime_CADM" SG_ 1472 TRSC_VehicleStop_Req 0;
BA_ "GenSigTimeoutTime_CVADAS" SG_ 1472 TRSC_VehicleStop_Req 0;
BA_ "GenSigTimeoutTime_ECM" SG_ 1472 TRSC_VehicleStop_Req 0;
BA_ "GenSigTimeoutTime_EPS" SG_ 1472 TRSC_VehicleStop_Req 0;
BA_ "GenSigTimeoutTime_EVCU2" SG_ 1472 TRSC_VehicleStop_Req 0;
BA_ "GenSigTimeoutTime_ORC" SG_ 1472 TRSC_VehicleStop_Req 0;
VAL_ 205 Cmnd_TotBrkFrict_AxleTorq 32767 "SNA";
VAL_ 205 DriverReq_AxleTrq_Enabled_BSM 0 "No_Req" 1 "ACC_NCC" 2 "SSC" 3 "PPPA" 4 "RRCC" 15 "SNA";
VAL_ 205 DriverRequested_AxleTrq_BSM 65535 "SNA";
VAL_ 205 DrvrIntd_TotalBrk_AxleTorq 32767 "SNA";
VAL_ 205 FrontAxle_Max_Rq_BSM 0 "Not_Active" 1 "Active";
VAL_ 205 FrontAxle_Min_Rq_BSM 0 "Not_Active" 1 "Active";
VAL_ 205 FrontAxle_Rq_BSM 65535 "SNA";
VAL_ 205 RearAxle_Max_Rq_BSM 0 "Not_Active" 1 "Active";
VAL_ 205 RearAxle_Min_Rq_BSM 0 "Not_Active" 1 "Active";
VAL_ 205 RearAxle_Rq_BSM 65535 "SNA";
VAL_ 205 TotalAxle_Max_Rq_BSM 0 "Not_Active" 1 "Active";
VAL_ 205 TotalAxle_Min_Rq_BSM 0 "Not_Active" 1 "Active";
VAL_ 205 TotalAxle_Rq_BSM 65535 "SNA";
VAL_ 514 AEB_Type_Brk 0 "NONE" 1 "ACC" 2 "CMS" 3 "CMS_XTD" 4 "ABA" 5 "LSCM" 6 "PEB" 7 "ICA_L" 8 "ICA_R" 9 "HAS_MRM" 10 "RRCC" 15 "SNA";
VAL_ 514 Brake_OpStat_Prim 0 "Inactive" 1 "FullService" 2 "FailOperational" 3 "FailDegraded" 4 "Emergency" 5 "No_Function";
VAL_ 514 BrakePdlPosn 255 "SNA";
VAL_ 514 BrkPdl_Flt 0 "NOT FAULTED" 1 "FAULTED";
VAL_ 514 BrkPdl_Stat 0 "UPSTOP" 1 "PSD" 2 "NDEF2" 3 "SNA";
VAL_ 514 BSM_OpStat 0 "Inactive" 1 "FullService" 2 "FailOperational" 3 "FailDegraded" 4 "Emergency" 5 "No_Function";
VAL_ 514 PAM_Brk_Rq_RspSts 0 "Not_Active" 1 "Active" 2 "Faulted_Condition" 3 "SNA";
VAL_ 257 ABSActive_B2 0 "Not_active" 1 "Active";
VAL_ 257 Brk_Stat_B2 0 "IDLE" 1 "BRAKING" 2 "NDEF2" 3 "SNA";
VAL_ 257 Ft_RrAxleCoupling_TrqRq_B2 255 "SNA";
VAL_ 257 Ft_RrTrqCoupling_ModeRq_B2 0 "FREE" 1 "HOLD" 2 "OPEN" 3 "SNA";
VAL_ 257 Inlet_Pressure_Pos 0 "False" 1 "True" 3 "SNA";
VAL_ 257 LHF_FastPulseCounter_B2 255 "SNA";
VAL_ 257 LHF_Spin_B2 0 "Stand_Still" 1 "Forward" 2 "Backward" 3 "SNA";
VAL_ 257 LHF_WheelSensorFailSts_B2 0 "Fail_Not_Present" 1 "Fail_Present";
VAL_ 257 LHFWheelSpeed_B2 8191 "SNA";
VAL_ 257 R_DIFF_TRQ_RQ_B2 511 "SNA";
VAL_ 257 Rear_Diff_BSM_RQ_B2 0 "FREE" 1 "HOLD" 2 "OPEN" 3 "SNA";
VAL_ 257 RHF_FastPulseCounter_B2 255 "SNA";
VAL_ 257 RHF_Spin_B2 0 "Stand_Still" 1 "Forward" 2 "Backward" 3 "SNA";
VAL_ 257 RHF_WheelSensorFailSts_B2 0 "Fail_Not_Present" 1 "Fail_Present";
VAL_ 257 RHFWheelSpeed_B2 8191 "SNA";
VAL_ 257 VehicleSpeedVSOSig_B2 8191 "SNA";
VAL_ 524 AEB_Type_Brk_B2 0 "NONE" 1 "ACC" 2 "CMS" 3 "CMS_XTD" 4 "ABA" 5 "LSCM" 6 "PEB" 7 "ICA_L" 8 "ICA_R" 9 "HAS_MRM" 15 "SNA";
VAL_ 524 Brake_OpStat_Sec 0 "Inactive" 1 "FullService" 2 "FailOperational" 3 "FailDegraded" 4 "Emergency" 5 "No_Function";
VAL_ 524 BrkTrq_B2 32767 "SNA";
VAL_ 524 BSM2_OpStat 0 "Inactive" 1 "FullService" 2 "FailOperational" 3 "FailDegraded" 4 "Emergency" 5 "No_Function";
VAL_ 524 VehicleStandStillSts_B2 0 "True" 1 "False" 3 "SNA";
VAL_ 1156 ABSFailSts_B2 0 "Fail_Not_Present" 1 "Fail_Present";
VAL_ 1156 RollsModeAct_B2 0 "No Fault" 1 "Fault";
VAL_ 275 ManoeuvrePhase 0 "Backward" 1 "Forward";
VAL_ 275 ParkingGearShiftReq 0 "Idle" 1 "P" 2 "R" 3 "N" 4 "D" 5 "Not_Used" 6 "Not_Used" 7 "SNA";
VAL_ 275 PPPA_Interface_BSM 0 "Idle" 1 "CVPAM_Request" 2 "Faulted" 3 "SNA";
VAL_ 275 PPPA_MaxSpeed 255 "SNA";
VAL_ 275 PPPA_StandstillRqst 0 "Not_Active" 1 "Active";
VAL_ 275 PPPA_TargetDistance 1023 "SNA";
VAL_ 275 RR_PAM_Brk_RqSts 0 "Off" 1 "On";
VAL_ 275 RR_PAM_Dist 1023 "SNA";
VAL_ 275 SPM_Lat_Ctrl_RequestSts 0 "IDLE" 1 "Faulted" 2 "SPM_Request";
VAL_ 950 ParkingManeuverActive 0 "Idle" 1 "Enabled_Seeking" 2 "Engaged_Semi" 3 "Engaged_Full" 4 "Not_Used" 5 "Not_Used" 6 "Not_Used" 7 "SNA";
VAL_ 1054 ThermalManagementActive_W 0 "Not_active" 1 "Active";
VAL_ 262 ECM_LHOM_W 0 "Not_In_Limp_Home" 1 "In_Limp_Home";
VAL_ 262 EngineSpeed_W 16383 "SNA";
VAL_ 262 EngineSts_W 0 "Engine_Off" 1 "Engine_Cranking" 2 "Engine_On" 3 "SNA";
VAL_ 262 ESS_ENG_ST_W 1 "ENS Stopped / ENS_STOPPED" 2 "ENS Request Start / ENS_RQ_ST" 3 "ENS Running / ENS_RUN" 4 "ENS Stop Pending / ENS_STOP_PEND" 5 "ENS Start protection / ENS_ST_PRTCT" 6 "ENS Start inhibit / ENS_ST_INH" 7 "ENS disabled / ENS_DSBL" 8 "ENS_IHB_LATCH" 9 "ENS Starting / ENS_Starting" 15 "SNA";
VAL_ 262 GasPedalPosition_W 255 "SNA";
VAL_ 262 GasPedalPositionFailSts_W 0 "Fail_not_present" 1 "Fail_present";
VAL_ 262 LV12PwrFreeRq_W 0 "Level 1 or 2 Power free Mode NOT active" 1 "Level 1 or 2 Power free Mode Active";
VAL_ 262 PowertrainPrplsnActv 0 "Off" 1 "Active";
VAL_ 518 PdlPosActual 255 "SNA";
VAL_ 518 RPMOverRev_W 0 "FALSE" 1 "TRUE";
VAL_ 1448 ECM_THA_Resp 0 "Off" 1 "Active" 3 "SNA";
VAL_ 1448 ECM_TRSC_Resp 0 "OFF" 1 "Active" 3 "SNA";
VAL_ 264 ElectricSteeringFailSts 0 "Fail_Not_Present" 1 "Fail_Present";
VAL_ 264 EngineFanRequestActivation 0 "False" 1 "True";
VAL_ 264 EPS_ADAS_IMC_Fault 0 "No_Fault" 1 "Fault";
VAL_ 264 EPS_AsstStat 0 "AST_ACT" 1 "AST_OFF" 2 "AST_RT" 7 "SNA";
VAL_ 264 EPS_Curr 255 "SNA";
VAL_ 264 EPS_Hands_On_Sts 0 "Not_Detected" 1 "Detected";
VAL_ 264 EPS_HandsOnRecognition 0 "False" 1 "True";
VAL_ 264 EPSMotorTorque 2047 "SNA";
VAL_ 264 ESA_LAT_CTRL_ResponseSts 0 "IDLE" 1 "Permanently_Not_Avail" 2 "Temporarily_Not_Avail" 3 "ESA_Open" 4 "ESA_Open_Backup" 5 "INIT" 6 "Damped_Exit" 7 "SNA";
VAL_ 264 HAS_LAT_CTRL_ResponseSts 0 "IDLE" 1 "Permanent_Not_Avail" 2 "Temporarily_Not_Avail" 3 "HAS_Open" 4 "HAS_Open_Backup" 5 "INIT" 6 "Damped_Exit" 7 "Faulted";
VAL_ 264 LKA_LAT_CTRL_ResponseSts 0 "IDLE" 1 "Permanent_Not_Avail" 2 "Temporarily_Not_Avail" 3 "LKA_Open";
VAL_ 264 LwsAngle 65535 "SNA";
VAL_ 264 LwsAngleType 0 "Absolute" 1 "Relative" 3 "SNA";
VAL_ 264 LwsCalibration 0 "Not_calibrated" 1 "Calibrated";
VAL_ 264 LwsSpeed 4095 "SNA";
VAL_ 264 SPM_Lat_Ctrl_ResponseSts 0 "IDLE" 1 "Permanent_Not_Avail" 2 "Temporarily_Not_Avail" 3 "SPM_Open";
VAL_ 264 Steering_Column_Torque 2047 "SNA";
VAL_ 264 Steering_OpStat_Prim 0 "Inactive" 1 "FullService" 2 "FailOperational" 3 "FailDegraded" 4 "Emergency" 5 "No_Function";
VAL_ 264 SteeringVibration_Fault 0 "NO_FAULT" 1 "FAULTED";
VAL_ 264 SteeringVibration_Status 0 "Inactive" 1 "Active";
VAL_ 1056 EPS_MODE_STAT 0 "MODE_1" 1 "MODE_2" 2 "MODE_3" 3 "LAST" 7 "SNA";
VAL_ 1056 EPS_SteeringTouchStat 0 "False" 1 "True";
VAL_ 1056 EPS_SteeringTouq_Resp 0 "OFF" 1 "Active" 3 "SNA";
VAL_ 1056 EPS_THA_DriverTorqueOverride 0 "False" 1 "True" 3 "SNA";
VAL_ 1056 EPS_THA_SteeringTorqueResp 0 "Temp_NA" 1 "Perm_NA" 2 "TOI_Available" 3 "TOI_Unavailable" 7 "SNA";
VAL_ 1056 EPS_Warn_Disp_Rq 0 "EPS function active OK" 1 "Warning - Service power steering ERR" 2 "Warning - Power steering-over temp ERR2" 3 "Service Required - High Priority SERV_HI" 7 "SNA";
VAL_ 1056 THA_SteeringTouchStat 0 "Hands Off" 1 "Hands On" 3 "SNA";
VAL_ 276 DriveModeSts_EPT 0 "Drive_Mode_Unavailable" 1 "Eco_Drive" 2 "Sport_Hybrid" 3 "Extend" 4 "ESave" 8 "Electric" 15 "SNA";
VAL_ 1626 IMPACT_B 0 "Do_Not_Actuate" 1 "Actuate";
VAL_ 1626 IMPACT_C 0 "Do_Not_Actuate" 1 "Actuate";
VAL_ 1626 IMPACT_F 0 "Do_Not_Actuate" 1 "Actuate";
VAL_ 1626 IMPACT_I 0 "Do_Not_Actuate" 1 "Actuate";
VAL_ 1626 IMPACT_K 0 "Do_Not_Actuate" 1 "Actuate";
VAL_ 1626 IMPACT_M 0 "Do_Not_Actuate" 1 "Actuate";
VAL_ 1626 IMPACTCommand 0 "Do_Not_Actuate" 1 "Actuate";
VAL_ 1626 IMPACTConfirm 0 "Actuate" 1 "Do_Not_Actuate";
VAL_ 1626 IMPACTFailSts 0 "Fail_Not_Present" 1 "Fail_Present";
VAL_ 1626 IMPACTThreshold 0 "Threshold_Not_Met" 1 "Threshold_Met";
VAL_ 2654486534 CBV_bit0_RepeatMessageRequestBit 0 "Repeat_Message_State_not_requested" 1 "Repeat_Message_State_requested";
VAL_ 2654486534 CBV_bit3_NMCoordinatorBit 0 "Start_of_synchronized_shutdown_is_not_requested_by_main_coordinator" 1 "Start_of_synchronized_shutdown_is_requested_by_main_coordinator";
VAL_ 2654486534 CBV_bit4_ActiveWakeupBit 0 "PassiveWakeup" 1 "ActiveWakeup";
VAL_ 2654486534 CBV_bit6_PartialNtwInfBit 0 "NM_PDU_contains_no_Partial_Network_request_information" 1 "NM_PDU_contains_Partial_Network_request_information";
VAL_ 2654486676 CBV_bit0_RepeatMessageRequestBit 0 "Repeat_Message_State_not_requested" 1 "Repeat_Message_State_requested";
VAL_ 2654486676 CBV_bit3_NMCoordinatorBit 0 "Start_of_synchronized_shutdown_is_not_requested_by_main_coordinator" 1 "Start_of_synchronized_shutdown_is_requested_by_main_coordinator";
VAL_ 2654486676 CBV_bit4_ActiveWakeupBit 0 "PassiveWakeup" 1 "ActiveWakeup";
VAL_ 2654486676 CBV_bit6_PartialNtwInfBit 0 "NM_PDU_contains_no_Partial_Network_request_information" 1 "NM_PDU_contains_Partial_Network_request_information";
VAL_ 2654486669 CBV_bit0_RepeatMessageRequestBit 0 "Repeat_Message_State_not_requested" 1 "Repeat_Message_State_requested";
VAL_ 2654486669 CBV_bit3_NMCoordinatorBit 0 "Start_of_synchronized_shutdown_is_not_requested_by_main_coordinator" 1 "Start_of_synchronized_shutdown_is_requested_by_main_coordinator";
VAL_ 2654486669 CBV_bit4_ActiveWakeupBit 0 "PassiveWakeup" 1 "ActiveWakeup";
VAL_ 2654486669 CBV_bit6_PartialNtwInfBit 0 "NM_PDU_contains_no_Partial_Network_request_information" 1 "NM_PDU_contains_Partial_Network_request_information";
VAL_ 2654486529 CBV_bit0_RepeatMessageRequestBit 0 "Repeat_Message_State_not_requested" 1 "Repeat_Message_State_requested";
VAL_ 2654486529 CBV_bit3_NMCoordinatorBit 0 "Start_of_synchronized_shutdown_is_not_requested_by_main_coordinator" 1 "Start_of_synchronized_shutdown_is_requested_by_main_coordinator";
VAL_ 2654486529 CBV_bit4_ActiveWakeupBit 0 "PassiveWakeup" 1 "ActiveWakeup";
VAL_ 2654486529 CBV_bit6_PartialNtwInfBit 0 "NM_PDU_contains_no_Partial_Network_request_information" 1 "NM_PDU_contains_Partial_Network_request_information";
VAL_ 2654486530 CBV_bit0_RepeatMessageRequestBit 0 "Repeat_Message_State_not_requested" 1 "Repeat_Message_State_requested";
VAL_ 2654486530 CBV_bit3_NMCoordinatorBit 0 "Start_of_synchronized_shutdown_is_not_requested_by_main_coordinator" 1 "Start_of_synchronized_shutdown_is_requested_by_main_coordinator";
VAL_ 2654486530 CBV_bit4_ActiveWakeupBit 0 "PassiveWakeup" 1 "ActiveWakeup";
VAL_ 2654486530 CBV_bit6_PartialNtwInfBit 0 "NM_PDU_contains_no_Partial_Network_request_information" 1 "NM_PDU_contains_Partial_Network_request_information";
VAL_ 2654486592 CBV_bit4_ActiveWakeupBit 0 "PassiveWakeup" 1 "ActiveWakeup";
VAL_ 2654486554 CBV_bit0_RepeatMessageRequestBit 0 "Repeat Message State not requested" 1 "Repeat Message State requested";
VAL_ 2654486554 CBV_bit3_NMCoordinatorBit 0 "Start of synchronized shutdown is not requested by main coordinator" 1 "Start of synchronized shutdown is requested by main coordinator";
VAL_ 2654486554 CBV_bit4_ActiveWakeupBit 0 "PassiveWakeup" 1 "ActiveWakeup";
VAL_ 2654486554 CBV_bit6_PartialNtwInfBit 0 "NM PDU contains no Partial Network request information" 1 "NM PDU contains Partial Network request information";
VAL_ 2654486552 CBV_bit0_RepeatMessageRequestBit 0 "Repeat_Message_State_not_requested" 1 "Repeat_Message_State_requested";
VAL_ 2654486552 CBV_bit3_NMCoordinatorBit 0 "Start_of_synchronized_shutdown_is_not_requested_by_main_coordinator" 1 "Start_of_synchronized_shutdown_is_requested_by_main_coordinator";
VAL_ 2654486552 CBV_bit4_ActiveWakeupBit 0 "PassiveWakeup" 1 "ActiveWakeup";
VAL_ 2654486552 CBV_bit6_PartialNtwInfBit 0 "NM_PDU_contains_no_Partial_Network_request_information" 1 "NM_PDU_contains_Partial_Network_request_information";
VAL_ 611 SBR1RowDriverSeatSts 0 "Seat_Belt_Fasten" 1 "Seat_Belt_Not_Fasten" 3 "SNA";
VAL_ 274 InternalError 0 "No_int_processing_error_detected" 1 "Int_processing_error_detected";
VAL_ 274 LatAcceleration 4095 "SNA";
VAL_ 274 LatAccelerationFailSts 0 "Fail_Not_Present" 1 "Fail_Present";
VAL_ 274 LongAcceleration 4095 "SNA";
VAL_ 274 LongAccelerationFailSts 0 "Fail_Not_Present" 1 "Fail_Present";
VAL_ 274 YawRate 4095 "SNA";
VAL_ 274 YawRate_HR_Sign 0 "Negative" 1 "Positive";
VAL_ 274 YawRateFailSts 0 "Fail_Not_Present" 1 "Fail_Present";
VAL_ 263 DriveReady_PT 0 "Default" 1 "Veh_Allwd_Shift_Out_Of_P_Or_N";
VAL_ 263 EVCU2_THA_Resp 0 "Off" 1 "Active" 3 "SNA";
VAL_ 263 GasPedalPosition_PT 255 "SNA";
VAL_ 263 GasPedalPositionFailSts_PT 0 "Fail_not_present" 1 "Fail_present";
VAL_ 263 GearEngaged_PT 0 "Neutral" 1 "ForwardGear_1" 2 "ForwardGear_2" 3 "ForwardGear_3" 4 "ForwardGear_4" 5 "ForwardGear_5" 6 "ForwardGear_6" 7 "ForwardGear_7" 8 "ForwardGear_8" 9 "ForwardGear_9" 13 "Parking" 14 "ReverseGear" 15 "SNA";
VAL_ 263 GearEngagedForDisplay_PT 0 "Initialize" 1 "Gear_1st" 2 "Gear_2nd" 3 "Gear_3rd" 4 "Gear_4th" 5 "Gear_5th" 6 "Gear_6th" 7 "Gear_7th" 8 "Gear_8th" 9 "Gear_9th" 12 "Park" 13 "Neutral" 14 "Reverse" 15 "Drive" 16 "Low" 17 "Manual" 18 "Sport_Mode" 31 "SNA";
VAL_ 263 PdlPosActual_PT 255 "SNA";
VAL_ 263 PowertrainPrplsnActv_PT 0 "Not_Active" 1 "Active";
VAL_ 263 ShiftLeverPosition_PT 0 "No_Selection_Active_Or_Available" 1 "Park" 2 "Reverse" 3 "Neutral" 4 "Drive" 5 "Low" 6 "TIP_Autostick" 7 "Plus" 8 "Minus" 9 "Sport" 15 "SNA";
VAL_ 263 TargetGear_PT 0 "Neutral" 1 "ForwardGear_1" 2 "ForwardGear_2" 3 "ForwardGear_3" 4 "ForwardGear_4" 5 "ForwardGear_5" 6 "ForwardGear_6" 7 "ForwardGear_7" 8 "ForwardGear_8" 9 "ForwardGear_9" 13 "Parking" 14 "ReverseGear" 15 "SNA";
VAL_ 255 ACC_NCC_TrqEnblRq_Allowed 0 "FALSE" 1 "TRUE";
VAL_ 255 Accel_Pedal_Override 0 "FALSE" 1 "TRUE";
VAL_ 255 ESC_TrqEnblRq_Allowed 0 "FALSE" 1 "TRUE";
VAL_ 255 Front_AxleTorque_Static 65535 "SNA";
VAL_ 255 PPPA_TrqEnblRq_Allowed 0 "FALSE" 1 "TRUE";
VAL_ 255 Rear_AxleTorque_Static 65535 "SNA";
VAL_ 255 RRCC_TrqEnblRq_Allowed 0 "FALSE" 1 "TRUE";
VAL_ 255 SSC_TrqEnblRq_Allowed 0 "FALSE" 1 "TRUE";
VAL_ 255 SumTorque_DrvReqMod 8191 "SNA";
VAL_ 255 SumTorqueExp 2047 "SNA";
VAL_ 255 SumTorqueMax 2047 "SNA";
VAL_ 255 SumTorqueMin 2047 "SNA";
VAL_ 255 SumTorqueSel_D_TTC 2047 "SNA";
VAL_ 255 SumTorqueStatic 2047 "SNA";
VAL_ 255 Total_AxleTorque_Static 65535 "SNA";
VAL_ 1472 THA_EPB_Req 0 "No_Request" 1 "EPB_Requested" 3 "SNA";
VAL_ 1472 THA_Speed_Limit 0 "No_Request" 1 "kph_1" 2 "kph_2" 3 "kph_3" 4 "kph_4" 5 "kph_5" 6 "kph_6" 7 "kph_7" 8 "kph_8" 9 "kph_9" 10 "kph_10" 31 "SNA";
VAL_ 1472 THA_SpeedLimit_Req 0 "No_Request" 1 "Requested" 3 "SNA";
VAL_ 1472 THA_STAT 0 "Initial" 1 "Idle" 2 "Enabled" 3 "Engaged" 4 "Complete" 5 "Faulted " 7 "SNA";
VAL_ 1472 THA_SteeringTorqueReq 0 "False" 1 "True" 3 "SNA";
VAL_ 1472 TRSC_SpeedLimit_Req 0 "Not_Limiting" 1 "SPD_4" 2 "SPD_5" 3 "SPD_6" 4 "SPD_7" 5 "SPD_8" 6 "SPD_9" 7 "SPD_10" 15 "SNA";
VAL_ 1472 TRSC_STAT 0 "Standby" 1 "Calibrating" 2 "PreActive" 3 "Active" 4 "OFF" 7 "SNA";
VAL_ 1472 TRSC_SteeringDamping 255 "SNA";
VAL_ 1472 TRSC_SteeringTorqueReq 0 "False" 1 "True" 3 "SNA";
VAL_ 1472 TRSC_VehicleStop_Req 0 "False" 1 "True" 3 "SNA";
